VERSION "HNNBNNNYNNNNNNNNNNNNNNNNNNNNNNNNNNNNNNNNNN/4/%%%/4/'%**4NNN///"

NS_ :

BS_:

BU_: BAP_Tester Gateway_Max Getriebe_DQ Motor_konv Parksperre Schaltbetaetigung

BO_ 1171 MFG_01: 8 Gateway_Max
 SG_ MFG_01_CRC : 0|8@1+ (1,0) [0|255] ""  Motor_konv
 SG_ MFG_01_BZ : 8|4@1+ (1,0) [0|15] ""  Motor_konv
 SG_ MF_ZV_Lock : 12|1@1+ (1.0,0.0) [0.0|1] ""  Vector__XXX
 SG_ MF_Motorweiterlauf : 13|1@1+ (1.0,0.0) [0.0|1] ""  Vector__XXX
 SG_ MF_Abzugssperre : 14|1@1+ (1.0,0.0) [0.0|1] ""  Vector__XXX
 SG_ MF_Anlassersperre : 15|1@1+ (1.0,0.0) [0.0|1] ""  Motor_konv
 SG_ MF_Variante : 16|3@1+ (1.0,0.0) [0.0|7] ""  Vector__XXX
 SG_ MF_Schluessel_scan : 19|1@1+ (1.0,0.0) [0.0|1] ""  Vector__XXX
 SG_ MF_Laderelais : 20|1@1+ (1.0,0.0) [0.0|1] ""  Vector__XXX
 SG_ MF_StartStopp_Info : 21|2@1+ (1.0,0.0) [0.0|3] ""  Motor_konv
 SG_ MF_Fernbed_ein : 23|1@1+ (1.0,0.0) [0.0|1] ""  Vector__XXX
 SG_ MF_Standlicht : 24|1@1+ (1.0,0.0) [0.0|1] ""  Vector__XXX
 SG_ MF_Fahrlicht : 25|1@1+ (1.0,0.0) [0.0|1] ""  Vector__XXX
 SG_ MF_interm_Fernlicht : 26|1@1+ (1.0,0.0) [0.0|1] ""  Vector__XXX
 SG_ MF_Warnblinker : 27|1@1+ (1.0,0.0) [0.0|1] ""  Vector__XXX
 SG_ MF_Fussraumbel : 28|1@1+ (1.0,0.0) [0.0|1] ""  Vector__XXX
 SG_ MF_Innenraumbel : 29|1@1+ (1.0,0.0) [0.0|1] ""  Vector__XXX
 SG_ MF_Innenraumbel_Unterdrueck : 30|1@1+ (1.0,0.0) [0.0|1] ""  Vector__XXX
 SG_ MF_Notstart : 31|1@1+ (1.0,0.0) [0.0|1] ""  Vector__XXX
 SG_ MF_Blk_li : 32|1@1+ (1.0,0.0) [0.0|1] ""  Vector__XXX
 SG_ MF_Blk_re : 33|1@1+ (1.0,0.0) [0.0|1] ""  Vector__XXX
 SG_ MF_Lichthupe : 34|1@1+ (1.0,0.0) [0.0|1] ""  Vector__XXX
 SG_ MF_Fernlicht : 35|1@1+ (1.0,0.0) [0.0|1] ""  Vector__XXX
 SG_ MF_HFS_verriegeln : 36|1@1+ (1.0,0.0) [0.0|1] ""  Vector__XXX
 SG_ MF_HFS_entriegeln : 37|1@1+ (1.0,0.0) [0.0|1] ""  Vector__XXX
 SG_ MF_HBFS_verriegeln : 38|1@1+ (1.0,0.0) [0.0|1] ""  Vector__XXX
 SG_ MF_HBFS_entriegeln : 39|1@1+ (1.0,0.0) [0.0|1] ""  Vector__XXX
 SG_ MF_Tippwischen : 40|1@1+ (1.0,0.0) [0.0|1] ""  Vector__XXX
 SG_ MF_Frontintervall : 41|1@1+ (1.0,0.0) [0.0|1] ""  Vector__XXX
 SG_ MF_Wischerstufe_1 : 42|1@1+ (1.0,0.0) [0.0|1] ""  Vector__XXX
 SG_ MF_Wischerstufe_2 : 43|1@1+ (1.0,0.0) [0.0|1] ""  Vector__XXX
 SG_ MF_Frontwaschen : 44|1@1+ (1.0,0.0) [0.0|1] ""  Vector__XXX
 SG_ MF_nachtr_Stopp_Anf : 45|1@1+ (1.0,0.0) [0.0|1] ""  Motor_konv
 SG_ MF_Heckintervall : 46|1@1+ (1.0,0.0) [0.0|1] ""  Vector__XXX
 SG_ MF_Heckwaschen : 47|1@1+ (1.0,0.0) [0.0|1] ""  Vector__XXX
 SG_ MF_Summer : 48|1@1+ (1.0,0.0) [0.0|1] ""  Vector__XXX
 SG_ MF_Alarm_Blinkertakt : 49|1@1+ (1.0,0.0) [0.0|1] ""  Vector__XXX
 SG_ MF_Alarm_Blinker : 50|1@1+ (1.0,0.0) [0.0|1] ""  Vector__XXX
 SG_ MF_TFL_Abschaltung : 51|1@1+ (1.0,0.0) [0.0|1] ""  Vector__XXX
 SG_ MF_interm_Takt : 52|1@1+ (1.0,0.0) [0.0|1] ""  Vector__XXX
 SG_ MF_Tuerentriegelung_hinten : 53|1@1+ (1.0,0.0) [0.0|1] ""  Vector__XXX
 SG_ MF_interm_Fahrlicht : 54|1@1+ (1.0,0.0) [0.0|1] ""  Vector__XXX
 SG_ MF_Signalhorn : 55|1@1+ (1.0,0.0) [0.0|1] ""  Vector__XXX
 SG_ MF_FH_FT_hoch : 56|1@1+ (1.0,0.0) [0.0|1] ""  Vector__XXX
 SG_ MF_FH_FT_tief : 57|1@1+ (1.0,0.0) [0.0|1] ""  Vector__XXX
 SG_ MF_FH_BT_hoch : 58|1@1+ (1.0,0.0) [0.0|1] ""  Vector__XXX
 SG_ MF_FH_BT_tief : 59|1@1+ (1.0,0.0) [0.0|1] ""  Vector__XXX
 SG_ MF_FT_verriegeln : 60|1@1+ (1.0,0.0) [0.0|1] ""  Vector__XXX
 SG_ MF_FT_entriegeln : 61|1@1+ (1.0,0.0) [0.0|1] ""  Vector__XXX
 SG_ MF_BT_verriegeln : 62|1@1+ (1.0,0.0) [0.0|1] ""  Vector__XXX
 SG_ MF_BT_entriegeln : 63|1@1+ (1.0,0.0) [0.0|1] ""  Vector__XXX

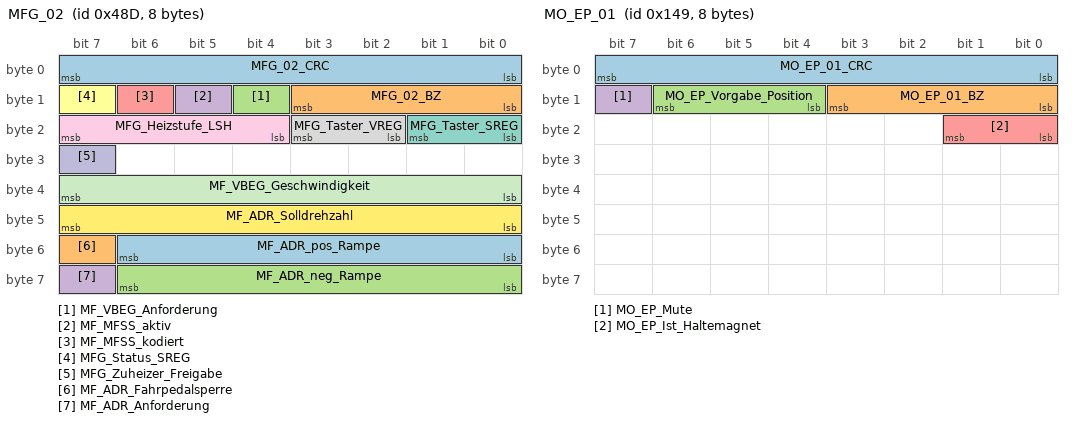
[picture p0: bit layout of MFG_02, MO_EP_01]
BO_ 1165 MFG_02: 8 Gateway_Max
 SG_ MFG_02_CRC : 0|8@1+ (1,0) [0|255] ""  Motor_konv
 SG_ MFG_02_BZ : 8|4@1+ (1,0) [0|15] ""  Motor_konv
 SG_ MF_VBEG_Anforderung : 12|1@1+ (1.0,0.0) [0.0|1] ""  Motor_konv
 SG_ MF_MFSS_aktiv : 13|1@1+ (1.0,0.0) [0.0|1] ""  Motor_konv
 SG_ MF_MFSS_kodiert : 14|1@1+ (1.0,0.0) [0.0|1] ""  Motor_konv
 SG_ MFG_Status_SREG : 15|1@1+ (1.0,0.0) [0.0|1] ""  Motor_konv
 SG_ MFG_Taster_SREG : 16|2@1+ (1.0,0.0) [0.0|3] ""  Motor_konv
 SG_ MFG_Taster_VREG : 18|2@1+ (1.0,0.0) [0.0|3] ""  Motor_konv
 SG_ MFG_Heizstufe_LSH : 20|4@1+ (1.0,0.0) [0.0|15] ""  Vector__XXX
 SG_ MFG_Zuheizer_Freigabe : 31|1@1+ (1.0,0.0) [0.0|1] ""  Vector__XXX
 SG_ MF_VBEG_Geschwindigkeit : 32|8@1+ (1,0) [0|254] "Unit_KiloMeterPerHour"  Motor_konv
 SG_ MF_ADR_Solldrehzahl : 40|8@1+ (20,0) [0|5100] "Unit_MinutInver"  Motor_konv
 SG_ MF_ADR_pos_Rampe : 48|7@1+ (10,0) [0|1000] ""  Motor_konv
 SG_ MF_ADR_Fahrpedalsperre : 55|1@1+ (1.0,0.0) [0.0|1] ""  Motor_konv
 SG_ MF_ADR_neg_Rampe : 56|7@1+ (10,0) [0|1000] ""  Motor_konv
 SG_ MF_ADR_Anforderung : 63|1@1+ (1.0,0.0) [0.0|1] ""  Motor_konv

BO_ 817 MFL_01: 8 Gateway_Max
 SG_ MFL_Zaehler : 0|4@1+ (1,0) [0|15] ""  Vector__XXX
 SG_ MFL_Toggle : 4|1@1+ (1,0) [0|1] ""  Vector__XXX
 SG_ MFL_Lokalaktiv : 5|1@1+ (1.0,0.0) [0.0|1] ""  Vector__XXX
 SG_ MFL_M_Taste : 6|1@1+ (1.0,0.0) [0.0|1] ""  Vector__XXX
 SG_ MFL_Paddle_Verbau : 7|1@1+ (1.0,0.0) [0.0|1] ""  Vector__XXX
 SG_ MFL_Tastencode_1 : 8|8@1+ (1.0,0.0) [0.0|255] ""  Vector__XXX
 SG_ MFL_Tastencode_2 : 16|8@1+ (1.0,0.0) [0.0|255] ""  Vector__XXX
 SG_ MFL_Eventcode_1 : 24|4@1+ (1.0,0.0) [0.0|15] ""  Vector__XXX
 SG_ MFL_Eventcode_2 : 28|4@1+ (1.0,0.0) [0.0|15] ""  Vector__XXX
 SG_ MFL_Marke : 32|4@1+ (1.0,0.0) [0.0|15] ""  Vector__XXX
 SG_ MFL_Variante : 36|4@1+ (1,0) [0|15] ""  Vector__XXX
 SG_ MFL_Touch_Event : 40|4@1+ (1.0,0.0) [0.0|15] ""  Vector__XXX
 SG_ MFL_Dummy_0_Signal_4 : 44|4@1+ (1.0,0.0) [0.0|15] ""  Vector__XXX
 SG_ MFL_Tip_Down : 48|1@1+ (1.0,0.0) [0.0|1] ""  Getriebe_DQ,Motor_konv
 SG_ MFL_Tip_Up : 49|1@1+ (1.0,0.0) [0.0|1] ""  Getriebe_DQ,Motor_konv
 SG_ MFL_SatModul_links_Err : 50|1@1+ (1.0,0.0) [0.0|1] ""  Vector__XXX
 SG_ MFL_SatModul_rechts_Err : 51|1@1+ (1.0,0.0) [0.0|1] ""  Vector__XXX
 SG_ MFL_Dummy_0_Signal_2 : 52|1@1+ (1.0,0.0) [0.0|1] ""  Vector__XXX
 SG_ MFL_Dummy_0_Signal_3 : 53|1@1+ (1.0,0.0) [0.0|1] ""  Vector__XXX
 SG_ MFL_LR_HZG_Status : 54|1@1+ (1.0,0.0) [0.0|1] ""  Vector__XXX
 SG_ MFL_LR_HZG_Err : 55|1@1+ (1.0,0.0) [0.0|1] ""  Vector__XXX
 SG_ MFL_Signalhorn : 56|1@1+ (1.0,0.0) [0.0|1] ""  Vector__XXX
 SG_ MFL_Signalhorn_Err : 57|1@1+ (1.0,0.0) [0.0|1] ""  Vector__XXX
 SG_ MFL_Tip_links_Err : 58|1@1+ (1.0,0.0) [0.0|1] ""  Getriebe_DQ
 SG_ MFL_Tip_rechts_Err : 59|1@1+ (1.0,0.0) [0.0|1] ""  Getriebe_DQ
 SG_ MFL_Taste_links_Err : 60|1@1+ (1.0,0.0) [0.0|1] ""  Vector__XXX
 SG_ MFL_Taste_rechts_Err : 61|1@1+ (1.0,0.0) [0.0|1] ""  Vector__XXX
 SG_ MFL_ECU_Err : 62|1@1+ (1.0,0.0) [0.0|1] ""  Vector__XXX
 SG_ MFL_Response_Err : 63|1@1+ (1.0,0.0) [0.0|1] ""  Vector__XXX

BO_ 329 MO_EP_01: 8 Getriebe_DQ
 SG_ MO_EP_01_CRC : 0|8@1+ (1,0) [0|255] ""  Parksperre
 SG_ MO_EP_01_BZ : 8|4@1+ (1,0) [0|15] ""  Parksperre
 SG_ MO_EP_Vorgabe_Position : 12|3@1+ (1.0,0.0) [0.0|7] ""  Parksperre
 SG_ MO_EP_Mute : 15|1@1+ (1.0,0.0) [0.0|1] ""  Parksperre
 SG_ MO_EP_Ist_Haltemagnet : 16|2@1+ (1.0,0.0) [0.0|3] ""  Vector__XXX

BO_ 15 MO_SOPC: 1 Motor_konv
 SG_ MO_SOPC : 0|1@1+ (1.0,0.0) [0.0|1] ""  Vector__XXX

BO_ 1600 Motor_07: 8 Motor_konv
 SG_ MO_QBit_Ansaugluft_Temp : 0|1@1+ (1.0,0.0) [0.0|1] ""  Gateway_Max,Getriebe_DQ
 SG_ MO_QBit_Oel_Temp : 1|1@1+ (1.0,0.0) [0.0|1] ""  Gateway_Max,Getriebe_DQ
 SG_ MO_QBit_Kuehlmittel_Temp : 2|1@1+ (1.0,0.0) [0.0|1] ""  Gateway_Max,Getriebe_DQ
 SG_ MO_KL15_Abschaltempfehlung : 3|1@1+ (1.0,0.0) [0.0|1] ""  Gateway_Max
 SG_ MO_HYB_Fehler_HV_Netz : 4|1@1+ (1.0,0.0) [0.0|1] ""  Gateway_Max
 SG_ MO_aktives_Getriebeheizen : 5|1@1+ (1.0,0.0) [0.0|1] ""  Gateway_Max
 SG_ MO_Absperrventil_oeffnen : 6|2@1+ (1.0,0.0) [0.0|3] ""  Gateway_Max,Getriebe_DQ
 SG_ MO_Ansaugluft_Temp : 8|8@1+ (0.75,-48) [-48.00|141.75] "Unit_DegreCelsi"  Gateway_Max,Getriebe_DQ
 SG_ MO_Oel_Temp : 16|8@1+ (1,-60) [-60|192] "Unit_DegreCelsi"  Gateway_Max,Getriebe_DQ
 SG_ MO_Kuehlmittel_Temp : 24|8@1+ (0.75,-48) [-48.00|141.75] "Unit_DegreCelsi"  Gateway_Max,Getriebe_DQ
 SG_ MO_Hoeheninfo : 32|8@1+ (0.00781,0) [0.00000|1.98374] ""  Gateway_Max,Getriebe_DQ
 SG_ MO_Kennfeldk : 40|1@1+ (1.0,0.0) [0.0|1] ""  Gateway_Max
 SG_ MO_Versionsinfo_02 : 41|5@1+ (1.0,0.0) [0.0|31] ""  Gateway_Max
 SG_ MO_QBit_Hoeheninfo : 46|1@1+ (1.0,0.0) [0.0|1] ""  Gateway_Max
 SG_ MO_Getriebe_kuehlen : 47|1@1+ (1.0,0.0) [0.0|1] ""  Gateway_Max,Getriebe_DQ
 SG_ MO_Mom_Traegheit_02 : 48|5@1+ (0.01,0) [0.00|0.31] "Unit_KiloGramMeterSquar"  Gateway_Max
 SG_ MO_Heizungspumpenansteuerung : 53|4@1+ (10,0) [0|100] "Unit_PerCent"  Gateway_Max
 SG_ MO_SpannungsAnf : 57|1@1+ (1.0,0.0) [0.0|1] ""  Gateway_Max
 SG_ MO_Nachlaufzeit_Heizungspumpe : 58|6@1+ (15,0) [0|945] "Unit_Secon"  Gateway_Max

BO_ 1607 Motor_09: 8 Motor_konv
 SG_ MO_ITM_Kuehlmittel_Temp : 0|8@1+ (0.75,-48) [-45.75|143.25] "Unit_DegreCelsi"  Gateway_Max
 SG_ MO_E85_Sensor : 8|4@1+ (10,0) [0|100] "Unit_PerCent"  Gateway_Max
 SG_ SCR_Anz_Motorstarts : 12|4@1+ (1.0,0.0) [0.0|15] ""  Gateway_Max
 SG_ SCR_Reichweite : 16|15@1+ (1,0) [0|32766] "Unit_KiloMeter"  Gateway_Max
 SG_ MO_Ethanol_Spuelhinweis : 31|1@1+ (1.0,0.0) [0.0|1] ""  Gateway_Max
 SG_ SCR_Warnstufe_1 : 32|1@1+ (1.0,0.0) [0.0|1] ""  Gateway_Max
 SG_ SCR_Warnstufe_2 : 33|1@1+ (1.0,0.0) [0.0|1] ""  Gateway_Max
 SG_ SCR_Text : 34|3@1+ (1.0,0.0) [0.0|7] ""  Gateway_Max
 SG_ SCR_Akustik : 37|2@1+ (1.0,0.0) [0.0|3] ""  Gateway_Max
 SG_ SCR_verbaut : 39|1@1+ (1.0,0.0) [0.0|1] ""  Gateway_Max
 SG_ MO_Kraftstofffilter_Wasser : 40|1@1+ (1.0,0.0) [0.0|1] ""  Gateway_Max
 SG_ SCR_Systemfehler : 41|1@1+ (1.0,0.0) [0.0|1] ""  Gateway_Max
 SG_ SCR_Inducement_Strategie : 42|2@1+ (1.0,0.0) [0.0|3] ""  Gateway_Max
 SG_ MO_CO2_Faktor : 44|12@1+ (1,0) [1|4094] "Unit_GramPerLiter"  Gateway_Max
 SG_ MO_MKB_MUX M  : 56|2@1+ (1.0,0.0) [0.0|3] ""  Gateway_Max
 SG_ MO_MKB_01 m0  : 59|5@1+ (1.0,0.0) [0.0|31] ""  Gateway_Max
 SG_ MO_MKB_02 m1  : 59|5@1+ (1.0,0.0) [0.0|31] ""  Gateway_Max
 SG_ MO_MKB_03 m2  : 59|5@1+ (1.0,0.0) [0.0|31] ""  Gateway_Max
 SG_ MO_MKB_04 m3  : 59|5@1+ (1.0,0.0) [0.0|31] ""  Gateway_Max

BO_ 958 Motor_14: 8 Motor_konv
 SG_ Motor_14_CRC : 0|8@1+ (1,0) [0|255] ""  Gateway_Max
 SG_ Motor_14_BZ : 8|4@1+ (1,0) [0|15] ""  Gateway_Max
 SG_ MO_StartStopp_Status : 12|2@1+ (1.0,0.0) [0.0|3] ""  Gateway_Max,Getriebe_DQ
 SG_ MO_StartStopp_Wiederstart : 14|1@1+ (1.0,0.0) [0.0|1] ""  Gateway_Max,Getriebe_DQ
 SG_ MO_StartStopp_Motorstopp : 15|1@1+ (1.0,0.0) [0.0|1] ""  Gateway_Max,Getriebe_DQ
 SG_ MO_Freig_Reku : 16|2@1+ (1.0,0.0) [0.0|3] ""  Gateway_Max
 SG_ MO_Kl_75 : 18|1@1+ (1.0,0.0) [0.0|1] ""  Gateway_Max
 SG_ MO_Kl_50 : 19|1@1+ (1.0,0.0) [0.0|1] ""  Gateway_Max,Getriebe_DQ
 SG_ MO_Gangposition : 20|4@1+ (1.0,0.0) [0.0|15] ""  Gateway_Max
 SG_ MO_StartStopp_Fahrerwunsch : 24|2@1+ (1.0,0.0) [0.0|3] ""  Gateway_Max,Getriebe_DQ
 SG_ MO_HYB_Fahrbereitschaft : 26|1@1+ (1.0,0.0) [0.0|1] ""  Gateway_Max
 SG_ MO_Ext_E_Fahrt_aktiv : 27|1@1+ (1.0,0.0) [0.0|1] ""  Gateway_Max
 SG_ MO_Fahrer_bremst : 28|1@1+ (1.0,0.0) [0.0|1] ""  Gateway_Max,Getriebe_DQ
 SG_ MO_QBit_Fahrer_bremst : 29|1@1+ (1.0,0.0) [0.0|1] ""  Gateway_Max,Getriebe_DQ
 SG_ MO_BLS : 30|1@1+ (1.0,0.0) [0.0|1] ""  Gateway_Max,Getriebe_DQ
 SG_ MO_Konsistenz_Bremsped : 31|1@1+ (1.0,0.0) [0.0|1] ""  Gateway_Max
 SG_ MO_Timeout_ESP : 32|1@1+ (1.0,0.0) [0.0|1] ""  Gateway_Max
 SG_ MO_Klima_Eingr : 33|2@1+ (1.0,0.0) [0.0|3] ""  Gateway_Max
 SG_ MO_Aussp_Anlass : 35|1@1+ (1.0,0.0) [0.0|1] ""  Gateway_Max
 SG_ MO_Freig_Anlass : 36|1@1+ (1.0,0.0) [0.0|1] ""  Gateway_Max
 SG_ MO_Kuppl_schalter : 37|1@1+ (1.0,0.0) [0.0|1] ""  Gateway_Max
 SG_ MO_Interlock : 38|1@1+ (1.0,0.0) [0.0|1] ""  Gateway_Max
 SG_ MO_Motor_laeuft : 39|1@1+ (1.0,0.0) [0.0|1] ""  Gateway_Max
 SG_ MO_Kickdown : 40|1@1+ (1.0,0.0) [0.0|1] ""  Gateway_Max,Getriebe_DQ
 SG_ MO_QBit_KL_75 : 41|1@1+ (1.0,0.0) [0.0|1] ""  Gateway_Max
 SG_ MO_EKlKomLeiRed : 42|2@1+ (1.0,0.0) [0.0|3] ""  Gateway_Max
 SG_ MO_Handshake_STH : 44|1@1+ (1.0,0.0) [0.0|1] ""  Gateway_Max
 SG_ MO_BKV_Unterdruckwarnung : 45|1@1+ (1.0,0.0) [0.0|1] ""  Gateway_Max
 SG_ MO_Freigabe_Segeln : 46|1@1+ (1.0,0.0) [0.0|1] ""  Gateway_Max,Getriebe_DQ
 SG_ MO_PTC_Status : 47|3@1+ (1.0,0.0) [0.0|7] ""  Gateway_Max
 SG_ MO_QBit_Gangposition : 50|1@1+ (1.0,0.0) [0.0|1] ""  Gateway_Max
 SG_ MO_Signalquelle_Gangposition : 51|1@1+ (1.0,0.0) [0.0|1] ""  Gateway_Max
 SG_ MO_Remotestart_Betrieb : 52|1@1+ (1.0,0.0) [0.0|1] ""  Gateway_Max
 SG_ MO_Remotestart_moeglich : 53|1@1+ (1.0,0.0) [0.0|1] ""  Gateway_Max
 SG_ MO_FMAus_aktiv : 55|1@1+ (1.0,0.0) [0.0|1] ""  Gateway_Max,Getriebe_DQ
 SG_ MO_FMAus_Startvariante : 56|2@1+ (1.0,0.0) [0.0|3] ""  Gateway_Max,Getriebe_DQ
 SG_ MO_BMS_NV_Anf_stuetzen : 58|1@1+ (1.0,0.0) [0.0|1] ""  Gateway_Max
 SG_ MO_Zylinderabschaltung : 59|2@1+ (1.0,0.0) [0.0|3] ""  Gateway_Max,Getriebe_DQ
 SG_ MO_HYB_VM_aktiv : 61|1@1+ (1.0,0.0) [0.0|1] ""  Gateway_Max
 SG_ MO_StartVorauss_erfuellt : 62|2@1+ (1.0,0.0) [0.0|3] ""  Gateway_Max

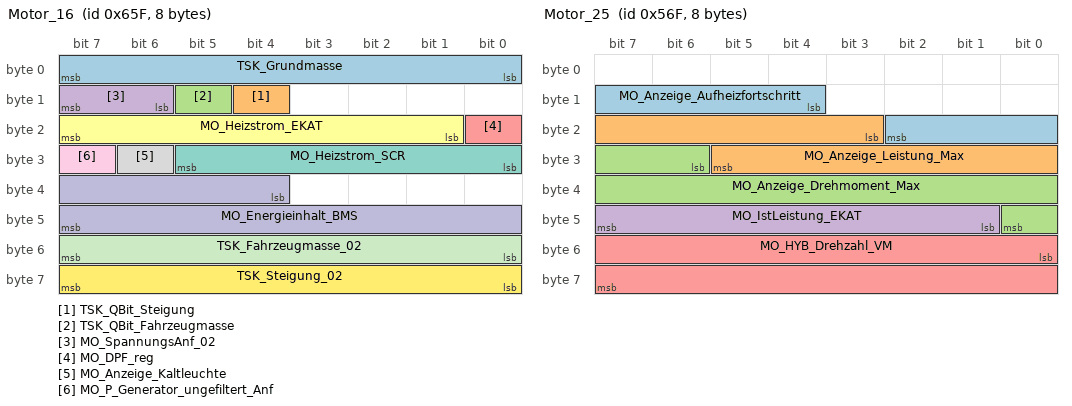
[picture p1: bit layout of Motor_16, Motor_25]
BO_ 1631 Motor_16: 8 Motor_konv
 SG_ TSK_Grundmasse : 0|8@1+ (32,0) [0|8128] "Unit_KiloGram"  Gateway_Max
 SG_ TSK_QBit_Steigung : 12|1@1+ (1.0,0.0) [0.0|1] ""  Gateway_Max
 SG_ TSK_QBit_Fahrzeugmasse : 13|1@1+ (1.0,0.0) [0.0|1] ""  Gateway_Max
 SG_ MO_SpannungsAnf_02 : 14|2@1+ (1.0,0.0) [0.0|3] ""  Gateway_Max
 SG_ MO_DPF_reg : 16|1@1+ (1.0,0.0) [0.0|1] ""  Gateway_Max
 SG_ MO_Heizstrom_EKAT : 17|7@1+ (1,0) [0|126] "Unit_Amper"  Gateway_Max
 SG_ MO_Heizstrom_SCR : 24|6@1+ (1,0) [0|62] "Unit_Amper"  Gateway_Max
 SG_ MO_Anzeige_Kaltleuchte : 30|1@1+ (1.0,0.0) [0.0|1] ""  Gateway_Max
 SG_ MO_P_Generator_ungefiltert_Anf : 31|1@1+ (1.0,0.0) [0.0|1] ""  Gateway_Max
 SG_ MO_Energieinhalt_BMS : 36|12@1+ (25,0) [0|102325] "Unit_WattHour"  Gateway_Max
 SG_ TSK_Fahrzeugmasse_02 : 48|8@1+ (32,0) [0|8128] "Unit_KiloGram"  Gateway_Max
 SG_ TSK_Steigung_02 : 56|8@1+ (0.8,-101.6) [-100.8|101.6] "Unit_PerCent"  Gateway_Max

BO_ 1648 Motor_18: 8 Motor_konv
 SG_ MO_max_Ladedruck : 0|6@1+ (0.1,0) [0.0|6.3] "Unit_Bar"  Gateway_Max
 SG_ MO_ANC_Kennfeld_Anf : 6|2@1+ (1.0,0.0) [0.0|3] ""  Gateway_Max
 SG_ MO_Bremslicht_Reku : 8|1@1+ (1.0,0.0) [0.0|1] ""  Gateway_Max
 SG_ MO_StartStopp_PopUp : 9|2@1+ (1.0,0.0) [0.0|3] ""  Gateway_Max
 SG_ MO1_Sperr_Info_WFS : 11|1@1+ (1.0,0.0) [0.0|1] ""  Gateway_Max
 SG_ MO1_Freigabe_Info_WFS : 12|1@1+ (1.0,0.0) [0.0|1] ""  Gateway_Max
 SG_ MO_EPCL : 13|3@1+ (1.0,0.0) [0.0|7] ""  Gateway_Max
 SG_ MO_Zylabsch_Texte_02 : 16|4@1+ (1.0,0.0) [0.0|15] ""  Gateway_Max
 SG_ MO_Fahrzeugtyp : 20|3@1+ (1.0,0.0) [0.0|7] ""  Gateway_Max
 SG_ MO_NMAX_Schaltanzeige : 23|9@1+ (25,0) [0|12775] "Unit_MinutInver"  Gateway_Max
 SG_ MO_Abstellzeit : 32|8@1+ (8,0) [0|2024] "Unit_Minut"  Gateway_Max
 SG_ MO_Abstellzeit_Status : 40|2@1+ (1.0,0.0) [0.0|3] ""  Gateway_Max
 SG_ MO1_Freigabe_Verfallsinfo_WFS : 42|1@1+ (1.0,0.0) [0.0|1] ""  Gateway_Max
 SG_ MO_Hybrid_StartStopp_LED : 43|2@1+ (1.0,0.0) [0.0|3] ""  Gateway_Max
 SG_ MO_Fehler_Zylabsch : 45|2@1+ (1.0,0.0) [0.0|3] ""  Gateway_Max
 SG_ MO_Anzahl_Abgesch_Zyl : 47|3@1+ (1.0,0.0) [0.0|7] ""  Gateway_Max
 SG_ MO_Zylabsch_Texte : 50|2@1+ (1.0,0.0) [0.0|3] ""  Gateway_Max
 SG_ MO_Ethanol_BS_Texte : 52|3@1+ (1.0,0.0) [0.0|7] ""  Gateway_Max
 SG_ MO_Drehzahl_Warnung : 55|1@1+ (1.0,0.0) [0.0|1] ""  Gateway_Max
 SG_ MO_obere_Drehzahlgrenze : 56|8@1+ (50,0) [50|12750] "Unit_MinutInver"  Gateway_Max

BO_ 1654 Motor_21: 8 Motor_konv
 SG_ StSt_Koord_Wiederstart_Anz_09 : 0|1@1+ (1.0,0.0) [0.0|1] ""  Gateway_Max
 SG_ StSt_Koord_Wiederstart_Anz_10 : 1|1@1+ (1.0,0.0) [0.0|1] ""  Gateway_Max
 SG_ StSt_Koord_Wiederstart_Anz_11 : 2|1@1+ (1.0,0.0) [0.0|1] ""  Gateway_Max
 SG_ MO_Wiederstart_Anz_01 : 12|1@1+ (1.0,0.0) [0.0|1] ""  Gateway_Max
 SG_ MO_Wiederstart_Anz_02 : 13|1@1+ (1.0,0.0) [0.0|1] ""  Gateway_Max
 SG_ MO_Wiederstart_Anz_03 : 14|1@1+ (1.0,0.0) [0.0|1] ""  Gateway_Max
 SG_ MO_Wiederstart_Anz_Std : 15|1@1+ (1.0,0.0) [0.0|1] ""  Gateway_Max
 SG_ MO_Stoppverbot_Anz_01 : 16|1@1+ (1.0,0.0) [0.0|1] ""  Gateway_Max
 SG_ MO_Stoppverbot_Anz_02 : 17|1@1+ (1.0,0.0) [0.0|1] ""  Gateway_Max
 SG_ MO_Stoppverbot_Anz_03 : 18|1@1+ (1.0,0.0) [0.0|1] ""  Gateway_Max
 SG_ MO_Stoppverbot_Anz_04 : 19|1@1+ (1.0,0.0) [0.0|1] ""  Gateway_Max
 SG_ MO_Stoppverbot_Anz_05 : 20|1@1+ (1.0,0.0) [0.0|1] ""  Gateway_Max
 SG_ MO_Stoppverbot_Anz_06 : 21|1@1+ (1.0,0.0) [0.0|1] ""  Gateway_Max
 SG_ MO_Stoppverbot_Anz_07 : 22|1@1+ (1.0,0.0) [0.0|1] ""  Gateway_Max
 SG_ MO_Stoppverbot_Anz_08 : 23|1@1+ (1.0,0.0) [0.0|1] ""  Gateway_Max
 SG_ MO_Stoppverbot_Anz_09 : 24|1@1+ (1.0,0.0) [0.0|1] ""  Gateway_Max
 SG_ MO_Stoppverbot_Anz_10 : 25|1@1+ (1.0,0.0) [0.0|1] ""  Gateway_Max
 SG_ MO_Stoppverbot_Anz_11 : 26|1@1+ (1.0,0.0) [0.0|1] ""  Gateway_Max
 SG_ MO_Stoppverbot_Anz_Std : 27|1@1+ (1.0,0.0) [0.0|1] ""  Gateway_Max
 SG_ StSt_Koord_Stoppverbot_Anz_20 : 28|1@1+ (1.0,0.0) [0.0|1] ""  Gateway_Max
 SG_ StSt_Koord_Stoppverbot_Anz_21 : 29|1@1+ (1.0,0.0) [0.0|1] ""  Gateway_Max
 SG_ StSt_Koord_Wiederstart_Anz_Std : 30|1@1+ (1.0,0.0) [0.0|1] ""  Gateway_Max
 SG_ StSt_Koord_Status_Bremspedalkzpt : 31|1@1+ (1.0,0.0) [0.0|1] ""  Gateway_Max
 SG_ StSt_Koord_Wiederstart_Anz_01 : 32|1@1+ (1.0,0.0) [0.0|1] ""  Gateway_Max
 SG_ StSt_Koord_Wiederstart_Anz_02 : 33|1@1+ (1.0,0.0) [0.0|1] ""  Gateway_Max
 SG_ StSt_Koord_Wiederstart_Anz_03 : 34|1@1+ (1.0,0.0) [0.0|1] ""  Gateway_Max
 SG_ StSt_Koord_Wiederstart_Anz_04 : 35|1@1+ (1.0,0.0) [0.0|1] ""  Gateway_Max
 SG_ StSt_Koord_Wiederstart_Anz_05 : 36|1@1+ (1.0,0.0) [0.0|1] ""  Gateway_Max
 SG_ StSt_Koord_Wiederstart_Anz_06 : 37|1@1+ (1.0,0.0) [0.0|1] ""  Gateway_Max
 SG_ StSt_Koord_Wiederstart_Anz_07 : 38|1@1+ (1.0,0.0) [0.0|1] ""  Gateway_Max
 SG_ StSt_Koord_Wiederstart_Anz_08 : 39|1@1+ (1.0,0.0) [0.0|1] ""  Gateway_Max
 SG_ StSt_Koord_Stoppverbot_Anz_01 : 40|1@1+ (1.0,0.0) [0.0|1] ""  Gateway_Max
 SG_ StSt_Koord_Stoppverbot_Anz_02 : 41|1@1+ (1.0,0.0) [0.0|1] ""  Gateway_Max
 SG_ StSt_Koord_Stoppverbot_Anz_03 : 42|1@1+ (1.0,0.0) [0.0|1] ""  Gateway_Max
 SG_ StSt_Koord_Stoppverbot_Anz_04 : 43|1@1+ (1.0,0.0) [0.0|1] ""  Gateway_Max
 SG_ StSt_Koord_Stoppverbot_Anz_05 : 44|1@1+ (1.0,0.0) [0.0|1] ""  Gateway_Max
 SG_ StSt_Koord_Stoppverbot_Anz_06 : 45|1@1+ (1.0,0.0) [0.0|1] ""  Gateway_Max
 SG_ StSt_Koord_Stoppverbot_Anz_07 : 46|1@1+ (1.0,0.0) [0.0|1] ""  Gateway_Max
 SG_ StSt_Koord_Stoppverbot_Anz_08 : 47|1@1+ (1.0,0.0) [0.0|1] ""  Gateway_Max
 SG_ StSt_Koord_Stoppverbot_Anz_09 : 48|1@1+ (1.0,0.0) [0.0|1] ""  Gateway_Max
 SG_ StSt_Koord_Stoppverbot_Anz_10 : 49|1@1+ (1.0,0.0) [0.0|1] ""  Gateway_Max
 SG_ StSt_Koord_Stoppverbot_Anz_11 : 50|1@1+ (1.0,0.0) [0.0|1] ""  Gateway_Max
 SG_ StSt_Koord_Stoppverbot_Anz_12 : 51|1@1+ (1.0,0.0) [0.0|1] ""  Gateway_Max
 SG_ StSt_Koord_Stoppverbot_Anz_13 : 52|1@1+ (1.0,0.0) [0.0|1] ""  Gateway_Max
 SG_ StSt_Koord_Stoppverbot_Anz_14 : 53|1@1+ (1.0,0.0) [0.0|1] ""  Gateway_Max
 SG_ StSt_Koord_Stoppverbot_Anz_15 : 54|1@1+ (1.0,0.0) [0.0|1] ""  Gateway_Max
 SG_ StSt_Koord_Stoppverbot_Anz_16 : 55|1@1+ (1.0,0.0) [0.0|1] ""  Gateway_Max
 SG_ StSt_Koord_Stoppverbot_Anz_17 : 56|1@1+ (1.0,0.0) [0.0|1] ""  Gateway_Max
 SG_ StSt_Koord_Stoppverbot_Anz_Std : 57|1@1+ (1.0,0.0) [0.0|1] ""  Gateway_Max
 SG_ StSt_Koord_Stoppverbot_Anz_18 : 58|1@1+ (1.0,0.0) [0.0|1] ""  Gateway_Max
 SG_ StSt_Koord_Stoppverbot_Anz_19 : 59|1@1+ (1.0,0.0) [0.0|1] ""  Gateway_Max
 SG_ MO_StaGluehk : 60|4@1+ (8,0) [0|112] "Unit_PerCent"  Vector__XXX

BO_ 1391 Motor_25: 8 Motor_konv
 SG_ MO_Anzeige_Aufheizfortschritt : 12|7@1+ (1,0) [0|100] "Unit_PerCent"  Gateway_Max
 SG_ MO_Anzeige_Leistung_Max : 19|11@1+ (0.6,0) [0.0|1227.0] "Unit_KiloWatt"  Gateway_Max
 SG_ MO_Anzeige_Drehmoment_Max : 30|11@1+ (1,0) [0|2045] "Unit_NewtoMeter"  Gateway_Max
 SG_ MO_IstLeistung_EKAT : 41|7@1+ (20,0) [0|2500] "Unit_Watt"  Gateway_Max
 SG_ MO_HYB_Drehzahl_VM : 48|16@1+ (0.25,0) [0.00|16256.00] "Unit_MinutInver"  Gateway_Max

BO_ 967 Motor_26: 8 Motor_konv
 SG_ MO_Kuehlerluefter_MUX M  : 0|1@1+ (1.0,0.0) [0.0|1] ""  Gateway_Max,Getriebe_DQ
 SG_ MO_Kuehlerluefter_1 m0  : 1|7@1+ (1,0) [0|100] "Unit_PerCent"  Gateway_Max,Getriebe_DQ
 SG_ MO_Kuehlerluefter_2 m1  : 1|7@1+ (1,0) [0|100] "Unit_PerCent"  Gateway_Max,Getriebe_DQ
 SG_ MO_EFLEX_Lampe : 8|2@1+ (1.0,0.0) [0.0|3] ""  Gateway_Max
 SG_ MO_KJS_nicht_bereit : 10|1@1+ (1.0,0.0) [0.0|1] ""  Gateway_Max
 SG_ MO_ITM_Warnung_Pumpe : 11|1@1+ (1.0,0.0) [0.0|1] ""  Gateway_Max
 SG_ WIV_Anzeige_aktiv : 12|1@1+ (1.0,0.0) [0.0|1] ""  Gateway_Max
 SG_ WIV_Oelmin_Warn : 13|1@1+ (1.0,0.0) [0.0|1] ""  Gateway_Max
 SG_ WIV_Sensorfehler : 14|1@1+ (1.0,0.0) [0.0|1] ""  Gateway_Max
 SG_ WIV_Schieflage : 15|1@1+ (1.0,0.0) [0.0|1] ""  Gateway_Max
 SG_ WIV_Oelstand : 16|4@1+ (12.5,0) [0.0|100.0] "Unit_PerCent"  Gateway_Max
 SG_ MO_Zustand_HWP : 20|2@1+ (1.0,0.0) [0.0|3] ""  Gateway_Max
 SG_ OLEV_Systemstoerung : 22|1@1+ (1.0,0.0) [0.0|1] ""  Gateway_Max
 SG_ MO_Oelwarnung_max : 23|1@1+ (1.0,0.0) [0.0|1] ""  Gateway_Max
 SG_ WIV_Oelsystem_aktiv : 24|1@1+ (1.0,0.0) [0.0|1] ""  Gateway_Max
 SG_ WIV_nicht_betriebswarm : 25|1@1+ (1.0,0.0) [0.0|1] ""  Gateway_Max
 SG_ WIV_Ueberfuell_Warn : 26|1@1+ (1.0,0.0) [0.0|1] ""  Gateway_Max
 SG_ WIV_laufender_Motor : 27|1@1+ (1.0,0.0) [0.0|1] ""  Gateway_Max
 SG_ MO_E_Warnungen : 28|4@1+ (1.0,0.0) [0.0|15] ""  Gateway_Max
 SG_ MO_Text_Motorstart : 32|4@1+ (1.0,0.0) [0.0|15] ""  Gateway_Max
 SG_ MO_E_Texte : 36|4@1+ (1.0,0.0) [0.0|15] ""  Gateway_Max
 SG_ WIV_Oeldyn_avl : 40|1@1+ (1.0,0.0) [0.0|1] ""  Gateway_Max
 SG_ MO_Text_Partikelfil_Reg : 41|1@1+ (1,0) [0|1] ""  Gateway_Max
 SG_ OLEV_Oelstand_nicht_vorhanden : 42|1@1+ (1.0,0.0) [0.0|1] ""  Gateway_Max
 SG_ WIV_Oelmenge : 43|5@1+ (125,0) [0|3875] "Unit_MilliLiter"  Gateway_Max
 SG_ MO_Systemlampe : 48|1@1+ (1.0,0.0) [0.0|1] ""  Gateway_Max
 SG_ MO_OBD2_Lampe : 49|1@1+ (1.0,0.0) [0.0|1] ""  Gateway_Max
 SG_ MO_Heissleuchte : 50|1@1+ (1.0,0.0) [0.0|1] ""  Gateway_Max
 SG_ MO_Partikel_Lampe : 51|1@1+ (1.0,0.0) [0.0|1] ""  Gateway_Max
 SG_ MO_RedFahrleistung_Lampe : 52|1@1+ (1.0,0.0) [0.0|1] ""  Gateway_Max
 SG_ WIV_Oelstand_nicht_vorhanden : 53|1@1+ (1.0,0.0) [0.0|1] ""  Gateway_Max
 SG_ WIV_nachfuellanzeige_ein : 54|1@1+ (1.0,0.0) [0.0|1] ""  Gateway_Max
 SG_ WIV_Ueberfuell_deaktiv : 55|1@1+ (1.0,0.0) [0.0|1] ""  Gateway_Max
 SG_ WIV_Unterfuell_Warn : 56|1@1+ (1.0,0.0) [0.0|1] ""  Gateway_Max
 SG_ MO_Tankdeckel_Lampe : 57|1@1+ (1.0,0.0) [0.0|1] ""  Gateway_Max
 SG_ MO_Text_Tankdeckelwarn : 58|1@1+ (1.0,0.0) [0.0|1] ""  Gateway_Max
 SG_ MO_Vorglueh_Lampe : 59|1@1+ (1.0,0.0) [0.0|1] ""  Gateway_Max
 SG_ WIV_Oeldr_Warn_Motor : 60|1@1+ (1.0,0.0) [0.0|1] ""  Gateway_Max
 SG_ MO_E_Mode : 61|3@1+ (1.0,0.0) [0.0|7] ""  Gateway_Max

BO_ 966 Motor_26_SOK_Signatur: 8 Motor_konv
 SG_ SOK_Motor_26_Signatur : 0|64@1+ (1,0) [0|18446744073709551615] ""  Gateway_Max

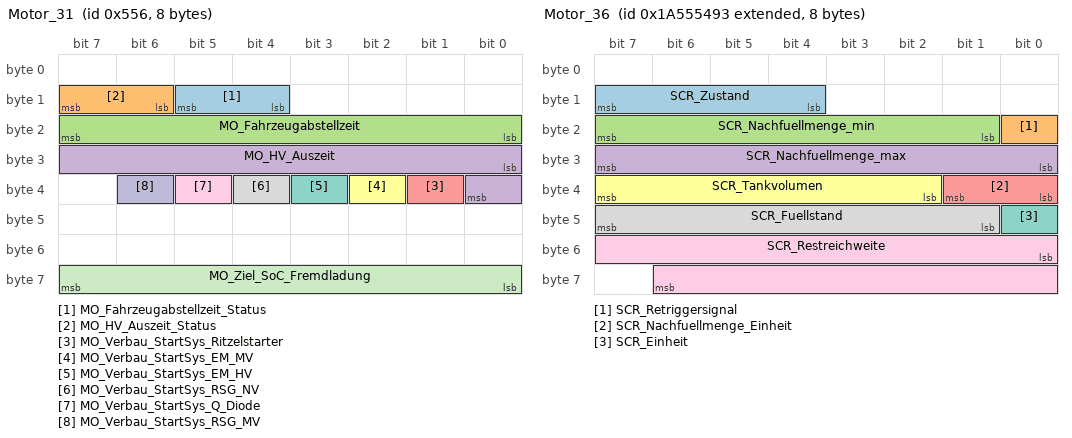
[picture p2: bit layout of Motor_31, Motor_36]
BO_ 1366 Motor_31: 8 Motor_konv
 SG_ MO_Fahrzeugabstellzeit_Status : 12|2@1+ (1.0,0.0) [0.0|3] ""  Gateway_Max
 SG_ MO_HV_Auszeit_Status : 14|2@1+ (1.0,0.0) [0.0|3] ""  Gateway_Max
 SG_ MO_Fahrzeugabstellzeit : 16|8@1+ (8,0) [0|2024] "Unit_Minut"  Gateway_Max
 SG_ MO_HV_Auszeit : 24|9@1+ (4,0) [0|2036] "Unit_Minut"  Gateway_Max
 SG_ MO_Verbau_StartSys_Ritzelstarter : 33|1@1+ (1.0,0.0) [0.0|1] ""  Gateway_Max
 SG_ MO_Verbau_StartSys_EM_MV : 34|1@1+ (1.0,0.0) [0.0|1] ""  Gateway_Max
 SG_ MO_Verbau_StartSys_EM_HV : 35|1@1+ (1.0,0.0) [0.0|1] ""  Gateway_Max
 SG_ MO_Verbau_StartSys_RSG_NV : 36|1@1+ (1.0,0.0) [0.0|1] ""  Gateway_Max
 SG_ MO_Verbau_StartSys_Q_Diode : 37|1@1+ (1.0,0.0) [0.0|1] ""  Gateway_Max
 SG_ MO_Verbau_StartSys_RSG_MV : 38|1@1+ (1.0,0.0) [0.0|1] ""  Gateway_Max
 SG_ MO_Ziel_SoC_Fremdladung : 56|8@1+ (0.4,0) [0.0|100.0] "Unit_PerCent"  Gateway_Max

BO_ 2589283475 Motor_36: 8 Motor_konv
 SG_ SCR_Zustand : 12|4@1+ (1.0,0.0) [0.0|15] ""  Gateway_Max
 SG_ SCR_Retriggersignal : 16|1@1+ (1.0,0.0) [0.0|1] ""  Gateway_Max
 SG_ SCR_Nachfuellmenge_min : 17|7@1+ (0.25,0) [0.00|31.50] ""  Gateway_Max
 SG_ SCR_Nachfuellmenge_max : 24|8@1+ (0.25,0) [0.00|63.50] ""  Gateway_Max
 SG_ SCR_Nachfuellmenge_Einheit : 32|2@1+ (1.0,0.0) [0.0|3] ""  Gateway_Max
 SG_ SCR_Tankvolumen : 34|6@1+ (1,0) [0|63] ""  Gateway_Max
 SG_ SCR_Einheit : 40|1@1+ (1.0,0.0) [0.0|1] ""  Gateway_Max
 SG_ SCR_Fuellstand : 41|7@1+ (1,0) [0|100] "Unit_PerCent"  Gateway_Max
 SG_ SCR_Restreichweite : 48|15@1+ (1,0) [0|32767] ""  Gateway_Max

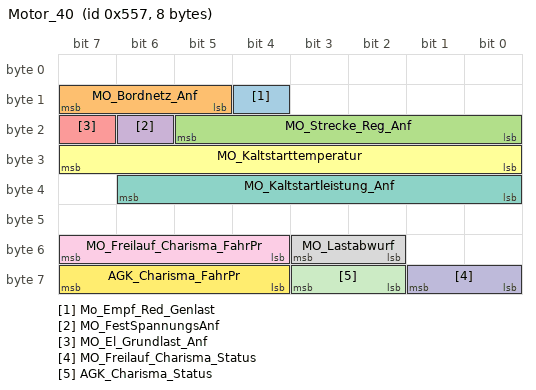
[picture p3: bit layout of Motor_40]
BO_ 1367 Motor_40: 8 Motor_konv
 SG_ Mo_Empf_Red_Genlast : 12|1@1+ (1.0,0.0) [0.0|1] ""  Gateway_Max
 SG_ MO_Bordnetz_Anf : 13|3@1+ (1.0,0.0) [0.0|7] ""  Gateway_Max
 SG_ MO_Strecke_Reg_Anf : 16|6@1+ (1,0) [0|62] "Unit_KiloMeter"  Gateway_Max
 SG_ MO_FestSpannungsAnf : 22|1@1+ (1.0,0.0) [0.0|1] ""  Gateway_Max
 SG_ MO_El_Grundlast_Anf : 23|1@1+ (1.0,0.0) [0.0|1] ""  Gateway_Max
 SG_ MO_Kaltstarttemperatur : 24|8@1+ (0.5,-40) [-40.0|86.5] "Unit_DegreCelsi"  Gateway_Max
 SG_ MO_Kaltstartleistung_Anf : 32|7@1+ (100,0) [0|12500] "Unit_Watt"  Gateway_Max
 SG_ MO_Lastabwurf : 50|2@1+ (1.0,0.0) [0.0|3] ""  Gateway_Max
 SG_ MO_Freilauf_Charisma_FahrPr : 52|4@1+ (1.0,0.0) [0.0|15] ""  Gateway_Max
 SG_ MO_Freilauf_Charisma_Status : 56|2@1+ (1.0,0.0) [0.0|3] ""  Gateway_Max
 SG_ AGK_Charisma_Status : 58|2@1+ (1.0,0.0) [0.0|3] ""  Gateway_Max
 SG_ AGK_Charisma_FahrPr : 60|4@1+ (1.0,0.0) [0.0|15] ""  Gateway_Max

BO_ 706 Motor_41: 8 Motor_konv
 SG_ MO_Anzeige_StSt_Text : 12|4@1+ (1.0,0.0) [0.0|15] ""  Gateway_Max
 SG_ MO_Anzeige_StSt_Symbol : 16|3@1+ (1.0,0.0) [0.0|7] ""  Gateway_Max
 SG_ MO_ADR_Status : 19|2@1+ (1.0,0.0) [0.0|3] ""  Gateway_Max
 SG_ MO_AGA_Sound_Texte : 21|2@1+ (1.0,0.0) [0.0|3] ""  Gateway_Max
 SG_ MO_Anzeige_FMAus_Text : 23|1@1+ (1.0,0.0) [0.0|1] ""  Gateway_Max
 SG_ MO_KEF_Status : 24|1@1+ (1.0,0.0) [0.0|1] ""  Gateway_Max
 SG_ PEA_Texte : 25|3@1+ (1.0,0.0) [0.0|7] ""  Gateway_Max
 SG_ TSK_Ueberstimmt_vMax_FahrerInfo : 28|2@1+ (1.0,0.0) [0.0|3] ""  Gateway_Max
 SG_ MO_VREG_Status : 30|2@1+ (1.0,0.0) [0.0|3] ""  Gateway_Max
 SG_ MO_Rekuperationsstufe : 32|3@1+ (1.0,0.0) [0.0|7] ""  Gateway_Max
 SG_ TSK_Einheit_vMax_FahrerInfo : 35|1@1+ (1.0,0.0) [0.0|1] ""  Gateway_Max
 SG_ TSK_Status_vMax_FahrerInfo : 36|2@1+ (1.0,0.0) [0.0|3] ""  Gateway_Max
 SG_ MO_SREG_Status : 38|3@1+ (1.0,0.0) [0.0|7] ""  Gateway_Max
 SG_ MO_SREG_Beladung : 41|6@1+ (2,0) [0|122] "Unit_PerCent"  Gateway_Max
 SG_ MO_Anz_Kuehlerluefter : 47|3@1+ (1.0,0.0) [0.0|7] ""  Gateway_Max
 SG_ MO_EM_Ueberhitzungswarnung : 52|2@1+ (1.0,0.0) [0.0|3] ""  Gateway_Max
 SG_ MO_ElAntrieb_Abschleppwarnung : 54|2@1+ (1.0,0.0) [0.0|3] ""  Gateway_Max
 SG_ TSK_vMax_FahrerInfo : 56|8@1+ (1,15) [16|270] ""  Gateway_Max

BO_ 269 Motor_50: 48 Motor_konv
 SG_ Motor_50_CRC : 0|8@1+ (1,0) [0|255] ""  Gateway_Max,Getriebe_DQ
 SG_ Motor_50_BZ : 8|4@1+ (1,0) [0|15] ""  Gateway_Max,Getriebe_DQ
 SG_ MO_Mom_Soll_Roh : 12|10@1+ (1,-509) [-509|509] ""  Gateway_Max,Getriebe_DQ
 SG_ MO_Mom_Ist_Summe : 22|10@1+ (1,-509) [-509|509] ""  Gateway_Max,Getriebe_DQ
 SG_ MO_Mom_Traegheit_Summe : 32|10@1+ (1,-509) [-509|509] ""  Gateway_Max
 SG_ MO_Mom_Soll_gefiltert : 42|10@1+ (1,-509) [-509|509] ""  Gateway_Max,Getriebe_DQ
 SG_ MO_Mom_Schub : 52|9@1+ (1,-509) [-509|0] ""  Gateway_Max,Getriebe_DQ
 SG_ MO_Status_Normalbetrieb_01 : 61|1@1+ (1.0,0.0) [0.0|1] ""  Gateway_Max,Getriebe_DQ
 SG_ MO_erste_Ungenauschwelle : 62|1@1+ (1.0,0.0) [0.0|1] ""  Gateway_Max
 SG_ MO_QBit_Motormomente : 63|1@1+ (1.0,0.0) [0.0|1] ""  Gateway_Max,Getriebe_DQ
 SG_ MO_Mom_neg_verfuegbar : 76|9@1+ (1,-509) [-509|0] ""  Gateway_Max,Getriebe_DQ
 SG_ MO_Mom_Begr_Fahr : 85|9@1+ (1,0) [0|509] ""  Gateway_Max,Getriebe_DQ
 SG_ MO_Mom_Begr_Schalt : 94|10@1+ (1,-509) [-509|509] ""  Gateway_Max,Getriebe_DQ
 SG_ MO_Momentenintegral_02 : 104|7@1+ (1,0) [0|100] "Unit_PerCent"  Gateway_Max,Getriebe_DQ
 SG_ MO_QBit_Drehzahl_01 : 111|1@1+ (1.0,0.0) [0.0|1] ""  Gateway_Max,Getriebe_DQ
 SG_ MO_Drehzahl_01 : 112|16@1+ (0.25,0) [0.00|16383.00] "Unit_MinutInver"  Gateway_Max,Getriebe_DQ
 SG_ MO_HYB_EMode_Info : 142|2@1+ (1.0,0.0) [0.0|3] ""  Gateway_Max
 SG_ MO_HYB_max_ind_VM_Mom_02 : 144|8@1+ (1.186,0) [0.000|300.058] "Unit_NewtoMeter"  Gateway_Max
 SG_ MO_HYB_Zielzustand : 152|3@1+ (1.0,0.0) [0.0|7] ""  Gateway_Max
 SG_ MO_HYB_Modus_Ankopplung_VM : 155|1@1+ (1.0,0.0) [0.0|1] ""  Gateway_Max
 SG_ MO_HYB_Freigabe_VM_Eingr : 156|2@1+ (1.0,0.0) [0.0|3] ""  Gateway_Max
 SG_ MO_HYB_Sollstatus_K0 : 158|1@1+ (1.0,0.0) [0.0|1] ""  Gateway_Max
 SG_ MO_HYB_Komfortstufe : 159|1@1+ (1.0,0.0) [0.0|1] ""  Gateway_Max
 SG_ MO_HYB_VM_bereit : 160|1@1+ (1.0,0.0) [0.0|1] ""  Gateway_Max
 SG_ MO_HYB_Stoppmodus : 161|1@1+ (1.0,0.0) [0.0|1] ""  Gateway_Max
 SG_ MO_HYB_LowSpeedModus : 162|1@1+ (1.0,0.0) [0.0|1] ""  Gateway_Max
 SG_ MO_HYB_Schaltverhinderung : 163|1@1+ (1.0,0.0) [0.0|1] ""  Gateway_Max
 SG_ MO_HYB_E_Faktor : 164|4@1+ (1.0,0.0) [0.0|15] ""  Gateway_Max
 SG_ MO_HYB_VM_Mom_oE_02 : 168|8@1+ (1.186,-50) [-50.000|250.058] "Unit_NewtoMeter"  Gateway_Max
 SG_ MO_Drehzahl_VM : 176|16@1+ (0.25,0) [0.00|16383.00] "Unit_MinutInver"  Gateway_Max
 SG_ MO_EM1_SollDrehzahl : 192|15@1+ (1,-10000) [-10000|22766] "Unit_MinutInver"  Gateway_Max
 SG_ MO_Luftpfad_Verzugszeit_praed : 207|5@1+ (10,0) [10|310] "Unit_MilliSecon"  Gateway_Max,Getriebe_DQ
 SG_ MO_EM2_SollDrehzahl : 212|15@1+ (1,-10000) [-10000|22766] "Unit_MinutInver"  Gateway_Max
 SG_ MO_TNW_Min_Strom_Lim : 227|13@1+ (0.5,-2047) [-2047.0|2047.5] "Unit_Amper"  Gateway_Max
 SG_ MO_TNW_Max_Strom_Lim : 240|13@1+ (0.5,-2047) [-2047.0|2047.5] "Unit_Amper"  Gateway_Max

CM_ BO_ 1171 "ab MQB 7.2 gültig";
CM_ BO_ 1600 "ab MQB mit QBit Höheneinfo und MO_Versionsinfo_02";
CM_ BO_ 1648 "Kombischnittstelle";
CM_ BO_ 967 "MQB - vorher Motor_06 / Umbenennung wg. ID-Wechsel";

CM_ SG_ 1171 MF_Abzugssperre "Schlüsselabzugssperre";
CM_ SG_ 1171 MF_Alarm_Blinker "Taxialarmblinken, wie DWA ohne Fanfare";
CM_ SG_ 1171 MF_Alarm_Blinkertakt "Ansteuerung Blinker bei Alarm. Signal wird getaktet.
0 = Blinker für Alarm aus
1 = Blinker für Alarm ein";
CM_ SG_ 1171 MF_Anlassersperre "Notarzt 230V-Steckdose";
CM_ SG_ 1171 MF_Blk_li "Versehrte oder Fahrschule; Prio über Fernbedienung ein";
CM_ SG_ 1171 MF_Blk_re "Versehrte oder Fahrschule; Prio über Fernbedienung ein";
CM_ SG_ 1171 MF_BT_entriegeln "Beifahrertür entriegeln";
CM_ SG_ 1171 MF_BT_verriegeln "Beifahrertür verriegeln";
CM_ SG_ 1171 MF_Fahrlicht "statisch oder auch mit Blink_modi für interm.  Fahrlicht";
CM_ SG_ 1171 MF_Fernbed_ein "Fernbedienung für Petri+Lehr; Versehrte und Fahrschule";
CM_ SG_ 1171 MF_Fernlicht "Versehrte oder Fahrschule; Oder-Verknüpfung";
CM_ SG_ 1171 MF_FH_BT_hoch "Versehrte";
CM_ SG_ 1171 MF_FH_BT_tief "Versehrte";
CM_ SG_ 1171 MF_FH_FT_hoch "Versehrte";
CM_ SG_ 1171 MF_FH_FT_tief "Versehrte";
CM_ SG_ 1171 MF_Frontintervall "Versehrte oder Fahrschule; Oder-Verknüpfung";
CM_ SG_ 1171 MF_Frontwaschen "Versehrte oder Fahrschule; Oder-Verknüpfung";
CM_ SG_ 1171 MF_FT_entriegeln "Fahrertür entriegeln";
CM_ SG_ 1171 MF_FT_verriegeln "Fahrertür verriegeln";
CM_ SG_ 1171 MF_Fussraumbel "Fussraumbeleuchtung, Fahrschule";
CM_ SG_ 1171 MF_HBFS_entriegeln "Hinten Beifahrertür entriegeln";
CM_ SG_ 1171 MF_HBFS_verriegeln "Hinten Beifahrertür verriegeln";
CM_ SG_ 1171 MF_Heckintervall "Versehrte oder Fahrschule; Oder-Verknüpfung";
CM_ SG_ 1171 MF_Heckwaschen "Versehrte oder Fahrschule; Oder-Verknüpfung";
CM_ SG_ 1171 MF_HFS_entriegeln "Hinten Fahrertür entriegeln";
CM_ SG_ 1171 MF_HFS_verriegeln "Hinten Fahrertür verriegeln";
CM_ SG_ 1171 MF_Innenraumbel "sämtliche Beleuchtungen akitivieren (Fussraum, Tür u.a.)";
CM_ SG_ 1171 MF_Innenraumbel_Unterdrueck "Unterdrückung des Innenlichts/Fussraumbeleuchtung, sowie Schließblinken";
CM_ SG_ 1171 MF_interm_Fahrlicht "Ansteuerung intermittierendes Abblendlicht";
CM_ SG_ 1171 MF_interm_Fernlicht "mit Blink_modi für SoSi oder Taxialarm";
CM_ SG_ 1171 MF_interm_Takt "Taktung von intermittierenden Fernlicht/Fahrlicht bei einer Einsatzfahrt
0 = Licht aus
1 = Licht ein";
CM_ SG_ 1171 MF_Laderelais "Signal für die Auswertung zur Anzeige der Batterie-Schwach-Anzeige im Kombi";
CM_ SG_ 1171 MF_Lichthupe "Versehrte oder Fahrschule; Oder-Verknuepfung
";
CM_ SG_ 1171 MF_Motorweiterlauf "Motorstop Behoerdenfahrzeug";
CM_ SG_ 1171 MF_nachtr_Stopp_Anf "Dieses Signal dient dem Motor als Trigger, dass ein nachträglicher Motorstopp eingeleitet werden kann, wenn es die Bedingungen des StSt Koordinators dies zulassen.";
CM_ SG_ 1171 MF_Notstart "Signal zeigt an, dass ein Notstart über DBMC erfolgte.

Verwendung in Verbindung mit Signal MF_Variante = DBMC.";
CM_ SG_ 1171 MF_Schluessel_scan "Anforderung eines Innenraumscans - Schlüsselsuche";
CM_ SG_ 1171 MF_Signalhorn "Versehrte, Fahrschule oder Taxi (bei Alarm)";
CM_ SG_ 1171 MF_Standlicht "statisch oder auch mit Blink_modi für Taxialarm";
CM_ SG_ 1171 MF_StartStopp_Info "Stopp-Freigabe und Start-Anforderung an den Start-Stopp-Koordinator";
CM_ SG_ 1171 MF_Summer "Warnsummer für Funkhauptschalter und Fahrschulpedal";
CM_ SG_ 1171 MF_TFL_Abschaltung "Abschaltung des Tagfahrlicht
0 = keine Auswirkung
1 = Tagfahrlicht deaktiviert";
CM_ SG_ 1171 MF_Tippwischen "Versehrte oder Fahrschule; Oder-Verknüpfung";
CM_ SG_ 1171 MF_Tuerentriegelung_hinten "Bei von innen verriegelten Fahrzeug Türen hinten entriegeln
0 = keine Auswirkung
1 = Türen hinten entriegeln
";
CM_ SG_ 1171 MF_Variante "Sonderfahrzeugvariante
0 = keine Sonderfunktion 
1 = Sondersignalfahrzeug
2 = Taxi 
3 = Fahrhilfe 
4 = Fahrschule+Extra 
5 = SSF
6 =  DBMC
7 = Arbeitsmaschine";
CM_ SG_ 1171 MF_Warnblinker "Versehrte";
CM_ SG_ 1171 MF_Wischerstufe_1 "Versehrte oder Fahrschule; Oder-Verknüpfung";
CM_ SG_ 1171 MF_Wischerstufe_2 "Versehrte oder Fahrschule; Oder-Verknüpfung";
CM_ SG_ 1171 MF_ZV_Lock "Verriegelungsanforderung durch MFG analog Meldung einer Locktasterbetätigung durch TSG.";
CM_ SG_ 1171 MFG_01_BZ "4bit Botschaftszähler, wird in jeder Sendebotschaft inkrementiert
";
CM_ SG_ 1171 MFG_01_CRC "Für MLB:
'Berechnung siehe Lastenheft 'Kommunikationsabsicherung für FlexRay und CAN''

Ab MQB und MLBevo:
'Berechnung siehe Lastenheft 'End-to-End Kommunikationsabsicherung''

Endwerte siehe Begleitdokument 'S-PDU Kennungsfolgen'";

CM_ SG_ 1165 MF_ADR_Anforderung "Anforderung der Arbeitsdrehzahlanhebung";
CM_ SG_ 1165 MF_ADR_Fahrpedalsperre "Aktivierung der Fahrpedalsperre";
CM_ SG_ 1165 MF_ADR_neg_Rampe "Gradient Abschaltung ADR";
CM_ SG_ 1165 MF_ADR_pos_Rampe "Gradient Drehzahl Einschaltung ADR";
CM_ SG_ 1165 MF_ADR_Solldrehzahl "Solldrehzahl der Arbeitsdrehzahlregelung";
CM_ SG_ 1165 MF_MFSS_aktiv "Status der Funktion Motor-Fern-Start-Stopp";
CM_ SG_ 1165 MF_MFSS_kodiert "MFG/ KFG zeigt Kodierstatus auf MFSS";
CM_ SG_ 1165 MF_VBEG_Anforderung "Anforderung Geschwindigkeitsbegrenzung";
CM_ SG_ 1165 MF_VBEG_Geschwindigkeit "Geschwindigkeitsbegrenzung KFG";
CM_ SG_ 1165 MFG_02_BZ "Botschaftszähler";
CM_ SG_ 1165 MFG_02_CRC "Für MLB:
'Berechnung siehe Lastenheft 'Kommunikationsabsicherung für FlexRay und CAN''

Ab MQB und MLBevo:
'Berechnung siehe Lastenheft 'End-to-End Kommunikationsabsicherung''

Endwerte siehe Begleitdokument 'S-PDU Kennungsfolgen'

Kennungsfolge:";
CM_ SG_ 1165 MFG_Heizstufe_LSH "Vom Klimabedienteil gesendete Heizstufe der Luftstandheizung";
CM_ SG_ 1165 MFG_Status_SREG "Über das Signal wird dem Motorsteuergerät der Freischaltstatus der Funktion Stand Regeneration (SREG) übermittelt.";
CM_ SG_ 1165 MFG_Taster_SREG "Über den Taster SREG wird die Funktion im MSG aktiviert. Ein fehlerhafter Schaltzustand wird berücksichtigt";
CM_ SG_ 1165 MFG_Taster_VREG "Über den Taster VREG wird die Funktion im MSG aktiviert. Ein fehlerhafter Schaltzustand wird berücksichtigt";
CM_ SG_ 1165 MFG_Zuheizer_Freigabe "Freigabe Zuheizer";

CM_ SG_ 817 MFL_ECU_Err "MFL-µC Fehler";
CM_ SG_ 817 MFL_Eventcode_1 "Siehe Q-LAH MFL-Protokoll";
CM_ SG_ 817 MFL_Eventcode_2 "Siehe Q-LAH MFL-Protokoll";
CM_ SG_ 817 MFL_Lokalaktiv "Zeigt an ob das SG nach Klemme15 AUS und nach entsprechender MAX Aktivzeit noch aktiv war";
CM_ SG_ 817 MFL_LR_HZG_Err "Lenkradheizung Fehler";
CM_ SG_ 817 MFL_LR_HZG_Status "Status Lenkradheizung";
CM_ SG_ 817 MFL_M_Taste "Taster für Umschaltung Automatik/manuelles Schalten (Tiptronic)";
CM_ SG_ 817 MFL_Marke "Marke für markenspezifische Variantennummer des MFL";
CM_ SG_ 817 MFL_Paddle_Verbau "Signalisiert den Zustand des Tipp-Paddle-Verbaus";
CM_ SG_ 817 MFL_Response_Err "siehe LIN2.0-Specification
(Darf nicht über ein Fehlergueltigkeitsbit abgesichtert werden!)";
CM_ SG_ 817 MFL_SatModul_links_Err "Schalter Tastermodul links Fehler";
CM_ SG_ 817 MFL_SatModul_rechts_Err "Schalter Tastermodul rechts Fehler";
CM_ SG_ 817 MFL_Signalhorn "Signalhorn nicht betaetigt/betaetigt";
CM_ SG_ 817 MFL_Signalhorn_Err "Signalhorn Fehler";
CM_ SG_ 817 MFL_Taste_links_Err "MFL_Tastenblock links Fehler";
CM_ SG_ 817 MFL_Taste_rechts_Err "MFL_Tastenblock rechts Fehler";
CM_ SG_ 817 MFL_Tastencode_1 "Beschreibt die Funktion einer fest zugeordneten Taste/Walze auf dem MFL. Bei Betätigung ändert sich der Wert von 0x0 auf den jeweiligen Tastencode.";
CM_ SG_ 817 MFL_Tastencode_2 "Beschreibt die Funktion einer fest zugeordneten Taste/Walze auf dem MFL. Ist MFL_Tastencode_1 wegen Betätigung einer Taste/Walze bereits mit einem Wert ungleich 0x0 belegt, so ändert sich bei Betätigung einer weiteren Taste/Walze der Wert dieses Signals v";
CM_ SG_ 817 MFL_Tip_Down "MFL-Tiptronic Tasten vom MFL für Getriebe
    0x0 = kein Tip_Down
    0x1 = Tip_Down";
CM_ SG_ 817 MFL_Tip_links_Err "Tiptronic links Fehler";
CM_ SG_ 817 MFL_Tip_rechts_Err "Tiptronic rechts Fehler";
CM_ SG_ 817 MFL_Tip_Up "MFL-Tiptronic Tasten vom MFL für Getriebe
    0x0 = kein Tip_Up
    0x1 = Tip_Up";
CM_ SG_ 817 MFL_Toggle "Watchdog Toggle-Bit";
CM_ SG_ 817 MFL_Touch_Event "Touch_Events für Informationen einer Funktionsauslösung auf dem MFL, welches dann für bspw. ein akustisches Signal zentral umgesetzt werden können.";
CM_ SG_ 817 MFL_Variante "Markenspezifische Variantennummer des MFL";

CM_ SG_ 329 MO_EP_01_BZ "4bit Botschaftszähler, wird mit jeder Sendebotschaft inkrementiert";
CM_ SG_ 329 MO_EP_01_CRC "Für MLB:
'Berechnung siehe Lastenheft 'Kommunikationsabsicherung für FlexRay und CAN''

Ab MQB und MLBevo:
'Berechnung siehe Lastenheft 'End-to-End Kommunikationsabsicherung''

Endwerte siehe Begleitdokument 'S-PDU Kennungsfolgen'";
CM_ SG_ 329 MO_EP_Ist_Haltemagnet "Status der Ansteuerung des Parksperren-Haltemagneten im Waehlhebel";
CM_ SG_ 329 MO_EP_Mute "Anforderung an den Parksperrenaktor, den Sendebetrieb einzustellen. Dieses Signal wird nur im MQB genutzt, weil der verwendete Parksperrenaktor kein UDS unterstützt.";
CM_ SG_ 329 MO_EP_Vorgabe_Position "Vorgabe der Position der Parksperre";

CM_ SG_ 15 MO_SOPC "Switch of Path Check der Motorsteuerung

Achtung, reines CAN-Signal!";

CM_ SG_ 1600 MO_Absperrventil_oeffnen "Signal an Klima-SG das Absperrrventil anzusteuern. Ab D4 auch 0x3 Ventil_schließen.

Im MQB wird hier der Soll-Status des Absperrventils ausgegeben.
Achtung: bei z. B. klemmendem Ventil entspricht das Signal nicht dem tatsächlichen Status!";
CM_ SG_ 1600 MO_aktives_Getriebeheizen "Information für Getriebe, ob ein Ventil für Getriebheizen angesteuert werden muss";
CM_ SG_ 1600 MO_Ansaugluft_Temp "In Fahrzeugen ohne Außentemperatur vom Kombi kann aus der Ansauglufttemperatur auf die Außentemperatur geschlossen werden. Beim SDI ist das mit einer gewissen Genauigkeit gegeben. Genutzt wird es vom ASG.";
CM_ SG_ 1600 MO_Getriebe_kuehlen "Anforderung Getriebekühlventilansteuerung";
CM_ SG_ 1600 MO_Heizungspumpenansteuerung "Anforderung Heizungspumpenansteuerung
MQB und Hybrid: Status der Heizungsunterstützungspumpe am MSG
";
CM_ SG_ 1600 MO_Hoeheninfo "Korrekturfaktor Höhe (1 entspricht 1013 mbar)";
CM_ SG_ 1600 MO_HYB_Fehler_HV_Netz "Im HV-Bordnetz ist fehlerbedingt kein generatorischer Betrieb möglich. Das 12V-Bordnetz wird über den DC/DC-Wandler allein aus der Traktionsbatterie gespeist. Um diesen Zustand möglichst lange aufrechterhalten zu können, sollten Komfort-Verbraucher abgesc";
CM_ SG_ 1600 MO_Kennfeldk "Die Kennfeldkühlung ist in diesem Fahrzeug verbaut und hat keinen Systemfehler";
CM_ SG_ 1600 MO_KL15_Abschaltempfehlung "Kessy Abschaltempfehlung nach Verlassen des Fahrzeugs";
CM_ SG_ 1600 MO_Kuehlmittel_Temp "Kuehlmitteltemperatur";
CM_ SG_ 1600 MO_Mom_Traegheit_02 "Massenträgheit (J) der Motors bzw. der Antriebsmaschinen in kgm².

Zur Berücksichtigung des E-Motor in Hybrid-Projekten:
in MLB-Projekten wird nur der J-Wert des Verbrennungsmotors und nicht der J-Wert des E-Motors berücksichtigt.
In MQB/MLBevo-Projek";
CM_ SG_ 1600 MO_Nachlaufzeit_Heizungspumpe "Nachlaufzeit für Heizungspumpe für Turboladerschutz";
CM_ SG_ 1600 MO_Oel_Temp "Realer Meßbereich ca. -40..150 Grad";
CM_ SG_ 1600 MO_QBit_Ansaugluft_Temp "
";
CM_ SG_ 1600 MO_QBit_Hoeheninfo "Qualifizierungsbit der Höheninfo. Gesetzt bei Ersatzwert, Init oder Fehler.";
CM_ SG_ 1600 MO_QBit_Kuehlmittel_Temp "
";
CM_ SG_ 1600 MO_SpannungsAnf "Forderung des Motor-SGs zur Spannungsanhebung";
CM_ SG_ 1600 MO_Versionsinfo_02 "Versioninformation vom Motor zur Steuerung bei inkompatiblen KMatrix-Änderung bzw. Einführung von neuen Funktionen, die in den Empfängern verriegelt werden müssen. Zu jedem Ereignis wird ein fixer Zählerstand zugeordnet, um dem Empfänger die funktionale Ä";

CM_ SG_ 1607 MO_CO2_Faktor "dynamischer Umrechnungsfaktor von l in CO2";
CM_ SG_ 1607 MO_E85_Sensor "Information über den E85 Gehalt (%-mass.) im Ottokraftstoff";
CM_ SG_ 1607 MO_Ethanol_Spuelhinweis "Hinweis das der Fahrer beim nächsten Tanken Ethanol armen Sprit tanken soll.";
CM_ SG_ 1607 MO_ITM_Kuehlmittel_Temp "Kuehlmitteltemperatur: Ersatzkühlmitteltemperatur für Motoren mit ITM (Thermomanagement)

ACHTUNG: Ab MQB wird in diesem Signal das Anzeigeplateau durch das MSG dargestellt!";
CM_ SG_ 1607 MO_Kraftstofffilter_Wasser "Für Schlechtkraftstoffländer wird das Wasserabscheidevolumen im Dieselkraftstofffilter mit einem  Wassersensor überwacht. Ist das Volumen erschöpft, erfolgt im Kombi eine entsprechende Anzeige.";
CM_ SG_ 1607 MO_MKB_01 "Motorkennbuchstabe 1";
CM_ SG_ 1607 MO_MKB_02 "Motorkennbuchstabe 2";
CM_ SG_ 1607 MO_MKB_03 "Motorkennbuchstabe 3";
CM_ SG_ 1607 MO_MKB_04 "Motorkennbuchstabe 4";
CM_ SG_ 1607 MO_MKB_MUX "Die vier Motorkennbuchstaben werden gemultiplext in MO_MKB übertragen. Das Signal MO_MKB_MUX stellt das Steuersignal für diesen Multiplexer dar.";
CM_ SG_ 1607 SCR_Akustik "Ansteuerung von Summer/Gong bei Aktivieren der SCR-Warnungen.
Bedienung des Signals nur bei Dieseln mit SCR-System. Andere senden Initwert.";
CM_ SG_ 1607 SCR_Anz_Motorstarts "Anzahl noch möglicher Motorstarts, wenn Reichweite = 0 ist
0..13 = Anzeige 'x mögliche Restarts'
14 = Eingeschränkte Fahrfunktion (z. Zt. Audi)
15 = keine Einschränkung (Anzeige Reichweite)
Bedienung des Signals nur bei Dieseln mit SCR-System.";
CM_ SG_ 1607 SCR_Inducement_Strategie "Art des Motor-Inducement-Konzepts. Abhängig von diesem Signal sind die Warntexte zwischen 'Kein Motorstart (in...km)' und 'eingeschränkte Fahrbarkeit (in ...km)' auszuwählen.";
CM_ SG_ 1607 SCR_Reichweite "Gesamtreichweite in km der aktuellen SCR-Tankfüllung, sofern die Reichweite kleiner 2400 km ist. Bei einer Reichweite größer 2400 km wird grundsätzlich der Initwert (32767) übertragen. Bedienung des Signals nur bei Dieseln mit SCR-System.";
CM_ SG_ 1607 SCR_Systemfehler "Ansteuerung Anzeige für SCR-Systemfehler";
CM_ SG_ 1607 SCR_Text "Warntext (z. B. in Kombination mit SCR Warnstufe und SCR-Systemfehler).
Bedienung des Signals nur bei Dieseln mit SCR-System. Andere senden Initwert.";
CM_ SG_ 1607 SCR_verbaut "Die SCR-Signale deren Initwert ungleich 0 sind, werden nur dann ausgewertet, wenn SCR_verbaut == 1 den Verbau des SCR Systems zeigt.";
CM_ SG_ 1607 SCR_Warnstufe_1 "Ansteuerung der SCR Füllstandswarnlampe (Stufe 1) (gelbe Lampe) SCR_Warnstufe_1 (Prio 2).
Bedienung des Signals nur bei Dieseln mit SCR-System. Andere senden Initwert.";
CM_ SG_ 1607 SCR_Warnstufe_2 "Ansteuerung der SCR Füllstandswarnlampe (Stufe 2) (Blinkbit für gelbe Lampe oder rote Lampe) SCR_Warnstufe_2 (Prio 1).
Bedienung des Signals nur bei Dieseln mit SCR-System. Andere senden Initwert.";

CM_ SG_ 958 MO_Aussp_Anlass "Das Signal zeigt an, ob die Wiederholstartsperre aktiv ist. D. h. eine Ansteuerung des Anlassers wird auch bei erfüllten Startvoraussetzungen (HS: Interlock betätigt bzw. AT: P/N eingelegt und Bremse betätigt) nicht erfolgen.";
CM_ SG_ 958 MO_BKV_Unterdruckwarnung "Über die Unterdruckwarnung signalisiert das MSG dem ESP, dass kein ausreichender Unterdruck für den BKV zur Verfügung gestellt werden kann.";
CM_ SG_ 958 MO_BLS "Ungefiltertes Rohsignal des Bremslichtschalters, nur wenn HW-Eingang bestückt und ausgewertet wird. Bei Motoren ohne genutzten HW-Eingang wird kein Ersatzwert (bspw. SW-Signal über CAN) ausgegeben!
Bei AUDI muss das Signal wg. Bremslichtfunktion immer be";
CM_ SG_ 958 MO_BMS_NV_Anf_stuetzen "Garantierte Unterstützung des Zusatzspeichers ist erforderlich. Zusatzspeicher muss an das Versorgungsnezt angebunden werden. ";
CM_ SG_ 958 MO_EKlKomLeiRed "Anforderung an die Klimasteuerung, die Leistungsaufnahme des E-Kompressors bei schlechtem SOC und in bestimmten Fahrsituationen zu begrenzen. (Das bereits bestehende Signal 'Klimakompressor aus' als stets umzusetzende Anforderung bleibt unverändert besteh";
CM_ SG_ 958 MO_Ext_E_Fahrt_aktiv "Funktionsrückmeldung zum erw. E-Fahr-Betrieb über Lampe/LED im E-Mode-Taster";
CM_ SG_ 958 MO_Fahrer_bremst "Redundante Bremsinformation vom Motor.

MLB:
AUDI D4: Zykluszeit: 10ms (siehe Zykluszeit schnell/Cycletime Fast)
Im AUDI B8 wird in diesem Bit der Wert der ESP-CAN-Information 'ESP_Fahrer_bremst' ausgegeben.

Achtung:
Reduktion der Zykluszeit Motor";
CM_ SG_ 958 MO_FMAus_aktiv "Das Signal gibt Rückmeldung ob Freilauf Motor aus aktiv ist. Beleibt auch 0km/h (unterhalb der StartStopp Schwelle) weiterhin aktiv.";
CM_ SG_ 958 MO_FMAus_Startvariante "Startvariante beim Motorstart aus der Freilauf-Motor-AUS Phase";
CM_ SG_ 958 MO_Freig_Anlass "Bit wird gesetzt, wenn der Motor beim Automatikstart gestartet werden darf (Motorstillstand, Emissionsmaßnahmen sind erfüllt).";
CM_ SG_ 958 MO_Freig_Reku "Empfehlung des Motor-SG's zur Spannungsabsenkung/-anhebung für den Rekuperationsbetrieb";
CM_ SG_ 958 MO_Freigabe_Segeln "Freigabebit des Segelbetriebs im Getriebe. Bedingt durch bestimmte Diagnosen und Adaptionen des MSGs, die nur im Schub möglich sind, darf nicht jede Schubphase für einen Segelbetrieb genutzt werden. Eine Freigabe bleibt auch außerhalb einer Schubphase bes";
CM_ SG_ 958 MO_Gangposition "MLB:
Stellung des Wählhebels in der Schaltgasse des Handschaltgetriebes.
MLBevo: 
Ausweitung der Bedienung auch auf Automatikgetriebe;
Routing des Signals GE_Fahrstufe: 
1. Position_R (dez. 6) auf MO_Gangposition: Gang_R (dez. 13) wegen Entfall Signa";
CM_ SG_ 958 MO_Handshake_STH "Es gilt: Signalspec MO_Handshake v1.0

Handshake zwischen MSG und STH. Wenn das MSG die EKP aufgrund einer STH-Anforderung ansteuert und kein Fehlereintrag bzgl. EKP/KPE/NDR vorliegt, wird das Bit gesetzt.";
CM_ SG_ 958 MO_HYB_Fahrbereitschaft "Signal steuert u.a. in der Lenkhilfe zusammen mit weiteren Informationen den Modewechsel in den 'Drivemode'
Grüne Anzeige im Kombiinstrument zur Signalisierung der Bereitschaft des Hybridsystems.";
CM_ SG_ 958 MO_HYB_VM_aktiv "0 = VMotor wird nicht aktiv gehalten (nVM < n_min und keine LL-Regelung aktiv)
1 = VMotor aktiv (ab der ersten Einspritzung; gilt auch für Schubbetrieb, wenn VMotor spätestens durch LLRegelung befeuert würde)
Verwendet zur Bestimmung des Ist-Zustandes";
CM_ SG_ 958 MO_Interlock "Das Motorsteuergerät gibt die Information aus, ab wann der Kupplungsschalter durch das Motorsteuergerät als getreten gesehen wird.
Bei Systemen für Start Stopp muss das Interlocksignal für einen Start durch das MSG generiert werden, sobald der Schalthebe";
CM_ SG_ 958 MO_Kickdown "Es gilt: Signalspec MO_Kickdown v1.0";
CM_ SG_ 958 MO_Kl_50 "Klemme 50: Startausführung durch Ritzelstarter

MLB: nicht von allen Motoren gesendet
MQB/MLBevo: gesendet von allen Motoren";
CM_ SG_ 958 MO_Kl_75 "Klemme X
";
CM_ SG_ 958 MO_Klima_Eingr "Eingriffe des Motor bei der Klima";
CM_ SG_ 958 MO_Konsistenz_Bremsped "MLB:

AUDI D4: Zykluszeit: 10ms (siehe Zykluszeit schnell/Cycletime Fast)
Siehe 'Funktionsspezifikation Bremslichtinfo B8'

Achtung:
Reduktion der Zykluszeit Motor_03 auf 10ms geplant.
Projektabhängig soll künftig mit 10ms gesendet werden.
Empfäng";
CM_ SG_ 958 MO_Kuppl_schalter "MLB:
Das Motorsteuergerät gibt die Information aus, ab wann der Kupplungsschalter durch das Motorsteuergerät als getreten gesehen wird
0x0: Schalter sagt betätigt (Ausgekuppelt)
0x1: Schalter sagt nicht betätigt (Eingekuppelt)

MQB:
Nur Handschalter";
CM_ SG_ 958 MO_Motor_laeuft "Das Motorsteuergerät gibt die Information aus, ab wann der Motor verbrennungsbedingt autark läuft und durch zuschaltbare Nebenaggregate mechanisch belastbar ist (z.B. durch Generator, Klimakompressor, etc.).

Die 'Motor läuft' Information wird ausgegebe";
CM_ SG_ 958 MO_PTC_Status "Status-Rückmeldung vom MSG zum aktuellen PTC-Status (stufiges PTC, Relais am MSG). Bei Ansteuerung eines stufigen PTC durch ein anderes SG beschreibt das Signal die vom MSG freigegebene PTC-Stufe.";
CM_ SG_ 958 MO_QBit_Fahrer_bremst "MLB:
AUDI D4: Zykluszeit: 10ms (siehe Zykluszeit schnell/Cycletime Fast)

Achtung:
Reduktion der Zykluszeit Motor_03 auf 10ms geplant.
Projektabhängig soll künftig mit 10ms gesendet werden.
Empfänger die in weiteren Konzern-Projekten eingesetzt werd";
CM_ SG_ 958 MO_QBit_Gangposition "Qualitätsbit zum Signal MO_Gangposition";
CM_ SG_ 958 MO_QBit_KL_75 "Q - Bit für das KL 75 Signal zur Vermeidung der fehlerhaften Erkennung von Motorstarts. 
Wird auf 1 gesetzt, solange das Motorsteuergerät KL15 = AUS erkannt hat.";
CM_ SG_ 958 MO_Remotestart_Betrieb "Das MSG ist für den Remotestart-Betrieb bereit. Nach Empfang der Motorstartanforderung für RSt-Betrieb durch BCM wird der Fahrzeugmotor gestartet und solange der Motor läuft, bleibt dieses Bit aktiv. Dieses Signal ist nur zur Verwendung durch das BCM zur ";
CM_ SG_ 958 MO_Remotestart_moeglich "Wenn Bit gesetzt, würde das MSG bei entsprechender Anforderung durch das BCM den Remotestartbetrieb einleiten, d.h. das MSG ist remotestartfähig und es liegen aktuell keine relevanten Fehler oder andere Abbruchgründe vor.";
CM_ SG_ 958 MO_Signalquelle_Gangposition "Signalquelle des Signals MO_Gangposition
0: Signalquelle Gangpositionssensor
1: Signalquelle Modellwert (v/n)";
CM_ SG_ 958 MO_StartStopp_Fahrerwunsch "Fahreraktivität Start/Stop";
CM_ SG_ 958 MO_StartStopp_Motorstopp "Motor-Stopp durch Start/Stopp-Koordinator
HYBRID:
Wenn MO_Hybridfahrzeug = 1 gilt:
Verbrennungsmotor durch Hybrid-Koordinator im MSG ausgeschaltet. 
Die definierten Start/Stopp-Signale beziehen sich nur auf den Verbrennungsmotor!";
CM_ SG_ 958 MO_StartStopp_Status "Aktivitätsstatus Start/Stopp-Koordinator
HYBRID:
Wenn MO_Hybridfahrzeug = 1 gilt:
Signal bezieht sich nur auf den Verbrennungsmotor, nicht auf den Hybridantrieb
";
CM_ SG_ 958 MO_StartStopp_Wiederstart "Motorwiederstart durch Start/Stopp-Koordinator
HYBRID:
Wenn MO_Hybridfahrzeug =1 gilt:
Warnung vor Spannungseinbruch beim Zustart des Verbrennungsmotors. 
-nicht relevant, da derzeit kein Start über 12V-Starter geplant-
Dieses Signal wird nur vom Hyb";
CM_ SG_ 958 MO_StartVorauss_erfuellt "Dient der Fallunterscheidung bei ZAT-Betätigung im Zustand 'KL15 ein' (bei nicht gesetztem Signal folgt KL15 aus, bei gesetztem Signal folgt setzen KL50-Anf.)

0: Signal nicht bedient 
1: Voraussetzungen zur Antriebsstrangaktivierung / Startvoraussetzu";
CM_ SG_ 958 MO_Timeout_ESP "500 ms Timeout auf Bremsen-Botschaft ist >= 1 mal aufgelaufen, Löschen des Bits nach Neustart (KL15).

MLB:
AUDI D4: Zykluszeit: 10ms (siehe Zykluszeit schnell/Cycletime Fast)

Achtung:
Reduktion der Zykluszeit Motor_03 auf 10ms geplant.
Projektabh";
CM_ SG_ 958 MO_Zylinderabschaltung "Status Zylinderabschaltung Motor";
CM_ SG_ 958 Motor_14_CRC "Ab MQB und MLBevo:
'Berechnung siehe Lastenheft 'End-to-End Kommunikationsabsicherung'

Endwerte siehe Begleitdokument 'S-PDU Kennungsfolgen'";

CM_ SG_ 1631 MO_Anzeige_Kaltleuchte "Fahrleistungseinschänkungen aus dem Motor-Abgasmanagement zur Anzeige als Lampe ohne Hinweistext im Kombiinstrument";
CM_ SG_ 1631 MO_DPF_reg "Regeneration Diesel-Partikel-Filter";
CM_ SG_ 1631 MO_Energieinhalt_BMS "Restenergieinhalt der Traktionsbatterie, beeinflusst durch Fahrstrategie und weiteren Faktoren der Antriebssteuerung.";
CM_ SG_ 1631 MO_Heizstrom_EKAT "Aktuelle Gesamtstromaufnahme des E-Katalysators";
CM_ SG_ 1631 MO_Heizstrom_SCR "Aktuelle Gesamtstromaufnahme der Tank-, Fördermodul- und Leitungsheizung des SCR-Systems";
CM_ SG_ 1631 MO_P_Generator_ungefiltert_Anf "Bei Empfang der Anforderung soll der Sender BEM_P_Generator ungefiltert befüllen.";
CM_ SG_ 1631 MO_SpannungsAnf_02 "Forderung des Motor-SG's zur Spannungsanhebung";
CM_ SG_ 1631 TSK_Fahrzeugmasse_02 "Neue Definition ab D4
Fahrzeugmasse in kg. Das Signal dient der Anpassung der Sollbeschleunigung vom ACC


";
CM_ SG_ 1631 TSK_Grundmasse "Fahrzeuggrundmasse in kg. Das Signal dient der Anpassung der Sollbeschleunigung vom ACC

Hinweis: Ehemaliger Fehlerwert 0x7F wird senderseitig nicht unterstützt. Diesen Wert aus Kompatibilitätsgründen nicht neu belegen!";
CM_ SG_ 1631 TSK_Steigung_02 "Steigung in % Berg. Das Signal dient der Anpassung der Sollbeschleunigung vom ACC

Positive Werte > bergauf; 
Negative Werte < bergab

Fehler: Die Steigung aufgrund eines Fehlers (mit KD-Fehlereintrag) nicht mehr berechnet werden";

CM_ SG_ 1648 MO1_Freigabe_Info_WFS "WFS-Freigabeinformation";
CM_ SG_ 1648 MO1_Freigabe_Verfallsinfo_WFS "WFS-Freigabeverfallsinformation";
CM_ SG_ 1648 MO1_Sperr_Info_WFS "WFS-Sperrinformation";
CM_ SG_ 1648 MO_Abstellzeit "Abstelldauer nach letztem KL15 aus

Hinweis: 
Ehemaliger Fehlerwert 0xFF wird senderseitig nicht unterstützt. 
Diesen Wert aus Kompatibilitätsgründen nicht neu belegen!";
CM_ SG_ 1648 MO_Abstellzeit_Status "Statusinformation zur Abstellzeit
0: Die dem Status zugeordnete Variable konnte noch nicht berechnet werden. 
1: Die dem Status zugehörige Variable wurde korrekt berechnet. 
2: Der Wert der zugehörigen Variablen ist nur ein Minimalwert. 
3: Der Wert d";
CM_ SG_ 1648 MO_ANC_Kennfeld_Anf "Anforderung ANC Kennfeldumschaltung";
CM_ SG_ 1648 MO_Anzahl_Abgesch_Zyl "Gibt die Anzahl der abgeschalteten Zylinder an. In Übergangszuständen wird der Zielbetriebszustand angezeigt.";
CM_ SG_ 1648 MO_Bremslicht_Reku "Bremslicht (ggf. bei Rekuperation durch E-Motor) wird angesteuert";
CM_ SG_ 1648 MO_Drehzahl_Warnung "Warnhinweis zum Kombi im Fall einer fehlerbehafteten Drehzahlbegrenzung";
CM_ SG_ 1648 MO_EPCL "Die Anforderung der EPC-Lampe vom MSG ans Kombi soll durch das Bus-Signal MO_EPCL gemäß folgender Logik erfolgen:
MO_EPCL = 0 dez -> EPC Lampe aus, kein Text
MO_EPCL = 1 dez -> gelbe EPC-Symbolik, Text „Antrieb: Störung! Bitte Service aufsuchen“
MO_EPC";
CM_ SG_ 1648 MO_Ethanol_BS_Texte "Ethanol Brennstoff-Texte im Kombi

0 = kein Text
1 = E85 Warm_Up
2 = FlexFuel Warnung 3.Stufe (Too cold for ethanol)
3 = Warmfahrempfehlung MQB / FlexFuel Warnung 1.Stufe (Refuel with gasoline)
4 = FlexFuel Warnung 2. Stufe (Refuel with gasoline)
5";
CM_ SG_ 1648 MO_Fahrzeugtyp "Unterscheidet die Fahrzeugtypen bzgl. der Antriebsart";
CM_ SG_ 1648 MO_Fehler_Zylabsch "Fehlerstatus der Funktion Zylinderabschaltung ";
CM_ SG_ 1648 MO_Hybrid_StartStopp_LED "Ansteuerung der Funktions-LED der Hybrid Taste bzw. Start/Stop Deaktivierungstaste.
Der Start/Stopp-Master (derzeit im MSG) (oder ein künftiger Hybrid-Master) soll die Ansteuerung senden.";
CM_ SG_ 1648 MO_max_Ladedruck "maximal möglicher Ladedruck (zur Anpassung des Anzeigebereichs bei absoluter Ladedruckanzeige)";
CM_ SG_ 1648 MO_NMAX_Schaltanzeige "Maximaldrehzahl für Schaltanzeige";
CM_ SG_ 1648 MO_obere_Drehzahlgrenze "obere Drehzahlgrenze des Motors";
CM_ SG_ 1648 MO_StartStopp_PopUp "Das Signal zeigt an, ob der StSt-Status mittels Deaktivierungstaster geändert wurde. Ein Wechsel auf die Werte 01 oder 10 löst im Kombi ein entsprechendes PopUp aus. Bei einem Statuswechsel durch andere Signalquellen (z.B. Charisma, fehlerbedingte Abschal";
CM_ SG_ 1648 MO_Zylabsch_Texte "Zylinderabschaltung mode in Kombi, fuer Zylinderabschaltung";
CM_ SG_ 1648 MO_Zylabsch_Texte_02 "ZAS-Anzeige für den Fahrer im Kombi
0: kein ZAS (generell keinerlei ZAS-Anzeigen)  (Init für nicht ZAS-Motor)
1: ZAS im Vollmotorbetrieb  (Init für ZAS-Motor)
2: ZAS im Abschaltbetrieb: 1 Zyl aktiv
3: ZAS im Abschaltbetrieb: 2 Zyl aktiv
4: ZAS im Abs";

CM_ SG_ 1654 MO_StaGluehk "Einschaltzustand der Gluehkerzenheizung in Prozent";
CM_ SG_ 1654 MO_Stoppverbot_Anz_01 "Dieses Signal gibt die detaillierte Begründung für ein Stoppverbot vom Motor an.";
CM_ SG_ 1654 MO_Stoppverbot_Anz_02 "Dieses Signal gibt die detaillierte Begründung für ein Stoppverbot vom Motor an.";
CM_ SG_ 1654 MO_Stoppverbot_Anz_03 "Dieses Signal gibt die detaillierte Begründung für ein Stoppverbot vom Motor an.";
CM_ SG_ 1654 MO_Stoppverbot_Anz_04 "Dieses Signal gibt die detaillierte Begründung für ein Stoppverbot vom Motor an.";
CM_ SG_ 1654 MO_Stoppverbot_Anz_05 "Dieses Signal gibt die detaillierte Begründung für ein Stoppverbot vom Motor an.";
CM_ SG_ 1654 MO_Stoppverbot_Anz_06 "Dieses Signal gibt die detaillierte Begründung für ein Stoppverbot vom Motor an.";
CM_ SG_ 1654 MO_Stoppverbot_Anz_07 "Dieses Signal gibt die detaillierte Begründung für ein Stoppverbot vom Motor an.";
CM_ SG_ 1654 MO_Stoppverbot_Anz_08 "Dieses Signal gibt die detaillierte Begründung für ein Stoppverbot vom Motor an.";
CM_ SG_ 1654 MO_Stoppverbot_Anz_09 "Dieses Signal gibt die detaillierte Begründung für ein Stoppverbot vom Motor an.";
CM_ SG_ 1654 MO_Stoppverbot_Anz_10 "Dieses Signal gibt die detaillierte Begründung für ein Stoppverbot vom Motor an.";
CM_ SG_ 1654 MO_Stoppverbot_Anz_11 "Dieses Signal gibt die detaillierte Begründung für ein Stoppverbot vom Motor an.";
CM_ SG_ 1654 MO_Stoppverbot_Anz_Std "Dieses Signal gibt die detaillierte Begründung für ein Stoppverbot vom Motor an.";
CM_ SG_ 1654 MO_Wiederstart_Anz_01 "Dieses Signal gibt die detaillierte Begründung für eine Wiederstartanforderung vom Motor an.";
CM_ SG_ 1654 MO_Wiederstart_Anz_02 "Dieses Signal gibt die detaillierte Begründung für eine Wiederstartanforderung vom Motor an.";
CM_ SG_ 1654 MO_Wiederstart_Anz_03 "Dieses Signal gibt die detaillierte Begründung für eine Wiederstartanforderung vom Motor an.";
CM_ SG_ 1654 MO_Wiederstart_Anz_Std "Dieses Signal gibt die detaillierte Begründung für eine Wiederstartanforderung vom Motor an.";
CM_ SG_ 1654 StSt_Koord_Status_Bremspedalkzpt "Dieses Signal gibt die Information, ob das Bremspedalkonzept (Startanforderung Automat) aktiv ist oder nicht.";
CM_ SG_ 1654 StSt_Koord_Stoppverbot_Anz_01 "Dieses Signal gibt die detaillierte Begründung für ein Stoppverbot vom StartStop Koordinator an.";
CM_ SG_ 1654 StSt_Koord_Stoppverbot_Anz_02 "Dieses Signal gibt die detaillierte Begründung für ein Stoppverbot vom StartStop Koordinator an.";
CM_ SG_ 1654 StSt_Koord_Stoppverbot_Anz_03 "Dieses Signal gibt die detaillierte Begründung für ein Stoppverbot vom StartStop Koordinator an.";
CM_ SG_ 1654 StSt_Koord_Stoppverbot_Anz_04 "Dieses Signal gibt die detaillierte Begründung für ein Stoppverbot vom StartStop Koordinator an.";
CM_ SG_ 1654 StSt_Koord_Stoppverbot_Anz_05 "Dieses Signal gibt die detaillierte Begründung für ein Stoppverbot vom StartStop Koordinator an.";
CM_ SG_ 1654 StSt_Koord_Stoppverbot_Anz_06 "Dieses Signal gibt die detaillierte Begründung für ein Stoppverbot vom StartStop Koordinator an.";
CM_ SG_ 1654 StSt_Koord_Stoppverbot_Anz_07 "Dieses Signal gibt die detaillierte Begründung für ein Stoppverbot vom StartStop Koordinator an.";
CM_ SG_ 1654 StSt_Koord_Stoppverbot_Anz_08 "Dieses Signal gibt die detaillierte Begründung für ein Stoppverbot vom StartStop Koordinator an.";
CM_ SG_ 1654 StSt_Koord_Stoppverbot_Anz_09 "Dieses Signal gibt die detaillierte Begründung für ein Stoppverbot vom StartStop Koordinator an.";
CM_ SG_ 1654 StSt_Koord_Stoppverbot_Anz_10 "Dieses Signal gibt die detaillierte Begründung für ein Stoppverbot vom StartStop Koordinator an.";
CM_ SG_ 1654 StSt_Koord_Stoppverbot_Anz_11 "Dieses Signal gibt die detaillierte Begründung für ein Stoppverbot vom StartStop Koordinator an.";
CM_ SG_ 1654 StSt_Koord_Stoppverbot_Anz_12 "Dieses Signal gibt die detaillierte Begründung für ein Stoppverbot vom StartStop Koordinator an.";
CM_ SG_ 1654 StSt_Koord_Stoppverbot_Anz_13 "Dieses Signal gibt die detaillierte Begründung für ein Stoppverbot vom StartStop Koordinator an.";
CM_ SG_ 1654 StSt_Koord_Stoppverbot_Anz_14 "Dieses Signal gibt die detaillierte Begründung für ein Stoppverbot vom StartStop Koordinator an.";
CM_ SG_ 1654 StSt_Koord_Stoppverbot_Anz_15 "Dieses Signal gibt die detaillierte Begründung für ein Stoppverbot vom StartStop Koordinator an.";
CM_ SG_ 1654 StSt_Koord_Stoppverbot_Anz_16 "Dieses Signal gibt die detaillierte Begründung für ein Stoppverbot vom StartStop Koordinator an.";
CM_ SG_ 1654 StSt_Koord_Stoppverbot_Anz_17 "Dieses Signal beinhaltet die Information, ob für einen Motorstopp eine weitere Fahrerbedienhandlung (z. B. Kupplung lösen) nötig ist.

0 = Motorstopp nicht durch Fahrerhandlung verhindert
1 = fehlende Fahrerhandlung verhindert Motorstopp";
CM_ SG_ 1654 StSt_Koord_Stoppverbot_Anz_18 "Dieses Signal beinhaltet die Information, dass ein Motorlauf wg. PSD notwendig ist.

0 = Motorstopp nicht durch PSD verhindert
1 = PSD verhindert Motorstopp";
CM_ SG_ 1654 StSt_Koord_Stoppverbot_Anz_19 "Dieses Signal beinhaltet die Information, dass ein Motorlauf wg. Kurzstopperkennung notwendig ist.

0 = Motorstopp nicht durch Kurzstopperkennung verhindert
1 = Kurzstopperkennung verhindert Motorstopp";
CM_ SG_ 1654 StSt_Koord_Stoppverbot_Anz_20 "Dieses Signal beinhaltet die Information, dass ein Motorlauf wg. Ampelinfo-Online notwendig ist.

0 = Motorstopp nicht durch Ampelinfo-Online verhindert
1 = Ampelinfo-Online verhindert Motorstopp";
CM_ SG_ 1654 StSt_Koord_Stoppverbot_Anz_21 "Dieses Signal beinhaltet die Information, dass ein Motorlauf wg. RaceMode, S oder Tipp notwendig ist

0 = Motorstopp nicht durch RaceMode, S oder Tipp verhindert
1 = RaceMode, S oder Tipp verhindert Motorstopp";
CM_ SG_ 1654 StSt_Koord_Stoppverbot_Anz_Std "Dieses Signal gibt die detaillierte Begründung für ein Stoppverbot vom StartStop Koordinator an.";
CM_ SG_ 1654 StSt_Koord_Wiederstart_Anz_01 "Dieses Signal gibt die detaillierte Begründung für eine Wiederstartanforderung vom StartStop Koordinator an.";
CM_ SG_ 1654 StSt_Koord_Wiederstart_Anz_02 "Dieses Signal gibt die detaillierte Begründung für eine Wiederstartanforderung vom StartStop Koordinator an.";
CM_ SG_ 1654 StSt_Koord_Wiederstart_Anz_03 "Dieses Signal gibt die detaillierte Begründung für eine Wiederstartanforderung vom StartStop Koordinator an.";
CM_ SG_ 1654 StSt_Koord_Wiederstart_Anz_04 "Dieses Signal gibt die detaillierte Begründung für eine Wiederstartanforderung vom StartStop Koordinator an.";
CM_ SG_ 1654 StSt_Koord_Wiederstart_Anz_05 "Dieses Signal gibt die detaillierte Begründung für eine Wiederstartanforderung vom StartStop Koordinator an.";
CM_ SG_ 1654 StSt_Koord_Wiederstart_Anz_06 "Dieses Signal gibt die detaillierte Begründung für eine Wiederstartanforderung vom StartStop Koordinator an.";
CM_ SG_ 1654 StSt_Koord_Wiederstart_Anz_07 "Dieses Signal gibt die detaillierte Begründung für eine Wiederstartanforderung vom StartStop Koordinator an.";
CM_ SG_ 1654 StSt_Koord_Wiederstart_Anz_08 "Dieses Signal gibt die detaillierte Begründung für eine Wiederstartanforderung vom StartStop Koordinator an.";
CM_ SG_ 1654 StSt_Koord_Wiederstart_Anz_09 "Dieses Signal gibt die detaillierte Begründung für eine Wiederstartanforderung vom StartStop Koordinator an.";
CM_ SG_ 1654 StSt_Koord_Wiederstart_Anz_10 "Dieses Signal gibt die detaillierte Begründung für eine Wiederstartanforderung vom StartStop Koordinator an.";
CM_ SG_ 1654 StSt_Koord_Wiederstart_Anz_11 "Dieses Signal gibt die detaillierte Begründung für eine Wiederstartanforderung vom StartStop Koordinator an.";
CM_ SG_ 1654 StSt_Koord_Wiederstart_Anz_Std "Dieses Signal gibt die detaillierte Begründung für eine Wiederstartanforderung vom StartStop Koordinator an.";

CM_ SG_ 1391 MO_Anzeige_Aufheizfortschritt "Anzeigesignal des Aufheizfortschritts des Abgastrakts im Rahmen der Kaltabfahrbegrenzung";
CM_ SG_ 1391 MO_Anzeige_Drehmoment_Max "Signal gibt das max. verfügbare Drehmoment wieder. Bedient die Drehmomentanzeige im Kombiinstrument. ";
CM_ SG_ 1391 MO_Anzeige_Leistung_Max "Signal gibt die max. verfügbare Motorleistung wieder. Bedient die Leistungsanzeige im Kombiinstrument. ";
CM_ SG_ 1391 MO_HYB_Drehzahl_VM "für OBD freeze frame";
CM_ SG_ 1391 MO_IstLeistung_EKAT "Gesamt IST-Leistung der elektrischen Heizscheibe(n)";

CM_ SG_ 967 MO_E_Mode "Anforderung der E-Mode Statusanzeige";
CM_ SG_ 967 MO_E_Texte "Anforderung von Hinweistexten des E-Systems separat für HEV/BEV bzw. erweiterbar für PHEV";
CM_ SG_ 967 MO_E_Warnungen "Anforderung von Warnanzeigen des E-Systems separat für HEV/BEV bzw. erweiterbar für PHEV";
CM_ SG_ 967 MO_EFLEX_Lampe "Um ein Starten mit E100 zu ermöglichen, wird Kraftstoff ggf. vorgeheizt. Das Signal dient der Anzeige des Heizungsstatus.

Heizung aus -> Lampe aus
Heizung ein -> Lampe ein
Heizung ein und Startversuch -> Lampe blinkend
Heizung nicht möglich -> Lampe";
CM_ SG_ 967 MO_Heissleuchte "Ansteuerung der Kühlwassertemperatur-Heißleuchte (Sensor nur noch am Motorsteuergerät): Temperaturschaltschwellen mit Hysterese (bei VW D1/Colorado Kombi derzeit noch nicht genutzt).";
CM_ SG_ 967 MO_ITM_Warnung_Pumpe "Textanzeige: 'Motor sofort abstellen, geschaltete Wasserpumpe defekt / klemmt'";
CM_ SG_ 967 MO_KJS_nicht_bereit "Dieses Signal zeigen einen Fehler der Kühlerjalousie mit unbekannter Stellung der Lamellen. ";
CM_ SG_ 967 MO_Kuehlerluefter_1 "Ansteuertastverhaeltnis (PWM) der Kuehlerluefterendstufe 1";
CM_ SG_ 967 MO_Kuehlerluefter_2 "Ansteuertastverhaeltnis (PWM) der Kuehlerluefterendstufe 2";
CM_ SG_ 967 MO_Kuehlerluefter_MUX "Multiplexer für das Signal 'MO_Kuehlerlüfter'";
CM_ SG_ 967 MO_OBD2_Lampe "OBD bzw. MIL-Lampe wird vom Motorsteuergerät angesteuert, die Information im Signal GE_OBD_Status wird vom Motorsteuergerät an das Kombi weitergereicht";
CM_ SG_ 967 MO_Oelwarnung_max "Ölstandswarnung mit der Aufforderung zum Ölwechsel.
Hintergrund: Bei Kraftstoffeintrag (B20) ins Öl verbleibt der RME-Anteil irreversibel im Öl.";
CM_ SG_ 967 MO_Partikel_Lampe "Partikelfilter-Lampe wird eingeschaltet";
CM_ SG_ 967 MO_RedFahrleistung_Lampe "Ansteuerung der Turtle-Mode Lampe für E-Traktion Fahrzeuge";
CM_ SG_ 967 MO_Systemlampe "EGas Systemlampe (EPC) oder Vorglühlampe im Kombi, Kombi steuert immer gleiche
LED an, nur über Ziffernblatt wird die EPC von der Vorglühlampe differenziert";
CM_ SG_ 967 MO_Tankdeckel_Lampe "Ansteuerung Tankdeckel-Warnlampe Kombiinstrument (nur Ottomotoren) z.Zt. Vorhalt VW";
CM_ SG_ 967 MO_Text_Motorstart "Anzeigetexte für Start/Stopp und Motor-Start
0xB Fehler_Kupplungsschalter nur für PAG-MLB";
CM_ SG_ 967 MO_Text_Partikelfil_Reg "Über dieses Bit im Kombi wird ein Klartextanzeige erzeugt werden: 'Partikelfilter benötigt Regeneration'.
";
CM_ SG_ 967 MO_Text_Tankdeckelwarn "Textbit der Tankdeckelwarnung, z.Zt. Vorhalt VW";
CM_ SG_ 967 MO_Vorglueh_Lampe "Vorglühlampe im Kombi, Kombi steuert immer gleiche LED an. 
Mit Einführung des Einheits-Kombis sind getrennte Signalwege für Vorglühlampe und EPCL notwendig.";
CM_ SG_ 967 MO_Zustand_HWP "Rückmeldung des  Ansteuerzustand der Hauptwasserpumpe an das Klima-SG .
Der Zustand 'HWP fördert' wird übermittelt, wenn die Schaufeln der Hauptwasserpumpe frei drehen können und die Motordrehzahl und damit die Wasserpumpendrehzahl größer als Null ist. B";
CM_ SG_ 967 OLEV_Oelstand_nicht_vorhanden "Kein aktueller Ölstand vorhanden";
CM_ SG_ 967 OLEV_Systemstoerung "Systemstörung im Ölsystem";
CM_ SG_ 967 WIV_Anzeige_aktiv "Peilstabsanzeigefunktion aktiv";
CM_ SG_ 967 WIV_laufender_Motor "Messung bei laufendem Motor nicht möglich";
CM_ SG_ 967 WIV_nachfuellanzeige_ein "Steuert das Aufblenden der Nachfüllanzeige im Kombi, nach Klemme 15 ein und geöffneter Motorhaube";
CM_ SG_ 967 WIV_nicht_betriebswarm "Motor nicht betriebswarm, Messung ungenau";
CM_ SG_ 967 WIV_Oeldr_Warn_Motor "Löst im Kombiinstrument die rote Prio1-Öldruckwarnung (inkl. 3xBeep) aus.
nur MLB: die Warnauslösung erfolgt nur bei gleichzeitig gesetztem 'WIV_Enable_Oeldr_Motor'";
CM_ SG_ 967 WIV_Oeldyn_avl "Ölstand aus dynamischer Messung vorhanden";
CM_ SG_ 967 WIV_Oelmenge "Ölmenge zwischen Min und Max";
CM_ SG_ 967 WIV_Oelmin_Warn "Signal gibt an wenn der Ölstand die Min-Schwelle unterschritten hat";
CM_ SG_ 967 WIV_Oelstand "8 Segmente zur Balkenanzeige des Ölstands";
CM_ SG_ 967 WIV_Oelstand_nicht_vorhanden "Kein aktueller Ölstand vorhanden";
CM_ SG_ 967 WIV_Oelsystem_aktiv "Gesamtölsystem aktiv (entspricht Ölsensor verbaut) und das Ölstand-Untermenu im MMI aktiv";
CM_ SG_ 967 WIV_Schieflage "Fahrzeug steht nicht waagerecht, Messung ungenau";
CM_ SG_ 967 WIV_Sensorfehler "Ölstand/Öltemperatursensor (TOG) defekt";
CM_ SG_ 967 WIV_Ueberfuell_deaktiv "Unterdrückung der Warnung im Kombi die durch Signal WIV_Ueberfuel_Warn ausgelöst wird";
CM_ SG_ 967 WIV_Ueberfuell_Warn "Ölstand hat die Überfüllschwelle überschritten";
CM_ SG_ 967 WIV_Unterfuell_Warn "Ölstand hat die Unterfüllschwelle unterschritten";

CM_ SG_ 966 SOK_Motor_26_Signatur "Signatur im Rahmen der durch SOK geschützten Broadcast-Kommunikation

Geschützte Funktion: ORU
Geschützte Botschaft: Motor_26";

CM_ SG_ 1366 MO_Fahrzeugabstellzeit "Zeit seit letzter Fahrbereitschaft.";
CM_ SG_ 1366 MO_Fahrzeugabstellzeit_Status "Status Fahrzeugabstellzeit";
CM_ SG_ 1366 MO_HV_Auszeit "Zeit seit letzter Hochvoltaktivität.";
CM_ SG_ 1366 MO_HV_Auszeit_Status "Status HV-Auszeit.";
CM_ SG_ 1366 MO_Verbau_StartSys_EM_HV "Signal zeigt an, welche Komponenten des Startsystemes verbaut sind.
Verbau E-Maschine HV";
CM_ SG_ 1366 MO_Verbau_StartSys_EM_MV "Signal zeigt an, welche Komponenten des Startsystemes verbaut sind.
Verbau E-Maschine MV z.B. 48V";
CM_ SG_ 1366 MO_Verbau_StartSys_Q_Diode "Signal zeigt an, welche Komponenten des Startsystemes verbaut sind.
Verbau Q_Diode";
CM_ SG_ 1366 MO_Verbau_StartSys_Ritzelstarter "Signal zeigt an, welche Komponenten des Startsystemes verbaut sind.
Verbau Ritzel Starter";
CM_ SG_ 1366 MO_Verbau_StartSys_RSG_MV "Signal zeigt an, welche Komponenten des Startsystemes verbaut sind.
Verbau Riemen Starter Generator MV z.B. 48V";
CM_ SG_ 1366 MO_Verbau_StartSys_RSG_NV "Signal zeigt an, welche Komponenten des Startsystemes verbaut sind.
Verbau Riemen Starter Generator NV z.B. 12V";
CM_ SG_ 1366 MO_Ziel_SoC_Fremdladung "Auf diesen SoC soll MHEV-Speicher geladen werden, wenn ein Ladegerät erkannt ist.";

CM_ SG_ 2589283475 SCR_Einheit "Länderspezifische Einheit der Restreichweite (km oder mi)";
CM_ SG_ 2589283475 SCR_Fuellstand "Füllstand des SCR-Tanks in % bezogen auf das tatsächliche Tankvolumen";
CM_ SG_ 2589283475 SCR_Nachfuellmenge_Einheit "Länderspezifische Einheit der min/max Nachfüllmenge (Liter/Gallone US/Gallone UK)";
CM_ SG_ 2589283475 SCR_Nachfuellmenge_max "Maximales Volumen, mit dem der SCR Tank nachbefüllt werden kann.";
CM_ SG_ 2589283475 SCR_Nachfuellmenge_min "Minimal erforderliche Nachfüllmenge, damit eine Betankung erkannt wird";
CM_ SG_ 2589283475 SCR_Restreichweite "Verbleibende Restreichweite mit aktuellem SCR-Tankinhalt (ohne Dimension)";
CM_ SG_ 2589283475 SCR_Retriggersignal "Trigger zur Erneuerung der SCR Kombibotschaft";
CM_ SG_ 2589283475 SCR_Tankvolumen "Volumen des verbauten SCR Tanks. Dimension abhängig von Signal SCR_Nachfüllmenge_Einheit.";
CM_ SG_ 2589283475 SCR_Zustand "Zustand des SCR Systems, der an das Kombi/MMI übermittelt wird";

CM_ SG_ 1367 AGK_Charisma_FahrPr "Aktuelles Fahrprogramm des Charisma-Teilnehmers Abgasklappen

AGK_Charisma_FahrPr =
0x01 comfort
0x02 auto
0x03 dynamic (Ist-Eigenschaft)";
CM_ SG_ 1367 AGK_Charisma_Status "AGK_Charisma_Status =
0x00 Init
0x01 verfügbar
0x02 nicht verfügbar
0x03 asynchron durch Fahrerwunsch (Teilnehmer-Zustände)
";
CM_ SG_ 1367 MO_Bordnetz_Anf "Das Signal stellt Anforderungen an das Bordnetz:
Initial wird es für die Regeneration in der Abgasnachbehandlung verwendet.";
CM_ SG_ 1367 MO_El_Grundlast_Anf "Anforderung Erzeugung einer elektrischen Grundlast";
CM_ SG_ 1367 Mo_Empf_Red_Genlast "Zur Verbesserung der Motorperformance spricht das Motorsteuergerät eine Empfehlung zur Reduzierung der Generatorlast aus.
Unter Berücksichtigung der Bordnetzstabilität kann das Bordnetzmanagement dieser Empfehlung Folge leisten und auf eine minimal mögli";
CM_ SG_ 1367 MO_FestSpannungsAnf "Anforderung einer ungeregelten Sollspannung vom NVEM";
CM_ SG_ 1367 MO_Freilauf_Charisma_FahrPr "MLBevo: Aktuelles Fahrprogramm des Charisma-Teilnehmers (siehe Systemlastenheft Drive Select)";
CM_ SG_ 1367 MO_Freilauf_Charisma_Status "Charisma Systemstatus des Charisma-Teilnehmers";
CM_ SG_ 1367 MO_Kaltstartleistung_Anf "Motorstartleistungsanforderung basierend auf der gesendeten Kaltstarttemperatur";
CM_ SG_ 1367 MO_Kaltstarttemperatur "Temperatur bei dem Kaltstart erfolgen soll";
CM_ SG_ 1367 MO_Lastabwurf "Übernahme des Signals 'MO7_Lastabwurf' aus PQ-Datenfestlegung";
CM_ SG_ 1367 MO_Strecke_Reg_Anf "Zur Verbesserung des Kat/DPF Heizens und Regenerieren prognostiziert das Motorsteuergerät eine Voraussage in welchen Streckenhorizont eine mögliche Regeneration ansteht.";

CM_ SG_ 706 MO_ADR_Status "Status der Arbeitsdrehzahlregelung";
CM_ SG_ 706 MO_AGA_Sound_Texte "Textausgabe des aktuellen Sound-Zustandes der Abgasklappensteuerung";
CM_ SG_ 706 MO_Anz_Kuehlerluefter "Signal bei aktivem Kühlerlüfternachlauf (Motor aus) im Allgemeinen für die Anzeige im Kombi-Instument zur Information des Kunden über diesen Lüfterlauf";
CM_ SG_ 706 MO_Anzeige_FMAus_Text "Fehlerstatus des FMAus-Systems (z.B. Fehler im Zusatzspeicher)";
CM_ SG_ 706 MO_Anzeige_StSt_Symbol "Steuert die Anzeige der StSt-Symbolik im Kombi";
CM_ SG_ 706 MO_Anzeige_StSt_Text "Steuert die Anzeige der StSt-Texte im Kombi";
CM_ SG_ 706 MO_ElAntrieb_Abschleppwarnung "Warnung, wenn ein Mitschleppen der jeweils bezeichneten Achse zu einer Beschädigung des elektrischen Antriebs führen kann.";
CM_ SG_ 706 MO_EM_Ueberhitzungswarnung "Der elektrische Antrieb ist aufgrund eines Fehlers oder dauerhaft sehr hoher Drehzahl überhitzt.";
CM_ SG_ 706 MO_KEF_Status "Status der Kühlmittelentlüftungsfunktion (KEF) zur niederprioren Anzeige im Kombi.(Daueranzeige solange die Funktion aktiv ist.)";
CM_ SG_ 706 MO_Rekuperationsstufe "In Projekten mit variablen oder anwählbaren Rekuperationsstufen soll dem Fahrer die aktuell ausgewählte Stufe über ein Icon in den Anzeigeinstrumenten visualisiert werden können. Dies dient der Nachvollziehbarkeit für den Kunden in Bezug auf eine zukünfti";
CM_ SG_ 706 MO_SREG_Beladung "Der prozentuale Beladungsgrad des Dieselpartikelfilters wird mit diesem Signal dem KFG bereitgestellt. Somit können weitere Teilfunktion im KFG diesen Wert nutzen.";
CM_ SG_ 706 MO_SREG_Status "Stati zur Standregeneration und Regenerationsverzögerung";
CM_ SG_ 706 MO_VREG_Status "Status der Regenerationsverzögerung";
CM_ SG_ 706 PEA_Texte "Status der Funktion PEA";
CM_ SG_ 706 TSK_Einheit_vMax_FahrerInfo "Einheit zu TSK_vMax_FahrerInfo. Das MSG spiegelt hier KBI_MFA_v_Einheit und stellt den Anzeigewert in dieser Einheit zur Verfügung (kein zyklisches Mux)";
CM_ SG_ 706 TSK_Status_vMax_FahrerInfo "Status der TSK_vMax_FahrerInfo zur Steuerung von PopUps, Fahrzeugstatus und ggf. einer LED. Bei Wert 0 in TSK_vMax_Fahrerinfo soll auf eine unspezifische Begrenzung hingewiesen werden (z.B. wegen Momentenbegrenzung), bei allen anderen Werten soll dieser a";
CM_ SG_ 706 TSK_Ueberstimmt_vMax_FahrerInfo "Information ueber den Zustand wann die vMax-Limitierung vom Fahrer ueberstimmt wird.";
CM_ SG_ 706 TSK_vMax_FahrerInfo "anzuzeigende Begrenzungsgeschwindigkeit bei aktiver HGB";

CM_ SG_ 269 MO_Drehzahl_01 "Im Fehlerfall wird die Motordrehzahl über die Nockenwellendrehzahl als Ersatzgrösse ausgegeben

Bei Parallelhybrid: Getriebeeingangsdrehzahl (=E-Maschinen Drehzahl)

Hinweis: 
Ehemaliger Fehlerwert 0xFFFF wird senderseitig nicht unterstützt. 
Diesen";
CM_ SG_ 269 MO_Drehzahl_VM "Motordrehzahl des Verbrennungsmotors

für OBD freeze frame

Hinweis: 
Ehemaliger Fehlerwert 0xFFFF wird senderseitig nicht unterstützt. 
Diesen Wert aus Kompatibilitätsgründen nicht neu belegen!";
CM_ SG_ 269 MO_EM1_SollDrehzahl "E-Maschinen Soll-Drehzahl";
CM_ SG_ 269 MO_EM2_SollDrehzahl "E-Maschinen Soll-Drehzahl";
CM_ SG_ 269 MO_erste_Ungenauschwelle "Zusätzliche Ungenauigkeit (zur Grundungenauigkeit). Motormomente ungenau >8% (kleinste Ungenauschwelle)
";
CM_ SG_ 269 MO_HYB_E_Faktor "Signed Nibble, verwendet vom GSG zur Interpolation zwischen VMKennfeld und dem Rekuperations-Grenzkennfeld (negative Werte des E-Faktors) bzw. dem Boost-Grenzkennfeld (positive Werte des E-Faktors).
0000 = VM-Kennfeld (keine Interpolation)
0001..0111 = ";
CM_ SG_ 269 MO_HYB_EMode_Info "Hybrid-Mode der Motorsteuerung zur Beeinflussung der Schaltkennfelder im Getriebe. Nicht-Hybridfahrzeuge senden den Initwert.";
CM_ SG_ 269 MO_HYB_Freigabe_VM_Eingr "Hybridsteuerung zeigt an, ob der VM beim Ankoppeln nicht anbrennen darf bzw. anbrennen soll.
";
CM_ SG_ 269 MO_HYB_Komfortstufe "Hybridsteuerung zeigt Startkomfort(-wunsch) an";
CM_ SG_ 269 MO_HYB_LowSpeedModus "MSG legt fest:
0 = klassisches Ausrollen/Anfahren mit N_mot >= N_Leerlauf_VM
1 = elektr. Ausrollen/Anfahren mit geschl. Triebstrang mit N_mot < N_Leerlauf_VM";
CM_ SG_ 269 MO_HYB_max_ind_VM_Mom_02 "inneres maximal mögliches VM-Moment bei einer Drehzahl (z.B. Rauchbegrenzung oder Fehlerfall).";
CM_ SG_ 269 MO_HYB_Modus_Ankopplung_VM "Hybridsteuerung zeigt an, auf welche Weise  der VM angekoppelt werden soll.";
CM_ SG_ 269 MO_HYB_Schaltverhinderung "Schaltungen werden an den DZ-Grenzen (Nullgas-Schaltdrehzahl und Kickdown-Schaltdrehzahl) ausgeführt.";
CM_ SG_ 269 MO_HYB_Sollstatus_K0 "Zusatzinformation zu MO_HYB_Zielzustand, die den  Zielzustand  mit geschlossener bzw. nicht offener K0  weiter differenziert in  die Unterstatus  'schlupfend 'und 'geschlossen'. Zur  Darstellung von asynchronen Ankopplungsvorgängen wie asynchronem Schmier";
CM_ SG_ 269 MO_HYB_Stoppmodus "Hybridsteuerung zeigt an, auf welche Weise gestoppt werden soll.";
CM_ SG_ 269 MO_HYB_VM_bereit "Hybridspezifisches Signal zum VKM-Status beim Ankoppeln,
VKM ist brennbereit";
CM_ SG_ 269 MO_HYB_VM_Mom_oE_02 "Verbrenner-Fahrmoment abzüglich Verbrenner-Verlustmoment. Vorzeichenbehaftet. Für Benutzung in Getriebe-Schaltstrategie";
CM_ SG_ 269 MO_HYB_Zielzustand "Ziel-Betriebszustand des Hybriden, definiert die gewünschten Status der K0 und der Getriebekupplungen.
Der Zielzustand  gibt dabei u.a. an, ob der VM angekoppelt ist oder nicht. Er beinhaltet nicht die Information, ob der VM tatsächlich einspritzt und an";
CM_ SG_ 269 MO_Luftpfad_Verzugszeit_praed "Aktuelle Verzugszeit des luftführenden Systems im Motor, welche dem Getriebe bereitgestellt wird, um reduzierende Momenteneingriffe einer Hochschaltung entsprechend dieser Zeit zu prädizieren.";
CM_ SG_ 269 MO_Mom_Begr_Fahr "Einheitenloser Wert! Faktor in MO_Faktor_Momente (CAN V6.x) bzw. MO_Faktor_Momente_02 (CAN V7.x und höher) in Motor_Code_01 beachten!

Bei aktueller Drehzahl quasistationär (nach ca. 3…5 s) max. mögliches Getriebeeingangsmoment (Summe aus Verbrennungsmo";
CM_ SG_ 269 MO_Mom_Begr_Schalt "Einheitenloser Wert! Faktor in MO_Faktor_Momente (CAN V6.x) bzw. MO_Faktor_Momente_02 (CAN V7.x/8.x) in Motor_Code_01 beachten!

Bei aktueller Drehzahl kurzfristig (ca. 100..200 ms) für momentenerhöhende Getriebeeingriffe max. zur Verfügung stehendes Ge";
CM_ SG_ 269 MO_Mom_Ist_Summe "Einheitenloser Wert! Faktor in MO_Faktor_Momente_02 in Motor_Code_01 beachten!

Ist-Moment als Summe aus Verbrennungsmotor und E-Motor (bei Hybrid-Konzepten) incl. allen Eingriffen und Korrekturen

In Fahrzeugen mit einer Antriebsachse bzw. mit mechan";
CM_ SG_ 269 MO_Mom_neg_verfuegbar "Einheitenloser Wert! Faktor in MO_Faktor_Momente (CAN V6.x) bzw. MO_Faktor_Momente_02 (CAN V7.x) in Motor_Code_01 beachten!

Bei aktueller Drehzahl im nächsten Task (bei CAN-Übertragung z.B. 10ms) tatsächlich verfügbares negatives Moment (Summe aus Verl";
CM_ SG_ 269 MO_Mom_Schub "Einheitenloser Wert! Faktor in MO_Faktor_Momente_02 in Motor_Code_01 beachten!

Moment das sich einstellt, wenn der Fahrer 0% Fahrpedal gibt; bei konventionellen Projekten = alle Verluste (mechanische Reibung und sonstige Verluste) des Verbrennungsmotor";
CM_ SG_ 269 MO_Mom_Soll_gefiltert "Einheitenloser Wert! Faktor in MO_Faktor_Momente_02 in Motor_Code_01 beachten!

MO_Mom_Soll_Roh nach Fahrverhaltensfilter, begrenzt nach oben mit MO_Mom_Begr_dyn, Einrechnung der plausibilisierten Bremsen-Eingriffe; ohne Getriebe-Schalt-Eingriffe, ohne ";
CM_ SG_ 269 MO_Mom_Soll_Roh "Einheitenloser Wert! Faktor in MO_Faktor_Momente_02 in Motor_Code_01 beachten!

Momentenanforderung aus Fahrpedal bzw. von ACC/GRA bzw. aus dem Leerlaufregler (quasistatischer Anteil) bzw. aus Rekuperationsanforderung; keine Begrenzungen, keine Filterun";
CM_ SG_ 269 MO_Mom_Traegheit_Summe "Einheitenloser Wert! Faktor in MO_Faktor_Momente (CAN V6.x) bzw. MO_Faktor_Momente_02 (CAN V7.x) in Motor_Code_01 beachten!

Moment, das zur Beschleunigung der trägen Massen aufgewendet wird bzw. frei wird; Summen aus Anteilen für Verbrennungsmotor und ";
CM_ SG_ 269 MO_Momentenintegral_02 "100  %  entspricht volle Verfügbarkeit aktuell vorhanden. 0 % entspricht Integral bis Limit gefüllt, erhöhender Eingriff kann aktuell nicht berücksichtigt werden oder aufgrund eines Fehlers nicht verfügbar
";
CM_ SG_ 269 MO_QBit_Drehzahl_01 "AUDI D4: Zykluszeit: 10ms (siehe Zykluszeit schnell/Cycletime Fast)

Achtung:
Reduktion der Zykluszeit Motor_03 auf 10ms geplant.
Projektabhängig soll künftig mit 10ms gesendet werden.
Empfänger die in weiteren Konzern-Projekten eingesetzt werden müs";
CM_ SG_ 269 MO_QBit_Motormomente "AUDI D4: Zykluszeit: 10ms (siehe Zykluszeit schnell/Cycletime Fast)

Ungenaue Momentenangaben, weil die Momente aus Ersatzwerten berechnet wurden (z.B. HFM ausgefallen). Qualifizierungsbit für die Motormomente.

Achtung:
Reduktion der Zykluszeit Moto";
CM_ SG_ 269 MO_Status_Normalbetrieb_01 "Das Motorsteuergerät sendet das Informationsbit, wenn die Initialisierungsphase des Steuergerätes abgeschlossen ist. Zusätzlich muss die Klemme 15 eingeschalten sein und eine applizierbare Mindestdrehzahlschwelle (Kennlinie in Abh. von der Kühlwassertempe";
CM_ SG_ 269 MO_TNW_Max_Strom_Lim "maximal zulässiger HV-Strom, der von dem TNW (Traktionsnetzwandler) im motorischen Betrieb aufgenommen werden darf; Abregelstrom zum Einhalten der HV-Systemgrenzen (Bauteilschutz)";
CM_ SG_ 269 MO_TNW_Min_Strom_Lim "minimal zulässiger HV-Strom, der von dem TNW (Traktionsnetzwandler) im generatorischen Betrieb abgegeben werden darf (betragsmäßig maximal aber i.d.R. negativ, daher ‚Min‘); Abregelstrom zum Einhalten der HV-Systemgrenzen (Bauteilschutz)";
CM_ SG_ 269 Motor_50_BZ "4bit Botschaftszähler, wird mit jeder Sendebotschaft inkrementiert";
CM_ SG_ 269 Motor_50_CRC "Für MLB:
Berechnung siehe Lastenheft 'Kommunikationsabsicherung für FlexRay und CAN'
Ab MQB und MLBevo:
Berechnung siehe Lastenheft 'End-to-End Kommunikationsabsicherung'

Endwerte siehe Begleitdokument 'S-PDU Kennungsfolgen'";
BA_DEF_REL_ BU_SG_REL_  "GenSigTimeoutTime" INT 0 65535;
BA_DEF_ BO_  "DiagRequest" ENUM "No", "Yes";
BA_DEF_ BO_  "DiagResponse" ENUM "No", "Yes";
BA_DEF_ BO_  "DiagState" ENUM "No", "Yes";
BA_DEF_ BO_  "GenMsgChkConstant" HEX 0 4095;
BA_DEF_ BO_  "GenMsgCycleTime" INT 0 65535;
BA_DEF_ BO_  "GenMsgCycleTimeFast" INT 0 65535;
BA_DEF_ BO_  "GenMsgDelayTime" INT 0 100000;
BA_DEF_ BO_  "GenMsgILSupport" ENUM "No", "Yes";
BA_DEF_ BO_  "GenMsgNrOfRepetition" INT 0 100;
BA_DEF_ BO_  "GenMsgPDUConstants" STRING;
BA_DEF_ BO_  "GenMsgSendType" ENUM "Cyclic", "not_used", "not_used", "not_used", "not_used", "not_used", "not_used", "IfActive", "NoMsgSendType";
BA_DEF_ BO_  "GenMsgStartDelayTime" INT 0 100000;
BA_DEF_ BO_  "NmMessage" ENUM "No", "Yes";
BA_DEF_ BO_  "NmhMessage" ENUM "No", "Yes";
BA_DEF_ BO_  "MsgType" ENUM "Application", "NM ", "NMH", "TP2.0", "ISO-TP ", "BAP", "EID", "KS", "XCP_PRE_CONFIGURED", "XCP_RUNTIME_CONFIGURED";
BA_DEF_ BO_  "VAGTP20_API" HEX 0 255;
BA_DEF_ BO_  "VAGTP20_DynConnection" ENUM "No", "Yes";
BA_DEF_ BO_  "VAGTP20_DynSetup" ENUM "No", "Yes";
BA_DEF_ BO_  "VAGTP20_StatConnection" ENUM "No", "Yes";
BA_DEF_ BO_  "CANFD_BRS" ENUM "0", "1";
BA_DEF_ BO_  "VFrameFormat" ENUM "StandardCAN", "ExtendedCAN", "reserved", "reserved", "reserved", "reserved", "reserved", "reserved", "reserved", "reserved", "reserved", "reserved", "reserved", "reserved", "StandardCAN_FD", "ExtendedCAN_FD";
BA_DEF_ SG_  "GenSigActiveRepetitions" INT -2147483648 2147483647;
BA_DEF_ SG_  "GenSigInactiveValue" INT -2147483648 2147483647;
BA_DEF_ SG_  "GenSigSendType" ENUM "Cyclic", "OnWrite", "OnWriteWithRepetition", "OnChange", "OnChangeWithRepetition", "IfActive", "IfActiveWithRepetition", "NoSigSendType", "OnChangeAndIfActive", "OnChangeAndIfActiveWithRepetition";
BA_DEF_ SG_  "GenSigStartValue" INT -2147483648 2147483647;
BA_DEF_ SG_  "NWM-WakeupAllowed" ENUM "No", "Yes";
BA_DEF_ SG_  "GenSigFuncType" ENUM "NoFunction", "MsgCounter", "CRC-8", "XOR", "XOR-2", "DatedBit", "SW-Kl15", "CHK", "Constant", "Protocol", "CRC-8-SAE_J1850", "CRC-32", "DataLength", "DataID", "MsgCounter16", "SOK-Signatur", "Cluster";
BA_DEF_ SG_  "GenSigSwitchedByIgnition" ENUM "No", "Yes";
BA_DEF_ SG_  "Fehlerwert" HEX 0 2147483647;
BA_DEF_ SG_  "GenSigMissingSourceValue" HEX 0 2147483647;
BA_DEF_DEF_REL_  "GenSigTimeoutTime" 0;
BA_DEF_DEF_  "DiagRequest" "No";
BA_DEF_DEF_  "DiagResponse" "No";
BA_DEF_DEF_  "DiagState" "No";
BA_DEF_DEF_  "GenMsgChkConstant" 0;
BA_DEF_DEF_  "GenMsgCycleTime" 0;
BA_DEF_DEF_  "GenMsgCycleTimeFast" 0;
BA_DEF_DEF_  "GenMsgDelayTime" 0;
BA_DEF_DEF_  "GenMsgILSupport" "No";
BA_DEF_DEF_  "GenMsgNrOfRepetition" 0;
BA_DEF_DEF_  "GenMsgPDUConstants" "";
BA_DEF_DEF_  "GenMsgSendType" "NoMsgSendType";
BA_DEF_DEF_  "GenMsgStartDelayTime" 0;
BA_DEF_DEF_  "NmMessage" "No";
BA_DEF_DEF_  "NmhMessage" "No";
BA_DEF_DEF_  "MsgType" "Application";
BA_DEF_DEF_  "VAGTP20_API" 0;
BA_DEF_DEF_  "VAGTP20_DynConnection" "No";
BA_DEF_DEF_  "VAGTP20_DynSetup" "No";
BA_DEF_DEF_  "VAGTP20_StatConnection" "No";
BA_DEF_DEF_  "CANFD_BRS" "1";
BA_DEF_DEF_  "VFrameFormat" "StandardCAN";
BA_DEF_DEF_  "GenSigActiveRepetitions" 0;
BA_DEF_DEF_  "GenSigInactiveValue" 0;
BA_DEF_DEF_  "GenSigSendType" "NoSigSendType";
BA_DEF_DEF_  "GenSigStartValue" 0;
BA_DEF_DEF_  "NWM-WakeupAllowed" "No";
BA_DEF_DEF_  "GenSigFuncType" "NoFunction";
BA_DEF_DEF_  "GenSigSwitchedByIgnition" "Yes";
BA_DEF_DEF_  "Fehlerwert" 0;
BA_DEF_DEF_  "GenSigMissingSourceValue" 0;
BA_ "GenMsgChkConstant" BO_ 1171 151;
BA_ "GenMsgCycleTime" BO_ 1171 200;
BA_ "GenMsgDelayTime" BO_ 1171 20;
BA_ "GenMsgILSupport" BO_ 1171 1;
BA_ "GenMsgPDUConstants" BO_ 1171 "0x97,0x97,0x97,0x97,0x97,0x97,0x97,0x97,0x97,0x97,0x97,0x97,0x97,0x97,0x97,0x97";
BA_ "GenMsgSendType" BO_ 1171 0;
BA_ "VFrameFormat" BO_ 1171 14;
BA_ "GenMsgCycleTime" BO_ 1165 200;
BA_ "GenMsgILSupport" BO_ 1165 1;
BA_ "GenMsgPDUConstants" BO_ 1165 "0x84,0xcb,0x82,0xa1,0x41,0xe2,0xfa,0x9a,0x90,0x5e,0x51,0xe3,0xe8,0xc4,0x7f,0xf1";
BA_ "GenMsgSendType" BO_ 1165 0;
BA_ "VFrameFormat" BO_ 1165 14;
BA_ "GenMsgCycleTime" BO_ 817 500;
BA_ "GenMsgCycleTimeFast" BO_ 817 30;
BA_ "GenMsgDelayTime" BO_ 817 30;
BA_ "GenMsgILSupport" BO_ 817 1;
BA_ "GenMsgSendType" BO_ 817 0;
BA_ "VFrameFormat" BO_ 817 14;
BA_ "GenMsgCycleTime" BO_ 329 100;
BA_ "GenMsgCycleTimeFast" BO_ 329 10;
BA_ "GenMsgDelayTime" BO_ 329 10;
BA_ "GenMsgILSupport" BO_ 329 1;
BA_ "GenMsgNrOfRepetition" BO_ 329 3;
BA_ "GenMsgPDUConstants" BO_ 329 "0x77,0x41,0xe8,0xa3,0x7d,0xe9,0x34,0xee,0x15,0x17,0x70,0x28,0x5b,0x24,0x08,0x80";
BA_ "GenMsgSendType" BO_ 329 0;
BA_ "VFrameFormat" BO_ 329 14;
BA_ "GenMsgCycleTimeFast" BO_ 15 10;
BA_ "GenMsgILSupport" BO_ 15 1;
BA_ "GenMsgSendType" BO_ 15 7;
BA_ "VFrameFormat" BO_ 15 14;
BA_ "GenMsgCycleTime" BO_ 1600 500;
BA_ "GenMsgILSupport" BO_ 1600 1;
BA_ "GenMsgSendType" BO_ 1600 0;
BA_ "VFrameFormat" BO_ 1600 14;
BA_ "GenMsgCycleTime" BO_ 1607 500;
BA_ "GenMsgILSupport" BO_ 1607 1;
BA_ "GenMsgSendType" BO_ 1607 0;
BA_ "VFrameFormat" BO_ 1607 14;
BA_ "GenMsgCycleTime" BO_ 958 100;
BA_ "GenMsgDelayTime" BO_ 958 10;
BA_ "GenMsgILSupport" BO_ 958 1;
BA_ "GenMsgPDUConstants" BO_ 958 "0x1f,0x28,0xc6,0x85,0xe6,0xf8,0xb0,0x19,0x5b,0x64,0x35,0x21,0xe4,0xf7,0x9c,0x24";
BA_ "GenMsgSendType" BO_ 958 0;
BA_ "VFrameFormat" BO_ 958 14;
BA_ "GenMsgCycleTime" BO_ 1631 500;
BA_ "GenMsgILSupport" BO_ 1631 1;
BA_ "GenMsgSendType" BO_ 1631 0;
BA_ "VFrameFormat" BO_ 1631 14;
BA_ "GenMsgCycleTime" BO_ 1648 500;
BA_ "GenMsgDelayTime" BO_ 1648 20;
BA_ "GenMsgILSupport" BO_ 1648 1;
BA_ "GenMsgSendType" BO_ 1648 0;
BA_ "VFrameFormat" BO_ 1648 14;
BA_ "GenMsgCycleTime" BO_ 1654 1000;
BA_ "GenMsgDelayTime" BO_ 1654 200;
BA_ "GenMsgILSupport" BO_ 1654 1;
BA_ "GenMsgSendType" BO_ 1654 0;
BA_ "VFrameFormat" BO_ 1654 14;
BA_ "GenMsgCycleTime" BO_ 1391 500;
BA_ "GenMsgILSupport" BO_ 1391 1;
BA_ "GenMsgSendType" BO_ 1391 0;
BA_ "VFrameFormat" BO_ 1391 14;
BA_ "GenMsgCycleTime" BO_ 967 100;
BA_ "GenMsgILSupport" BO_ 967 1;
BA_ "GenMsgSendType" BO_ 967 0;
BA_ "VFrameFormat" BO_ 967 14;
BA_ "GenMsgCycleTime" BO_ 966 100;
BA_ "GenMsgSendType" BO_ 966 0;
BA_ "VFrameFormat" BO_ 966 14;
BA_ "GenMsgCycleTime" BO_ 1366 1000;
BA_ "GenMsgILSupport" BO_ 1366 1;
BA_ "GenMsgSendType" BO_ 1366 0;
BA_ "VFrameFormat" BO_ 1366 14;
BA_ "GenMsgCycleTime" BO_ 2589283475 1000;
BA_ "GenMsgILSupport" BO_ 2589283475 1;
BA_ "GenMsgSendType" BO_ 2589283475 0;
BA_ "VFrameFormat" BO_ 2589283475 15;
BA_ "GenMsgCycleTime" BO_ 1367 500;
BA_ "GenMsgDelayTime" BO_ 1367 50;
BA_ "GenMsgILSupport" BO_ 1367 1;
BA_ "GenMsgSendType" BO_ 1367 0;
BA_ "VFrameFormat" BO_ 1367 14;
BA_ "GenMsgCycleTime" BO_ 706 500;
BA_ "GenMsgDelayTime" BO_ 706 100;
BA_ "GenMsgILSupport" BO_ 706 1;
BA_ "GenMsgSendType" BO_ 706 0;
BA_ "VFrameFormat" BO_ 706 14;
BA_ "GenMsgCycleTime" BO_ 269 10;
BA_ "GenMsgILSupport" BO_ 269 1;
BA_ "GenMsgPDUConstants" BO_ 269 "0x0f,0x67,0x6e,0x8a,0xa9,0xae,0x23,0x22,0x77,0x4d,0xf9,0xd0,0x81,0x51,0x9c,0x80";
BA_ "GenMsgSendType" BO_ 269 0;
BA_ "VFrameFormat" BO_ 269 14;
BA_ "GenSigSendType" SG_ 1171 MF_Abzugssperre 3;
BA_ "GenSigSwitchedByIgnition" SG_ 1171 MF_Abzugssperre 0;
BA_ "GenSigSendType" SG_ 1171 MF_Alarm_Blinker 3;
BA_ "GenSigSwitchedByIgnition" SG_ 1171 MF_Alarm_Blinker 0;
BA_ "GenSigSendType" SG_ 1171 MF_Alarm_Blinkertakt 3;
BA_ "GenSigSwitchedByIgnition" SG_ 1171 MF_Alarm_Blinkertakt 0;
BA_ "GenSigSendType" SG_ 1171 MF_Anlassersperre 3;
BA_ "GenSigSwitchedByIgnition" SG_ 1171 MF_Anlassersperre 0;
BA_ "GenSigSendType" SG_ 1171 MF_Blk_li 3;
BA_ "GenSigSwitchedByIgnition" SG_ 1171 MF_Blk_li 0;
BA_ "GenSigSendType" SG_ 1171 MF_Blk_re 3;
BA_ "GenSigSwitchedByIgnition" SG_ 1171 MF_Blk_re 0;
BA_ "GenSigSendType" SG_ 1171 MF_BT_entriegeln 3;
BA_ "GenSigSwitchedByIgnition" SG_ 1171 MF_BT_entriegeln 0;
BA_ "GenSigSendType" SG_ 1171 MF_BT_verriegeln 3;
BA_ "GenSigSwitchedByIgnition" SG_ 1171 MF_BT_verriegeln 0;
BA_ "GenSigSendType" SG_ 1171 MF_Fahrlicht 3;
BA_ "GenSigSwitchedByIgnition" SG_ 1171 MF_Fahrlicht 0;
BA_ "GenSigSendType" SG_ 1171 MF_Fernbed_ein 3;
BA_ "GenSigSwitchedByIgnition" SG_ 1171 MF_Fernbed_ein 0;
BA_ "GenSigSendType" SG_ 1171 MF_Fernlicht 3;
BA_ "GenSigSwitchedByIgnition" SG_ 1171 MF_Fernlicht 0;
BA_ "GenSigSendType" SG_ 1171 MF_FH_BT_hoch 3;
BA_ "GenSigSwitchedByIgnition" SG_ 1171 MF_FH_BT_hoch 0;
BA_ "GenSigSendType" SG_ 1171 MF_FH_BT_tief 3;
BA_ "GenSigSwitchedByIgnition" SG_ 1171 MF_FH_BT_tief 0;
BA_ "GenSigSendType" SG_ 1171 MF_FH_FT_hoch 3;
BA_ "GenSigSwitchedByIgnition" SG_ 1171 MF_FH_FT_hoch 0;
BA_ "GenSigSendType" SG_ 1171 MF_FH_FT_tief 3;
BA_ "GenSigSwitchedByIgnition" SG_ 1171 MF_FH_FT_tief 0;
BA_ "GenSigSendType" SG_ 1171 MF_Frontintervall 3;
BA_ "GenSigSwitchedByIgnition" SG_ 1171 MF_Frontintervall 0;
BA_ "GenSigSendType" SG_ 1171 MF_Frontwaschen 3;
BA_ "GenSigSwitchedByIgnition" SG_ 1171 MF_Frontwaschen 0;
BA_ "GenSigSendType" SG_ 1171 MF_FT_entriegeln 3;
BA_ "GenSigSwitchedByIgnition" SG_ 1171 MF_FT_entriegeln 0;
BA_ "GenSigSendType" SG_ 1171 MF_FT_verriegeln 3;
BA_ "GenSigSwitchedByIgnition" SG_ 1171 MF_FT_verriegeln 0;
BA_ "GenSigSendType" SG_ 1171 MF_Fussraumbel 3;
BA_ "GenSigSwitchedByIgnition" SG_ 1171 MF_Fussraumbel 0;
BA_ "GenSigSendType" SG_ 1171 MF_HBFS_entriegeln 3;
BA_ "GenSigSwitchedByIgnition" SG_ 1171 MF_HBFS_entriegeln 0;
BA_ "GenSigSendType" SG_ 1171 MF_HBFS_verriegeln 3;
BA_ "GenSigSwitchedByIgnition" SG_ 1171 MF_HBFS_verriegeln 0;
BA_ "GenSigSendType" SG_ 1171 MF_Heckintervall 3;
BA_ "GenSigSwitchedByIgnition" SG_ 1171 MF_Heckintervall 0;
BA_ "GenSigSendType" SG_ 1171 MF_Heckwaschen 3;
BA_ "GenSigSwitchedByIgnition" SG_ 1171 MF_Heckwaschen 0;
BA_ "GenSigSendType" SG_ 1171 MF_HFS_entriegeln 3;
BA_ "GenSigSwitchedByIgnition" SG_ 1171 MF_HFS_entriegeln 0;
BA_ "GenSigSendType" SG_ 1171 MF_HFS_verriegeln 3;
BA_ "GenSigSwitchedByIgnition" SG_ 1171 MF_HFS_verriegeln 0;
BA_ "GenSigSendType" SG_ 1171 MF_Innenraumbel 3;
BA_ "GenSigSwitchedByIgnition" SG_ 1171 MF_Innenraumbel 0;
BA_ "GenSigSendType" SG_ 1171 MF_Innenraumbel_Unterdrueck 3;
BA_ "GenSigSwitchedByIgnition" SG_ 1171 MF_Innenraumbel_Unterdrueck 0;
BA_ "GenSigSendType" SG_ 1171 MF_interm_Fahrlicht 3;
BA_ "GenSigSwitchedByIgnition" SG_ 1171 MF_interm_Fahrlicht 0;
BA_ "GenSigSendType" SG_ 1171 MF_interm_Fernlicht 3;
BA_ "GenSigSwitchedByIgnition" SG_ 1171 MF_interm_Fernlicht 0;
BA_ "GenSigSendType" SG_ 1171 MF_interm_Takt 3;
BA_ "GenSigSwitchedByIgnition" SG_ 1171 MF_interm_Takt 0;
BA_ "GenSigSendType" SG_ 1171 MF_Laderelais 3;
BA_ "GenSigSwitchedByIgnition" SG_ 1171 MF_Laderelais 0;
BA_ "GenSigSendType" SG_ 1171 MF_Lichthupe 3;
BA_ "GenSigSwitchedByIgnition" SG_ 1171 MF_Lichthupe 0;
BA_ "GenSigSendType" SG_ 1171 MF_Motorweiterlauf 3;
BA_ "GenSigSwitchedByIgnition" SG_ 1171 MF_Motorweiterlauf 0;
BA_ "GenSigSendType" SG_ 1171 MF_nachtr_Stopp_Anf 0;
BA_ "GenSigSwitchedByIgnition" SG_ 1171 MF_nachtr_Stopp_Anf 0;
BA_ "GenSigSendType" SG_ 1171 MF_Notstart 3;
BA_ "GenSigSwitchedByIgnition" SG_ 1171 MF_Notstart 0;
BA_ "GenSigSendType" SG_ 1171 MF_Schluessel_scan 3;
BA_ "GenSigSwitchedByIgnition" SG_ 1171 MF_Schluessel_scan 0;
BA_ "GenSigSendType" SG_ 1171 MF_Signalhorn 3;
BA_ "GenSigSwitchedByIgnition" SG_ 1171 MF_Signalhorn 0;
BA_ "GenSigSendType" SG_ 1171 MF_Standlicht 3;
BA_ "GenSigSwitchedByIgnition" SG_ 1171 MF_Standlicht 0;
BA_ "GenSigSendType" SG_ 1171 MF_StartStopp_Info 0;
BA_ "GenSigSwitchedByIgnition" SG_ 1171 MF_StartStopp_Info 0;
BA_ "GenSigSendType" SG_ 1171 MF_Summer 3;
BA_ "GenSigSwitchedByIgnition" SG_ 1171 MF_Summer 0;
BA_ "GenSigSendType" SG_ 1171 MF_TFL_Abschaltung 3;
BA_ "GenSigSwitchedByIgnition" SG_ 1171 MF_TFL_Abschaltung 0;
BA_ "GenSigSendType" SG_ 1171 MF_Tippwischen 3;
BA_ "GenSigSwitchedByIgnition" SG_ 1171 MF_Tippwischen 0;
BA_ "GenSigSendType" SG_ 1171 MF_Tuerentriegelung_hinten 3;
BA_ "GenSigSwitchedByIgnition" SG_ 1171 MF_Tuerentriegelung_hinten 0;
BA_ "GenSigSendType" SG_ 1171 MF_Variante 3;
BA_ "GenSigSwitchedByIgnition" SG_ 1171 MF_Variante 0;
BA_ "GenSigSendType" SG_ 1171 MF_Warnblinker 3;
BA_ "GenSigSwitchedByIgnition" SG_ 1171 MF_Warnblinker 0;
BA_ "GenSigSendType" SG_ 1171 MF_Wischerstufe_1 3;
BA_ "GenSigSwitchedByIgnition" SG_ 1171 MF_Wischerstufe_1 0;
BA_ "GenSigSendType" SG_ 1171 MF_Wischerstufe_2 3;
BA_ "GenSigSwitchedByIgnition" SG_ 1171 MF_Wischerstufe_2 0;
BA_ "GenSigSendType" SG_ 1171 MF_ZV_Lock 3;
BA_ "GenSigSwitchedByIgnition" SG_ 1171 MF_ZV_Lock 0;
BA_ "GenSigSendType" SG_ 1171 MFG_01_BZ 0;
BA_ "GenSigFuncType" SG_ 1171 MFG_01_BZ 1;
BA_ "GenSigSwitchedByIgnition" SG_ 1171 MFG_01_BZ 0;
BA_ "GenSigSendType" SG_ 1171 MFG_01_CRC 0;
BA_ "GenSigFuncType" SG_ 1171 MFG_01_CRC 2;
BA_ "GenSigSwitchedByIgnition" SG_ 1171 MFG_01_CRC 0;
BA_ "GenSigSendType" SG_ 1165 MF_ADR_Anforderung 0;
BA_ "GenSigSendType" SG_ 1165 MF_ADR_Fahrpedalsperre 0;
BA_ "GenSigSwitchedByIgnition" SG_ 1165 MF_ADR_Fahrpedalsperre 0;
BA_ "GenSigSendType" SG_ 1165 MF_ADR_neg_Rampe 0;
BA_ "GenSigSwitchedByIgnition" SG_ 1165 MF_ADR_neg_Rampe 0;
BA_ "GenSigSendType" SG_ 1165 MF_ADR_pos_Rampe 0;
BA_ "GenSigSendType" SG_ 1165 MF_ADR_Solldrehzahl 0;
BA_ "GenSigSendType" SG_ 1165 MF_MFSS_aktiv 0;
BA_ "GenSigSendType" SG_ 1165 MF_MFSS_kodiert 0;
BA_ "GenSigSwitchedByIgnition" SG_ 1165 MF_MFSS_kodiert 0;
BA_ "GenSigSendType" SG_ 1165 MF_VBEG_Anforderung 0;
BA_ "GenSigSendType" SG_ 1165 MF_VBEG_Geschwindigkeit 0;
BA_ "GenSigStartValue" SG_ 1165 MF_VBEG_Geschwindigkeit 255;
BA_ "GenSigSendType" SG_ 1165 MFG_02_BZ 0;
BA_ "GenSigFuncType" SG_ 1165 MFG_02_BZ 1;
BA_ "GenSigSendType" SG_ 1165 MFG_02_CRC 0;
BA_ "GenSigFuncType" SG_ 1165 MFG_02_CRC 2;
BA_ "GenSigSendType" SG_ 1165 MFG_Heizstufe_LSH 0;
BA_ "GenSigSwitchedByIgnition" SG_ 1165 MFG_Heizstufe_LSH 0;
BA_ "Fehlerwert" SG_ 1165 MFG_Heizstufe_LSH 15;
BA_ "GenSigSendType" SG_ 1165 MFG_Status_SREG 0;
BA_ "GenSigSwitchedByIgnition" SG_ 1165 MFG_Status_SREG 0;
BA_ "GenSigSendType" SG_ 1165 MFG_Taster_SREG 0;
BA_ "GenSigStartValue" SG_ 1165 MFG_Taster_SREG 2;
BA_ "GenSigSwitchedByIgnition" SG_ 1165 MFG_Taster_SREG 0;
BA_ "Fehlerwert" SG_ 1165 MFG_Taster_SREG 3;
BA_ "GenSigSendType" SG_ 1165 MFG_Taster_VREG 0;
BA_ "GenSigStartValue" SG_ 1165 MFG_Taster_VREG 2;
BA_ "GenSigSwitchedByIgnition" SG_ 1165 MFG_Taster_VREG 0;
BA_ "Fehlerwert" SG_ 1165 MFG_Taster_VREG 3;
BA_ "GenSigSendType" SG_ 1165 MFG_Zuheizer_Freigabe 0;
BA_ "GenSigSwitchedByIgnition" SG_ 1165 MFG_Zuheizer_Freigabe 0;
BA_ "GenSigSendType" SG_ 817 MFL_Dummy_0_Signal_2 0;
BA_ "GenSigSwitchedByIgnition" SG_ 817 MFL_Dummy_0_Signal_2 0;
BA_ "GenSigSendType" SG_ 817 MFL_Dummy_0_Signal_3 0;
BA_ "GenSigSwitchedByIgnition" SG_ 817 MFL_Dummy_0_Signal_3 0;
BA_ "GenSigSendType" SG_ 817 MFL_Dummy_0_Signal_4 0;
BA_ "GenSigSwitchedByIgnition" SG_ 817 MFL_Dummy_0_Signal_4 0;
BA_ "GenSigSendType" SG_ 817 MFL_ECU_Err 0;
BA_ "GenSigSwitchedByIgnition" SG_ 817 MFL_ECU_Err 0;
BA_ "Fehlerwert" SG_ 817 MFL_ECU_Err 1;
BA_ "GenSigSendType" SG_ 817 MFL_Eventcode_1 0;
BA_ "GenSigSwitchedByIgnition" SG_ 817 MFL_Eventcode_1 0;
BA_ "GenSigSendType" SG_ 817 MFL_Eventcode_2 0;
BA_ "GenSigSwitchedByIgnition" SG_ 817 MFL_Eventcode_2 0;
BA_ "GenSigSendType" SG_ 817 MFL_Lokalaktiv 0;
BA_ "GenSigSwitchedByIgnition" SG_ 817 MFL_Lokalaktiv 0;
BA_ "GenSigSendType" SG_ 817 MFL_LR_HZG_Err 0;
BA_ "GenSigSwitchedByIgnition" SG_ 817 MFL_LR_HZG_Err 0;
BA_ "Fehlerwert" SG_ 817 MFL_LR_HZG_Err 1;
BA_ "GenSigSendType" SG_ 817 MFL_LR_HZG_Status 0;
BA_ "GenSigSwitchedByIgnition" SG_ 817 MFL_LR_HZG_Status 0;
BA_ "GenSigSendType" SG_ 817 MFL_M_Taste 0;
BA_ "GenSigSendType" SG_ 817 MFL_Marke 0;
BA_ "GenSigFuncType" SG_ 817 MFL_Marke 8;
BA_ "GenSigSwitchedByIgnition" SG_ 817 MFL_Marke 0;
BA_ "GenSigSendType" SG_ 817 MFL_Paddle_Verbau 0;
BA_ "GenSigSwitchedByIgnition" SG_ 817 MFL_Paddle_Verbau 0;
BA_ "GenSigSendType" SG_ 817 MFL_Response_Err 0;
BA_ "GenSigSwitchedByIgnition" SG_ 817 MFL_Response_Err 0;
BA_ "Fehlerwert" SG_ 817 MFL_Response_Err 1;
BA_ "GenSigSendType" SG_ 817 MFL_SatModul_links_Err 0;
BA_ "GenSigFuncType" SG_ 817 MFL_SatModul_links_Err 5;
BA_ "GenSigSwitchedByIgnition" SG_ 817 MFL_SatModul_links_Err 0;
BA_ "Fehlerwert" SG_ 817 MFL_SatModul_links_Err 1;
BA_ "GenSigSendType" SG_ 817 MFL_SatModul_rechts_Err 0;
BA_ "GenSigFuncType" SG_ 817 MFL_SatModul_rechts_Err 5;
BA_ "GenSigSwitchedByIgnition" SG_ 817 MFL_SatModul_rechts_Err 0;
BA_ "Fehlerwert" SG_ 817 MFL_SatModul_rechts_Err 1;
BA_ "GenSigSendType" SG_ 817 MFL_Signalhorn 5;
BA_ "GenSigSwitchedByIgnition" SG_ 817 MFL_Signalhorn 0;
BA_ "GenSigSendType" SG_ 817 MFL_Signalhorn_Err 0;
BA_ "GenSigSwitchedByIgnition" SG_ 817 MFL_Signalhorn_Err 0;
BA_ "Fehlerwert" SG_ 817 MFL_Signalhorn_Err 1;
BA_ "GenSigSendType" SG_ 817 MFL_Taste_links_Err 0;
BA_ "GenSigSwitchedByIgnition" SG_ 817 MFL_Taste_links_Err 0;
BA_ "Fehlerwert" SG_ 817 MFL_Taste_links_Err 1;
BA_ "GenSigSendType" SG_ 817 MFL_Taste_rechts_Err 0;
BA_ "GenSigSwitchedByIgnition" SG_ 817 MFL_Taste_rechts_Err 0;
BA_ "Fehlerwert" SG_ 817 MFL_Taste_rechts_Err 1;
BA_ "GenSigSendType" SG_ 817 MFL_Tastencode_1 0;
BA_ "GenSigSwitchedByIgnition" SG_ 817 MFL_Tastencode_1 0;
BA_ "GenSigSendType" SG_ 817 MFL_Tastencode_2 0;
BA_ "GenSigSwitchedByIgnition" SG_ 817 MFL_Tastencode_2 0;
BA_ "GenSigSendType" SG_ 817 MFL_Tip_Down 5;
BA_ "GenSigSendType" SG_ 817 MFL_Tip_links_Err 0;
BA_ "GenSigSwitchedByIgnition" SG_ 817 MFL_Tip_links_Err 0;
BA_ "Fehlerwert" SG_ 817 MFL_Tip_links_Err 1;
BA_ "GenSigSendType" SG_ 817 MFL_Tip_rechts_Err 0;
BA_ "GenSigSwitchedByIgnition" SG_ 817 MFL_Tip_rechts_Err 0;
BA_ "Fehlerwert" SG_ 817 MFL_Tip_rechts_Err 1;
BA_ "GenSigSendType" SG_ 817 MFL_Tip_Up 5;
BA_ "GenSigSendType" SG_ 817 MFL_Toggle 0;
BA_ "GenSigSwitchedByIgnition" SG_ 817 MFL_Toggle 0;
BA_ "GenSigSendType" SG_ 817 MFL_Touch_Event 0;
BA_ "GenSigSwitchedByIgnition" SG_ 817 MFL_Touch_Event 0;
BA_ "Fehlerwert" SG_ 817 MFL_Touch_Event 15;
BA_ "GenSigSendType" SG_ 817 MFL_Variante 0;
BA_ "GenSigFuncType" SG_ 817 MFL_Variante 8;
BA_ "GenSigSwitchedByIgnition" SG_ 817 MFL_Variante 0;
BA_ "GenSigSendType" SG_ 817 MFL_Zaehler 0;
BA_ "GenSigSwitchedByIgnition" SG_ 817 MFL_Zaehler 0;
BA_ "GenSigSendType" SG_ 329 MO_EP_01_BZ 0;
BA_ "GenSigFuncType" SG_ 329 MO_EP_01_BZ 1;
BA_ "GenSigSwitchedByIgnition" SG_ 329 MO_EP_01_BZ 0;
BA_ "GenSigSendType" SG_ 329 MO_EP_01_CRC 0;
BA_ "GenSigFuncType" SG_ 329 MO_EP_01_CRC 2;
BA_ "GenSigSwitchedByIgnition" SG_ 329 MO_EP_01_CRC 0;
BA_ "GenSigSendType" SG_ 329 MO_EP_Ist_Haltemagnet 0;
BA_ "GenSigSwitchedByIgnition" SG_ 329 MO_EP_Ist_Haltemagnet 0;
BA_ "Fehlerwert" SG_ 329 MO_EP_Ist_Haltemagnet 3;
BA_ "GenSigSendType" SG_ 329 MO_EP_Mute 0;
BA_ "GenSigSwitchedByIgnition" SG_ 329 MO_EP_Mute 0;
BA_ "GenSigSendType" SG_ 329 MO_EP_Vorgabe_Position 4;
BA_ "GenSigSwitchedByIgnition" SG_ 329 MO_EP_Vorgabe_Position 0;
BA_ "GenSigSendType" SG_ 15 MO_SOPC 5;
BA_ "GenSigSwitchedByIgnition" SG_ 15 MO_SOPC 0;
BA_ "GenSigSendType" SG_ 1600 MO_Absperrventil_oeffnen 0;
BA_ "GenSigSwitchedByIgnition" SG_ 1600 MO_Absperrventil_oeffnen 0;
BA_ "GenSigSendType" SG_ 1600 MO_aktives_Getriebeheizen 0;
BA_ "GenSigSwitchedByIgnition" SG_ 1600 MO_aktives_Getriebeheizen 0;
BA_ "GenSigSendType" SG_ 1600 MO_Ansaugluft_Temp 0;
BA_ "GenSigStartValue" SG_ 1600 MO_Ansaugluft_Temp 254;
BA_ "GenSigSwitchedByIgnition" SG_ 1600 MO_Ansaugluft_Temp 0;
BA_ "Fehlerwert" SG_ 1600 MO_Ansaugluft_Temp 255;
BA_ "GenSigSendType" SG_ 1600 MO_Getriebe_kuehlen 0;
BA_ "GenSigSwitchedByIgnition" SG_ 1600 MO_Getriebe_kuehlen 0;
BA_ "GenSigSendType" SG_ 1600 MO_Heizungspumpenansteuerung 0;
BA_ "GenSigStartValue" SG_ 1600 MO_Heizungspumpenansteuerung 14;
BA_ "GenSigSwitchedByIgnition" SG_ 1600 MO_Heizungspumpenansteuerung 0;
BA_ "Fehlerwert" SG_ 1600 MO_Heizungspumpenansteuerung 13;
BA_ "GenSigSendType" SG_ 1600 MO_Hoeheninfo 0;
BA_ "GenSigSwitchedByIgnition" SG_ 1600 MO_Hoeheninfo 0;
BA_ "Fehlerwert" SG_ 1600 MO_Hoeheninfo 255;
BA_ "GenSigSendType" SG_ 1600 MO_HYB_Fehler_HV_Netz 0;
BA_ "GenSigSwitchedByIgnition" SG_ 1600 MO_HYB_Fehler_HV_Netz 0;
BA_ "GenSigSendType" SG_ 1600 MO_Kennfeldk 0;
BA_ "GenSigSwitchedByIgnition" SG_ 1600 MO_Kennfeldk 0;
BA_ "GenSigSendType" SG_ 1600 MO_KL15_Abschaltempfehlung 0;
BA_ "GenSigSwitchedByIgnition" SG_ 1600 MO_KL15_Abschaltempfehlung 0;
BA_ "GenSigSendType" SG_ 1600 MO_Kuehlmittel_Temp 0;
BA_ "GenSigStartValue" SG_ 1600 MO_Kuehlmittel_Temp 254;
BA_ "GenSigSwitchedByIgnition" SG_ 1600 MO_Kuehlmittel_Temp 0;
BA_ "Fehlerwert" SG_ 1600 MO_Kuehlmittel_Temp 255;
BA_ "GenSigSendType" SG_ 1600 MO_Mom_Traegheit_02 0;
BA_ "GenSigSwitchedByIgnition" SG_ 1600 MO_Mom_Traegheit_02 0;
BA_ "GenSigSendType" SG_ 1600 MO_Nachlaufzeit_Heizungspumpe 0;
BA_ "GenSigSwitchedByIgnition" SG_ 1600 MO_Nachlaufzeit_Heizungspumpe 0;
BA_ "GenSigSendType" SG_ 1600 MO_Oel_Temp 0;
BA_ "GenSigStartValue" SG_ 1600 MO_Oel_Temp 254;
BA_ "GenSigSwitchedByIgnition" SG_ 1600 MO_Oel_Temp 0;
BA_ "Fehlerwert" SG_ 1600 MO_Oel_Temp 255;
BA_ "GenSigSendType" SG_ 1600 MO_QBit_Ansaugluft_Temp 0;
BA_ "GenSigStartValue" SG_ 1600 MO_QBit_Ansaugluft_Temp 1;
BA_ "GenSigSwitchedByIgnition" SG_ 1600 MO_QBit_Ansaugluft_Temp 0;
BA_ "GenSigSendType" SG_ 1600 MO_QBit_Hoeheninfo 0;
BA_ "GenSigStartValue" SG_ 1600 MO_QBit_Hoeheninfo 1;
BA_ "GenSigSwitchedByIgnition" SG_ 1600 MO_QBit_Hoeheninfo 0;
BA_ "GenSigSendType" SG_ 1600 MO_QBit_Kuehlmittel_Temp 0;
BA_ "GenSigStartValue" SG_ 1600 MO_QBit_Kuehlmittel_Temp 1;
BA_ "GenSigSwitchedByIgnition" SG_ 1600 MO_QBit_Kuehlmittel_Temp 0;
BA_ "GenSigSendType" SG_ 1600 MO_QBit_Oel_Temp 0;
BA_ "GenSigStartValue" SG_ 1600 MO_QBit_Oel_Temp 1;
BA_ "GenSigSwitchedByIgnition" SG_ 1600 MO_QBit_Oel_Temp 0;
BA_ "GenSigSendType" SG_ 1600 MO_SpannungsAnf 0;
BA_ "GenSigSwitchedByIgnition" SG_ 1600 MO_SpannungsAnf 0;
BA_ "GenSigSendType" SG_ 1600 MO_Versionsinfo_02 0;
BA_ "GenSigSwitchedByIgnition" SG_ 1600 MO_Versionsinfo_02 0;
BA_ "GenSigSendType" SG_ 1607 MO_CO2_Faktor 0;
BA_ "GenSigSwitchedByIgnition" SG_ 1607 MO_CO2_Faktor 0;
BA_ "Fehlerwert" SG_ 1607 MO_CO2_Faktor 4095;
BA_ "GenSigSendType" SG_ 1607 MO_E85_Sensor 0;
BA_ "GenSigStartValue" SG_ 1607 MO_E85_Sensor 14;
BA_ "GenSigSwitchedByIgnition" SG_ 1607 MO_E85_Sensor 0;
BA_ "Fehlerwert" SG_ 1607 MO_E85_Sensor 15;
BA_ "GenSigSendType" SG_ 1607 MO_Ethanol_Spuelhinweis 0;
BA_ "GenSigSwitchedByIgnition" SG_ 1607 MO_Ethanol_Spuelhinweis 0;
BA_ "GenSigSendType" SG_ 1607 MO_ITM_Kuehlmittel_Temp 0;
BA_ "GenSigStartValue" SG_ 1607 MO_ITM_Kuehlmittel_Temp 1;
BA_ "GenSigSwitchedByIgnition" SG_ 1607 MO_ITM_Kuehlmittel_Temp 0;
BA_ "Fehlerwert" SG_ 1607 MO_ITM_Kuehlmittel_Temp 2;
BA_ "GenSigSendType" SG_ 1607 MO_Kraftstofffilter_Wasser 0;
BA_ "GenSigSwitchedByIgnition" SG_ 1607 MO_Kraftstofffilter_Wasser 0;
BA_ "GenSigSwitchedByIgnition" SG_ 1607 MO_MKB_01 0;
BA_ "GenSigSwitchedByIgnition" SG_ 1607 MO_MKB_02 0;
BA_ "GenSigSwitchedByIgnition" SG_ 1607 MO_MKB_03 0;
BA_ "GenSigSwitchedByIgnition" SG_ 1607 MO_MKB_04 0;
BA_ "GenSigSendType" SG_ 1607 MO_MKB_MUX 0;
BA_ "GenSigSwitchedByIgnition" SG_ 1607 MO_MKB_MUX 0;
BA_ "GenSigSendType" SG_ 1607 SCR_Akustik 0;
BA_ "GenSigSwitchedByIgnition" SG_ 1607 SCR_Akustik 0;
BA_ "GenSigSendType" SG_ 1607 SCR_Anz_Motorstarts 0;
BA_ "GenSigStartValue" SG_ 1607 SCR_Anz_Motorstarts 15;
BA_ "GenSigSwitchedByIgnition" SG_ 1607 SCR_Anz_Motorstarts 0;
BA_ "GenSigSendType" SG_ 1607 SCR_Inducement_Strategie 0;
BA_ "GenSigSwitchedByIgnition" SG_ 1607 SCR_Inducement_Strategie 0;
BA_ "GenSigSendType" SG_ 1607 SCR_Reichweite 0;
BA_ "GenSigStartValue" SG_ 1607 SCR_Reichweite 32767;
BA_ "GenSigSwitchedByIgnition" SG_ 1607 SCR_Reichweite 0;
BA_ "GenSigSendType" SG_ 1607 SCR_Systemfehler 0;
BA_ "GenSigSwitchedByIgnition" SG_ 1607 SCR_Systemfehler 0;
BA_ "GenSigSendType" SG_ 1607 SCR_Text 0;
BA_ "GenSigSwitchedByIgnition" SG_ 1607 SCR_Text 0;
BA_ "GenSigSendType" SG_ 1607 SCR_verbaut 0;
BA_ "GenSigFuncType" SG_ 1607 SCR_verbaut 8;
BA_ "GenSigSwitchedByIgnition" SG_ 1607 SCR_verbaut 0;
BA_ "GenSigSendType" SG_ 1607 SCR_Warnstufe_1 0;
BA_ "GenSigSwitchedByIgnition" SG_ 1607 SCR_Warnstufe_1 0;
BA_ "GenSigSendType" SG_ 1607 SCR_Warnstufe_2 0;
BA_ "GenSigSwitchedByIgnition" SG_ 1607 SCR_Warnstufe_2 0;
BA_ "GenSigSendType" SG_ 958 MO_Aussp_Anlass 3;
BA_ "GenSigSwitchedByIgnition" SG_ 958 MO_Aussp_Anlass 0;
BA_ "GenSigSendType" SG_ 958 MO_BKV_Unterdruckwarnung 0;
BA_ "GenSigSwitchedByIgnition" SG_ 958 MO_BKV_Unterdruckwarnung 0;
BA_ "GenSigSendType" SG_ 958 MO_BLS 3;
BA_ "GenSigSwitchedByIgnition" SG_ 958 MO_BLS 0;
BA_ "GenSigSendType" SG_ 958 MO_BMS_NV_Anf_stuetzen 3;
BA_ "GenSigSwitchedByIgnition" SG_ 958 MO_BMS_NV_Anf_stuetzen 0;
BA_ "GenSigSendType" SG_ 958 MO_EKlKomLeiRed 0;
BA_ "GenSigSwitchedByIgnition" SG_ 958 MO_EKlKomLeiRed 0;
BA_ "GenSigSendType" SG_ 958 MO_Ext_E_Fahrt_aktiv 3;
BA_ "NWM-WakeupAllowed" SG_ 958 MO_Ext_E_Fahrt_aktiv 1;
BA_ "GenSigSwitchedByIgnition" SG_ 958 MO_Ext_E_Fahrt_aktiv 0;
BA_ "GenSigSendType" SG_ 958 MO_Fahrer_bremst 3;
BA_ "GenSigSwitchedByIgnition" SG_ 958 MO_Fahrer_bremst 0;
BA_ "GenSigSendType" SG_ 958 MO_FMAus_aktiv 3;
BA_ "GenSigSwitchedByIgnition" SG_ 958 MO_FMAus_aktiv 0;
BA_ "GenSigSendType" SG_ 958 MO_FMAus_Startvariante 3;
BA_ "GenSigSwitchedByIgnition" SG_ 958 MO_FMAus_Startvariante 0;
BA_ "GenSigSendType" SG_ 958 MO_Freig_Anlass 3;
BA_ "GenSigSwitchedByIgnition" SG_ 958 MO_Freig_Anlass 0;
BA_ "GenSigSendType" SG_ 958 MO_Freig_Reku 0;
BA_ "GenSigSwitchedByIgnition" SG_ 958 MO_Freig_Reku 0;
BA_ "GenSigSendType" SG_ 958 MO_Freigabe_Segeln 0;
BA_ "GenSigSwitchedByIgnition" SG_ 958 MO_Freigabe_Segeln 0;
BA_ "GenSigSendType" SG_ 958 MO_Gangposition 3;
BA_ "GenSigStartValue" SG_ 958 MO_Gangposition 14;
BA_ "GenSigSwitchedByIgnition" SG_ 958 MO_Gangposition 0;
BA_ "Fehlerwert" SG_ 958 MO_Gangposition 15;
BA_ "GenSigSendType" SG_ 958 MO_Handshake_STH 0;
BA_ "GenSigSwitchedByIgnition" SG_ 958 MO_Handshake_STH 0;
BA_ "GenSigSendType" SG_ 958 MO_HYB_Fahrbereitschaft 0;
BA_ "GenSigSwitchedByIgnition" SG_ 958 MO_HYB_Fahrbereitschaft 0;
BA_ "GenSigSendType" SG_ 958 MO_HYB_VM_aktiv 3;
BA_ "GenSigSwitchedByIgnition" SG_ 958 MO_HYB_VM_aktiv 0;
BA_ "GenSigSendType" SG_ 958 MO_Interlock 3;
BA_ "GenSigSwitchedByIgnition" SG_ 958 MO_Interlock 0;
BA_ "GenSigSendType" SG_ 958 MO_Kickdown 3;
BA_ "GenSigSwitchedByIgnition" SG_ 958 MO_Kickdown 0;
BA_ "GenSigSendType" SG_ 958 MO_Kl_50 3;
BA_ "GenSigSwitchedByIgnition" SG_ 958 MO_Kl_50 0;
BA_ "GenSigSendType" SG_ 958 MO_Kl_75 3;
BA_ "GenSigSwitchedByIgnition" SG_ 958 MO_Kl_75 0;
BA_ "GenSigSendType" SG_ 958 MO_Klima_Eingr 3;
BA_ "GenSigSwitchedByIgnition" SG_ 958 MO_Klima_Eingr 0;
BA_ "GenSigSendType" SG_ 958 MO_Konsistenz_Bremsped 3;
BA_ "GenSigSwitchedByIgnition" SG_ 958 MO_Konsistenz_Bremsped 0;
BA_ "GenSigSendType" SG_ 958 MO_Kuppl_schalter 3;
BA_ "GenSigSwitchedByIgnition" SG_ 958 MO_Kuppl_schalter 0;
BA_ "GenSigSendType" SG_ 958 MO_Motor_laeuft 3;
BA_ "GenSigSwitchedByIgnition" SG_ 958 MO_Motor_laeuft 0;
BA_ "GenSigSendType" SG_ 958 MO_PTC_Status 0;
BA_ "GenSigSwitchedByIgnition" SG_ 958 MO_PTC_Status 0;
BA_ "GenSigSendType" SG_ 958 MO_QBit_Fahrer_bremst 3;
BA_ "GenSigStartValue" SG_ 958 MO_QBit_Fahrer_bremst 1;
BA_ "GenSigSwitchedByIgnition" SG_ 958 MO_QBit_Fahrer_bremst 0;
BA_ "GenSigSendType" SG_ 958 MO_QBit_Gangposition 3;
BA_ "GenSigStartValue" SG_ 958 MO_QBit_Gangposition 1;
BA_ "GenSigSwitchedByIgnition" SG_ 958 MO_QBit_Gangposition 0;
BA_ "GenSigSendType" SG_ 958 MO_QBit_KL_75 3;
BA_ "GenSigStartValue" SG_ 958 MO_QBit_KL_75 1;
BA_ "GenSigSwitchedByIgnition" SG_ 958 MO_QBit_KL_75 0;
BA_ "GenSigSendType" SG_ 958 MO_Remotestart_Betrieb 3;
BA_ "GenSigSwitchedByIgnition" SG_ 958 MO_Remotestart_Betrieb 0;
BA_ "GenSigSendType" SG_ 958 MO_Remotestart_moeglich 0;
BA_ "GenSigSwitchedByIgnition" SG_ 958 MO_Remotestart_moeglich 0;
BA_ "GenSigSendType" SG_ 958 MO_Signalquelle_Gangposition 0;
BA_ "GenSigSwitchedByIgnition" SG_ 958 MO_Signalquelle_Gangposition 0;
BA_ "GenSigSendType" SG_ 958 MO_StartStopp_Fahrerwunsch 0;
BA_ "GenSigSwitchedByIgnition" SG_ 958 MO_StartStopp_Fahrerwunsch 0;
BA_ "GenSigSendType" SG_ 958 MO_StartStopp_Motorstopp 3;
BA_ "GenSigSwitchedByIgnition" SG_ 958 MO_StartStopp_Motorstopp 0;
BA_ "GenSigSendType" SG_ 958 MO_StartStopp_Status 0;
BA_ "GenSigSwitchedByIgnition" SG_ 958 MO_StartStopp_Status 0;
BA_ "GenSigSendType" SG_ 958 MO_StartStopp_Wiederstart 3;
BA_ "GenSigSwitchedByIgnition" SG_ 958 MO_StartStopp_Wiederstart 0;
BA_ "GenSigSendType" SG_ 958 MO_StartVorauss_erfuellt 3;
BA_ "GenSigStartValue" SG_ 958 MO_StartVorauss_erfuellt 1;
BA_ "GenSigSwitchedByIgnition" SG_ 958 MO_StartVorauss_erfuellt 0;
BA_ "GenSigSendType" SG_ 958 MO_Timeout_ESP 3;
BA_ "GenSigSwitchedByIgnition" SG_ 958 MO_Timeout_ESP 0;
BA_ "GenSigSendType" SG_ 958 MO_Zylinderabschaltung 3;
BA_ "GenSigSwitchedByIgnition" SG_ 958 MO_Zylinderabschaltung 0;
BA_ "GenSigSendType" SG_ 958 Motor_14_BZ 0;
BA_ "GenSigFuncType" SG_ 958 Motor_14_BZ 1;
BA_ "GenSigSwitchedByIgnition" SG_ 958 Motor_14_BZ 0;
BA_ "GenSigSendType" SG_ 958 Motor_14_CRC 0;
BA_ "GenSigFuncType" SG_ 958 Motor_14_CRC 2;
BA_ "GenSigSwitchedByIgnition" SG_ 958 Motor_14_CRC 0;
BA_ "GenSigSendType" SG_ 1631 MO_Anzeige_Kaltleuchte 0;
BA_ "GenSigSwitchedByIgnition" SG_ 1631 MO_Anzeige_Kaltleuchte 0;
BA_ "GenSigSendType" SG_ 1631 MO_DPF_reg 0;
BA_ "GenSigSwitchedByIgnition" SG_ 1631 MO_DPF_reg 0;
BA_ "GenSigSendType" SG_ 1631 MO_Energieinhalt_BMS 0;
BA_ "GenSigStartValue" SG_ 1631 MO_Energieinhalt_BMS 4094;
BA_ "GenSigSwitchedByIgnition" SG_ 1631 MO_Energieinhalt_BMS 0;
BA_ "Fehlerwert" SG_ 1631 MO_Energieinhalt_BMS 4095;
BA_ "GenSigSendType" SG_ 1631 MO_Heizstrom_EKAT 0;
BA_ "GenSigSwitchedByIgnition" SG_ 1631 MO_Heizstrom_EKAT 0;
BA_ "Fehlerwert" SG_ 1631 MO_Heizstrom_EKAT 127;
BA_ "GenSigSendType" SG_ 1631 MO_Heizstrom_SCR 0;
BA_ "GenSigSwitchedByIgnition" SG_ 1631 MO_Heizstrom_SCR 0;
BA_ "Fehlerwert" SG_ 1631 MO_Heizstrom_SCR 63;
BA_ "GenSigSendType" SG_ 1631 MO_P_Generator_ungefiltert_Anf 0;
BA_ "GenSigSwitchedByIgnition" SG_ 1631 MO_P_Generator_ungefiltert_Anf 0;
BA_ "GenSigSendType" SG_ 1631 MO_SpannungsAnf_02 0;
BA_ "GenSigSwitchedByIgnition" SG_ 1631 MO_SpannungsAnf_02 0;
BA_ "GenSigSendType" SG_ 1631 TSK_Fahrzeugmasse_02 0;
BA_ "GenSigSwitchedByIgnition" SG_ 1631 TSK_Fahrzeugmasse_02 0;
BA_ "Fehlerwert" SG_ 1631 TSK_Fahrzeugmasse_02 255;
BA_ "GenSigSendType" SG_ 1631 TSK_Grundmasse 0;
BA_ "GenSigSwitchedByIgnition" SG_ 1631 TSK_Grundmasse 0;
BA_ "GenSigSendType" SG_ 1631 TSK_QBit_Fahrzeugmasse 0;
BA_ "GenSigStartValue" SG_ 1631 TSK_QBit_Fahrzeugmasse 1;
BA_ "GenSigSwitchedByIgnition" SG_ 1631 TSK_QBit_Fahrzeugmasse 0;
BA_ "GenSigSendType" SG_ 1631 TSK_QBit_Steigung 0;
BA_ "GenSigStartValue" SG_ 1631 TSK_QBit_Steigung 1;
BA_ "GenSigSwitchedByIgnition" SG_ 1631 TSK_QBit_Steigung 0;
BA_ "GenSigSendType" SG_ 1631 TSK_Steigung_02 0;
BA_ "GenSigSwitchedByIgnition" SG_ 1631 TSK_Steigung_02 0;
BA_ "Fehlerwert" SG_ 1631 TSK_Steigung_02 255;
BA_ "GenSigSendType" SG_ 1648 MO1_Freigabe_Info_WFS 3;
BA_ "GenSigSwitchedByIgnition" SG_ 1648 MO1_Freigabe_Info_WFS 0;
BA_ "GenSigSendType" SG_ 1648 MO1_Freigabe_Verfallsinfo_WFS 3;
BA_ "GenSigSwitchedByIgnition" SG_ 1648 MO1_Freigabe_Verfallsinfo_WFS 0;
BA_ "GenSigSendType" SG_ 1648 MO1_Sperr_Info_WFS 3;
BA_ "GenSigSwitchedByIgnition" SG_ 1648 MO1_Sperr_Info_WFS 0;
BA_ "GenSigSendType" SG_ 1648 MO_Abstellzeit 0;
BA_ "GenSigStartValue" SG_ 1648 MO_Abstellzeit 254;
BA_ "GenSigSwitchedByIgnition" SG_ 1648 MO_Abstellzeit 0;
BA_ "GenSigSendType" SG_ 1648 MO_Abstellzeit_Status 0;
BA_ "GenSigSwitchedByIgnition" SG_ 1648 MO_Abstellzeit_Status 0;
BA_ "GenSigSendType" SG_ 1648 MO_ANC_Kennfeld_Anf 3;
BA_ "GenSigSwitchedByIgnition" SG_ 1648 MO_ANC_Kennfeld_Anf 0;
BA_ "GenSigSendType" SG_ 1648 MO_Anzahl_Abgesch_Zyl 3;
BA_ "GenSigSwitchedByIgnition" SG_ 1648 MO_Anzahl_Abgesch_Zyl 0;
BA_ "GenSigSendType" SG_ 1648 MO_Bremslicht_Reku 3;
BA_ "GenSigSwitchedByIgnition" SG_ 1648 MO_Bremslicht_Reku 0;
BA_ "GenSigSendType" SG_ 1648 MO_Drehzahl_Warnung 0;
BA_ "GenSigSwitchedByIgnition" SG_ 1648 MO_Drehzahl_Warnung 0;
BA_ "GenSigSendType" SG_ 1648 MO_EPCL 3;
BA_ "GenSigSwitchedByIgnition" SG_ 1648 MO_EPCL 0;
BA_ "GenSigSendType" SG_ 1648 MO_Ethanol_BS_Texte 0;
BA_ "GenSigSwitchedByIgnition" SG_ 1648 MO_Ethanol_BS_Texte 0;
BA_ "GenSigSendType" SG_ 1648 MO_Fahrzeugtyp 0;
BA_ "GenSigFuncType" SG_ 1648 MO_Fahrzeugtyp 8;
BA_ "GenSigSwitchedByIgnition" SG_ 1648 MO_Fahrzeugtyp 0;
BA_ "GenSigSendType" SG_ 1648 MO_Fehler_Zylabsch 0;
BA_ "GenSigSwitchedByIgnition" SG_ 1648 MO_Fehler_Zylabsch 0;
BA_ "GenSigSendType" SG_ 1648 MO_Hybrid_StartStopp_LED 3;
BA_ "GenSigSwitchedByIgnition" SG_ 1648 MO_Hybrid_StartStopp_LED 0;
BA_ "GenSigSendType" SG_ 1648 MO_max_Ladedruck 0;
BA_ "GenSigFuncType" SG_ 1648 MO_max_Ladedruck 8;
BA_ "GenSigSwitchedByIgnition" SG_ 1648 MO_max_Ladedruck 0;
BA_ "GenSigSendType" SG_ 1648 MO_NMAX_Schaltanzeige 3;
BA_ "GenSigSwitchedByIgnition" SG_ 1648 MO_NMAX_Schaltanzeige 0;
BA_ "GenSigSendType" SG_ 1648 MO_obere_Drehzahlgrenze 0;
BA_ "GenSigSwitchedByIgnition" SG_ 1648 MO_obere_Drehzahlgrenze 0;
BA_ "GenSigSendType" SG_ 1648 MO_StartStopp_PopUp 3;
BA_ "GenSigSwitchedByIgnition" SG_ 1648 MO_StartStopp_PopUp 0;
BA_ "GenSigSendType" SG_ 1648 MO_Zylabsch_Texte 0;
BA_ "GenSigSwitchedByIgnition" SG_ 1648 MO_Zylabsch_Texte 0;
BA_ "GenSigSendType" SG_ 1648 MO_Zylabsch_Texte_02 3;
BA_ "GenSigSwitchedByIgnition" SG_ 1648 MO_Zylabsch_Texte_02 0;
BA_ "GenSigSendType" SG_ 1654 MO_StaGluehk 3;
BA_ "GenSigSwitchedByIgnition" SG_ 1654 MO_StaGluehk 0;
BA_ "Fehlerwert" SG_ 1654 MO_StaGluehk 15;
BA_ "GenSigSendType" SG_ 1654 MO_Stoppverbot_Anz_01 3;
BA_ "GenSigSwitchedByIgnition" SG_ 1654 MO_Stoppverbot_Anz_01 0;
BA_ "GenSigSendType" SG_ 1654 MO_Stoppverbot_Anz_02 3;
BA_ "GenSigSwitchedByIgnition" SG_ 1654 MO_Stoppverbot_Anz_02 0;
BA_ "GenSigSendType" SG_ 1654 MO_Stoppverbot_Anz_03 3;
BA_ "GenSigSwitchedByIgnition" SG_ 1654 MO_Stoppverbot_Anz_03 0;
BA_ "GenSigSendType" SG_ 1654 MO_Stoppverbot_Anz_04 3;
BA_ "GenSigSwitchedByIgnition" SG_ 1654 MO_Stoppverbot_Anz_04 0;
BA_ "GenSigSendType" SG_ 1654 MO_Stoppverbot_Anz_05 3;
BA_ "GenSigSwitchedByIgnition" SG_ 1654 MO_Stoppverbot_Anz_05 0;
BA_ "GenSigSendType" SG_ 1654 MO_Stoppverbot_Anz_06 3;
BA_ "GenSigSwitchedByIgnition" SG_ 1654 MO_Stoppverbot_Anz_06 0;
BA_ "GenSigSendType" SG_ 1654 MO_Stoppverbot_Anz_07 3;
BA_ "GenSigSwitchedByIgnition" SG_ 1654 MO_Stoppverbot_Anz_07 0;
BA_ "GenSigSendType" SG_ 1654 MO_Stoppverbot_Anz_08 3;
BA_ "GenSigSwitchedByIgnition" SG_ 1654 MO_Stoppverbot_Anz_08 0;
BA_ "GenSigSendType" SG_ 1654 MO_Stoppverbot_Anz_09 3;
BA_ "GenSigSwitchedByIgnition" SG_ 1654 MO_Stoppverbot_Anz_09 0;
BA_ "GenSigSendType" SG_ 1654 MO_Stoppverbot_Anz_10 3;
BA_ "GenSigSwitchedByIgnition" SG_ 1654 MO_Stoppverbot_Anz_10 0;
BA_ "GenSigSendType" SG_ 1654 MO_Stoppverbot_Anz_11 3;
BA_ "GenSigSwitchedByIgnition" SG_ 1654 MO_Stoppverbot_Anz_11 0;
BA_ "GenSigSendType" SG_ 1654 MO_Stoppverbot_Anz_Std 3;
BA_ "GenSigSwitchedByIgnition" SG_ 1654 MO_Stoppverbot_Anz_Std 0;
BA_ "GenSigSendType" SG_ 1654 MO_Wiederstart_Anz_01 3;
BA_ "GenSigSwitchedByIgnition" SG_ 1654 MO_Wiederstart_Anz_01 0;
BA_ "GenSigSendType" SG_ 1654 MO_Wiederstart_Anz_02 3;
BA_ "GenSigSwitchedByIgnition" SG_ 1654 MO_Wiederstart_Anz_02 0;
BA_ "GenSigSendType" SG_ 1654 MO_Wiederstart_Anz_03 3;
BA_ "GenSigSwitchedByIgnition" SG_ 1654 MO_Wiederstart_Anz_03 0;
BA_ "GenSigSendType" SG_ 1654 MO_Wiederstart_Anz_Std 3;
BA_ "GenSigSwitchedByIgnition" SG_ 1654 MO_Wiederstart_Anz_Std 0;
BA_ "GenSigSendType" SG_ 1654 StSt_Koord_Status_Bremspedalkzpt 3;
BA_ "GenSigSwitchedByIgnition" SG_ 1654 StSt_Koord_Status_Bremspedalkzpt 0;
BA_ "GenSigSendType" SG_ 1654 StSt_Koord_Stoppverbot_Anz_01 3;
BA_ "GenSigSwitchedByIgnition" SG_ 1654 StSt_Koord_Stoppverbot_Anz_01 0;
BA_ "GenSigSendType" SG_ 1654 StSt_Koord_Stoppverbot_Anz_02 3;
BA_ "GenSigSwitchedByIgnition" SG_ 1654 StSt_Koord_Stoppverbot_Anz_02 0;
BA_ "GenSigSendType" SG_ 1654 StSt_Koord_Stoppverbot_Anz_03 3;
BA_ "GenSigSwitchedByIgnition" SG_ 1654 StSt_Koord_Stoppverbot_Anz_03 0;
BA_ "GenSigSendType" SG_ 1654 StSt_Koord_Stoppverbot_Anz_04 3;
BA_ "GenSigSwitchedByIgnition" SG_ 1654 StSt_Koord_Stoppverbot_Anz_04 0;
BA_ "GenSigSendType" SG_ 1654 StSt_Koord_Stoppverbot_Anz_05 3;
BA_ "GenSigSwitchedByIgnition" SG_ 1654 StSt_Koord_Stoppverbot_Anz_05 0;
BA_ "GenSigSendType" SG_ 1654 StSt_Koord_Stoppverbot_Anz_06 3;
BA_ "GenSigSwitchedByIgnition" SG_ 1654 StSt_Koord_Stoppverbot_Anz_06 0;
BA_ "GenSigSendType" SG_ 1654 StSt_Koord_Stoppverbot_Anz_07 3;
BA_ "GenSigSwitchedByIgnition" SG_ 1654 StSt_Koord_Stoppverbot_Anz_07 0;
BA_ "GenSigSendType" SG_ 1654 StSt_Koord_Stoppverbot_Anz_08 3;
BA_ "GenSigSwitchedByIgnition" SG_ 1654 StSt_Koord_Stoppverbot_Anz_08 0;
BA_ "GenSigSendType" SG_ 1654 StSt_Koord_Stoppverbot_Anz_09 3;
BA_ "GenSigSwitchedByIgnition" SG_ 1654 StSt_Koord_Stoppverbot_Anz_09 0;
BA_ "GenSigSendType" SG_ 1654 StSt_Koord_Stoppverbot_Anz_10 3;
BA_ "GenSigSwitchedByIgnition" SG_ 1654 StSt_Koord_Stoppverbot_Anz_10 0;
BA_ "GenSigSendType" SG_ 1654 StSt_Koord_Stoppverbot_Anz_11 3;
BA_ "GenSigSwitchedByIgnition" SG_ 1654 StSt_Koord_Stoppverbot_Anz_11 0;
BA_ "GenSigSendType" SG_ 1654 StSt_Koord_Stoppverbot_Anz_12 3;
BA_ "GenSigSwitchedByIgnition" SG_ 1654 StSt_Koord_Stoppverbot_Anz_12 0;
BA_ "GenSigSendType" SG_ 1654 StSt_Koord_Stoppverbot_Anz_13 3;
BA_ "GenSigSwitchedByIgnition" SG_ 1654 StSt_Koord_Stoppverbot_Anz_13 0;
BA_ "GenSigSendType" SG_ 1654 StSt_Koord_Stoppverbot_Anz_14 3;
BA_ "GenSigSwitchedByIgnition" SG_ 1654 StSt_Koord_Stoppverbot_Anz_14 0;
BA_ "GenSigSendType" SG_ 1654 StSt_Koord_Stoppverbot_Anz_15 3;
BA_ "GenSigSwitchedByIgnition" SG_ 1654 StSt_Koord_Stoppverbot_Anz_15 0;
BA_ "GenSigSendType" SG_ 1654 StSt_Koord_Stoppverbot_Anz_16 3;
BA_ "GenSigSwitchedByIgnition" SG_ 1654 StSt_Koord_Stoppverbot_Anz_16 0;
BA_ "GenSigSendType" SG_ 1654 StSt_Koord_Stoppverbot_Anz_17 3;
BA_ "GenSigSwitchedByIgnition" SG_ 1654 StSt_Koord_Stoppverbot_Anz_17 0;
BA_ "GenSigSendType" SG_ 1654 StSt_Koord_Stoppverbot_Anz_18 3;
BA_ "GenSigSwitchedByIgnition" SG_ 1654 StSt_Koord_Stoppverbot_Anz_18 0;
BA_ "GenSigSendType" SG_ 1654 StSt_Koord_Stoppverbot_Anz_19 3;
BA_ "GenSigSwitchedByIgnition" SG_ 1654 StSt_Koord_Stoppverbot_Anz_19 0;
BA_ "GenSigSendType" SG_ 1654 StSt_Koord_Stoppverbot_Anz_20 3;
BA_ "GenSigSwitchedByIgnition" SG_ 1654 StSt_Koord_Stoppverbot_Anz_20 0;
BA_ "GenSigSendType" SG_ 1654 StSt_Koord_Stoppverbot_Anz_21 3;
BA_ "GenSigSwitchedByIgnition" SG_ 1654 StSt_Koord_Stoppverbot_Anz_21 0;
BA_ "GenSigSendType" SG_ 1654 StSt_Koord_Stoppverbot_Anz_Std 3;
BA_ "GenSigSwitchedByIgnition" SG_ 1654 StSt_Koord_Stoppverbot_Anz_Std 0;
BA_ "GenSigSendType" SG_ 1654 StSt_Koord_Wiederstart_Anz_01 3;
BA_ "GenSigSwitchedByIgnition" SG_ 1654 StSt_Koord_Wiederstart_Anz_01 0;
BA_ "GenSigSendType" SG_ 1654 StSt_Koord_Wiederstart_Anz_02 3;
BA_ "GenSigSwitchedByIgnition" SG_ 1654 StSt_Koord_Wiederstart_Anz_02 0;
BA_ "GenSigSendType" SG_ 1654 StSt_Koord_Wiederstart_Anz_03 3;
BA_ "GenSigSwitchedByIgnition" SG_ 1654 StSt_Koord_Wiederstart_Anz_03 0;
BA_ "GenSigSendType" SG_ 1654 StSt_Koord_Wiederstart_Anz_04 3;
BA_ "GenSigSwitchedByIgnition" SG_ 1654 StSt_Koord_Wiederstart_Anz_04 0;
BA_ "GenSigSendType" SG_ 1654 StSt_Koord_Wiederstart_Anz_05 3;
BA_ "GenSigSwitchedByIgnition" SG_ 1654 StSt_Koord_Wiederstart_Anz_05 0;
BA_ "GenSigSendType" SG_ 1654 StSt_Koord_Wiederstart_Anz_06 3;
BA_ "GenSigSwitchedByIgnition" SG_ 1654 StSt_Koord_Wiederstart_Anz_06 0;
BA_ "GenSigSendType" SG_ 1654 StSt_Koord_Wiederstart_Anz_07 3;
BA_ "GenSigSwitchedByIgnition" SG_ 1654 StSt_Koord_Wiederstart_Anz_07 0;
BA_ "GenSigSendType" SG_ 1654 StSt_Koord_Wiederstart_Anz_08 3;
BA_ "GenSigSwitchedByIgnition" SG_ 1654 StSt_Koord_Wiederstart_Anz_08 0;
BA_ "GenSigSendType" SG_ 1654 StSt_Koord_Wiederstart_Anz_09 3;
BA_ "GenSigSwitchedByIgnition" SG_ 1654 StSt_Koord_Wiederstart_Anz_09 0;
BA_ "GenSigSendType" SG_ 1654 StSt_Koord_Wiederstart_Anz_10 3;
BA_ "GenSigSwitchedByIgnition" SG_ 1654 StSt_Koord_Wiederstart_Anz_10 0;
BA_ "GenSigSendType" SG_ 1654 StSt_Koord_Wiederstart_Anz_11 3;
BA_ "GenSigSwitchedByIgnition" SG_ 1654 StSt_Koord_Wiederstart_Anz_11 0;
BA_ "GenSigSendType" SG_ 1654 StSt_Koord_Wiederstart_Anz_Std 3;
BA_ "GenSigSwitchedByIgnition" SG_ 1654 StSt_Koord_Wiederstart_Anz_Std 0;
BA_ "GenSigSendType" SG_ 1391 MO_Anzeige_Aufheizfortschritt 0;
BA_ "GenSigStartValue" SG_ 1391 MO_Anzeige_Aufheizfortschritt 126;
BA_ "GenSigSwitchedByIgnition" SG_ 1391 MO_Anzeige_Aufheizfortschritt 0;
BA_ "Fehlerwert" SG_ 1391 MO_Anzeige_Aufheizfortschritt 127;
BA_ "GenSigSendType" SG_ 1391 MO_Anzeige_Drehmoment_Max 0;
BA_ "GenSigSwitchedByIgnition" SG_ 1391 MO_Anzeige_Drehmoment_Max 0;
BA_ "GenSigSendType" SG_ 1391 MO_Anzeige_Leistung_Max 0;
BA_ "GenSigSwitchedByIgnition" SG_ 1391 MO_Anzeige_Leistung_Max 0;
BA_ "GenSigSendType" SG_ 1391 MO_HYB_Drehzahl_VM 0;
BA_ "GenSigSwitchedByIgnition" SG_ 1391 MO_HYB_Drehzahl_VM 0;
BA_ "Fehlerwert" SG_ 1391 MO_HYB_Drehzahl_VM 65280;
BA_ "GenSigSendType" SG_ 1391 MO_IstLeistung_EKAT 0;
BA_ "GenSigStartValue" SG_ 1391 MO_IstLeistung_EKAT 126;
BA_ "GenSigSwitchedByIgnition" SG_ 1391 MO_IstLeistung_EKAT 0;
BA_ "Fehlerwert" SG_ 1391 MO_IstLeistung_EKAT 127;
BA_ "GenSigSendType" SG_ 967 MO_E_Mode 0;
BA_ "GenSigSwitchedByIgnition" SG_ 967 MO_E_Mode 0;
BA_ "GenSigSendType" SG_ 967 MO_E_Texte 0;
BA_ "GenSigSwitchedByIgnition" SG_ 967 MO_E_Texte 0;
BA_ "GenSigSendType" SG_ 967 MO_E_Warnungen 0;
BA_ "GenSigSwitchedByIgnition" SG_ 967 MO_E_Warnungen 0;
BA_ "GenSigSendType" SG_ 967 MO_EFLEX_Lampe 0;
BA_ "GenSigSwitchedByIgnition" SG_ 967 MO_EFLEX_Lampe 0;
BA_ "GenSigSendType" SG_ 967 MO_Heissleuchte 0;
BA_ "GenSigSwitchedByIgnition" SG_ 967 MO_Heissleuchte 0;
BA_ "GenSigSendType" SG_ 967 MO_ITM_Warnung_Pumpe 0;
BA_ "GenSigSwitchedByIgnition" SG_ 967 MO_ITM_Warnung_Pumpe 0;
BA_ "GenSigSendType" SG_ 967 MO_KJS_nicht_bereit 0;
BA_ "GenSigSwitchedByIgnition" SG_ 967 MO_KJS_nicht_bereit 0;
BA_ "Fehlerwert" SG_ 967 MO_KJS_nicht_bereit 1;
BA_ "GenSigStartValue" SG_ 967 MO_Kuehlerluefter_1 126;
BA_ "GenSigSwitchedByIgnition" SG_ 967 MO_Kuehlerluefter_1 0;
BA_ "Fehlerwert" SG_ 967 MO_Kuehlerluefter_1 127;
BA_ "GenSigStartValue" SG_ 967 MO_Kuehlerluefter_2 126;
BA_ "GenSigSwitchedByIgnition" SG_ 967 MO_Kuehlerluefter_2 0;
BA_ "Fehlerwert" SG_ 967 MO_Kuehlerluefter_2 127;
BA_ "GenSigSendType" SG_ 967 MO_Kuehlerluefter_MUX 0;
BA_ "GenSigSwitchedByIgnition" SG_ 967 MO_Kuehlerluefter_MUX 0;
BA_ "GenSigSendType" SG_ 967 MO_OBD2_Lampe 0;
BA_ "GenSigSwitchedByIgnition" SG_ 967 MO_OBD2_Lampe 0;
BA_ "GenSigSendType" SG_ 967 MO_Oelwarnung_max 0;
BA_ "GenSigSwitchedByIgnition" SG_ 967 MO_Oelwarnung_max 0;
BA_ "GenSigSendType" SG_ 967 MO_Partikel_Lampe 0;
BA_ "GenSigSwitchedByIgnition" SG_ 967 MO_Partikel_Lampe 0;
BA_ "GenSigSendType" SG_ 967 MO_RedFahrleistung_Lampe 0;
BA_ "GenSigSwitchedByIgnition" SG_ 967 MO_RedFahrleistung_Lampe 0;
BA_ "GenSigSendType" SG_ 967 MO_Systemlampe 0;
BA_ "GenSigSwitchedByIgnition" SG_ 967 MO_Systemlampe 0;
BA_ "GenSigSendType" SG_ 967 MO_Tankdeckel_Lampe 0;
BA_ "GenSigSwitchedByIgnition" SG_ 967 MO_Tankdeckel_Lampe 0;
BA_ "GenSigSendType" SG_ 967 MO_Text_Motorstart 0;
BA_ "GenSigSwitchedByIgnition" SG_ 967 MO_Text_Motorstart 0;
BA_ "GenSigSendType" SG_ 967 MO_Text_Partikelfil_Reg 0;
BA_ "GenSigSwitchedByIgnition" SG_ 967 MO_Text_Partikelfil_Reg 0;
BA_ "GenSigSendType" SG_ 967 MO_Text_Tankdeckelwarn 0;
BA_ "GenSigSwitchedByIgnition" SG_ 967 MO_Text_Tankdeckelwarn 0;
BA_ "GenSigSendType" SG_ 967 MO_Vorglueh_Lampe 0;
BA_ "GenSigSwitchedByIgnition" SG_ 967 MO_Vorglueh_Lampe 0;
BA_ "GenSigSendType" SG_ 967 MO_Zustand_HWP 0;
BA_ "GenSigStartValue" SG_ 967 MO_Zustand_HWP 1;
BA_ "GenSigSwitchedByIgnition" SG_ 967 MO_Zustand_HWP 0;
BA_ "GenSigSendType" SG_ 967 OLEV_Oelstand_nicht_vorhanden 0;
BA_ "GenSigSwitchedByIgnition" SG_ 967 OLEV_Oelstand_nicht_vorhanden 0;
BA_ "GenSigSendType" SG_ 967 OLEV_Systemstoerung 0;
BA_ "GenSigSwitchedByIgnition" SG_ 967 OLEV_Systemstoerung 0;
BA_ "GenSigSendType" SG_ 967 WIV_Anzeige_aktiv 0;
BA_ "GenSigSwitchedByIgnition" SG_ 967 WIV_Anzeige_aktiv 0;
BA_ "GenSigSendType" SG_ 967 WIV_laufender_Motor 0;
BA_ "GenSigSwitchedByIgnition" SG_ 967 WIV_laufender_Motor 0;
BA_ "GenSigSendType" SG_ 967 WIV_nachfuellanzeige_ein 0;
BA_ "GenSigSwitchedByIgnition" SG_ 967 WIV_nachfuellanzeige_ein 0;
BA_ "GenSigSendType" SG_ 967 WIV_nicht_betriebswarm 0;
BA_ "GenSigSwitchedByIgnition" SG_ 967 WIV_nicht_betriebswarm 0;
BA_ "GenSigSendType" SG_ 967 WIV_Oeldr_Warn_Motor 0;
BA_ "GenSigSwitchedByIgnition" SG_ 967 WIV_Oeldr_Warn_Motor 0;
BA_ "GenSigSendType" SG_ 967 WIV_Oeldyn_avl 0;
BA_ "GenSigSwitchedByIgnition" SG_ 967 WIV_Oeldyn_avl 0;
BA_ "GenSigSendType" SG_ 967 WIV_Oelmenge 0;
BA_ "GenSigSwitchedByIgnition" SG_ 967 WIV_Oelmenge 0;
BA_ "GenSigSendType" SG_ 967 WIV_Oelmin_Warn 0;
BA_ "GenSigSwitchedByIgnition" SG_ 967 WIV_Oelmin_Warn 0;
BA_ "GenSigSendType" SG_ 967 WIV_Oelstand 0;
BA_ "GenSigSwitchedByIgnition" SG_ 967 WIV_Oelstand 0;
BA_ "GenSigSendType" SG_ 967 WIV_Oelstand_nicht_vorhanden 0;
BA_ "GenSigSwitchedByIgnition" SG_ 967 WIV_Oelstand_nicht_vorhanden 0;
BA_ "GenSigSendType" SG_ 967 WIV_Oelsystem_aktiv 0;
BA_ "GenSigSwitchedByIgnition" SG_ 967 WIV_Oelsystem_aktiv 0;
BA_ "GenSigSendType" SG_ 967 WIV_Schieflage 0;
BA_ "GenSigSwitchedByIgnition" SG_ 967 WIV_Schieflage 0;
BA_ "GenSigSendType" SG_ 967 WIV_Sensorfehler 0;
BA_ "GenSigSwitchedByIgnition" SG_ 967 WIV_Sensorfehler 0;
BA_ "GenSigSendType" SG_ 967 WIV_Ueberfuell_deaktiv 0;
BA_ "GenSigSwitchedByIgnition" SG_ 967 WIV_Ueberfuell_deaktiv 0;
BA_ "GenSigSendType" SG_ 967 WIV_Ueberfuell_Warn 0;
BA_ "GenSigSwitchedByIgnition" SG_ 967 WIV_Ueberfuell_Warn 0;
BA_ "GenSigSendType" SG_ 967 WIV_Unterfuell_Warn 0;
BA_ "GenSigSwitchedByIgnition" SG_ 967 WIV_Unterfuell_Warn 0;
BA_ "GenSigSendType" SG_ 966 SOK_Motor_26_Signatur 0;
BA_ "GenSigFuncType" SG_ 966 SOK_Motor_26_Signatur 15;
BA_ "GenSigSwitchedByIgnition" SG_ 966 SOK_Motor_26_Signatur 0;
BA_ "GenSigSendType" SG_ 1366 MO_Fahrzeugabstellzeit 0;
BA_ "GenSigStartValue" SG_ 1366 MO_Fahrzeugabstellzeit 254;
BA_ "GenSigSwitchedByIgnition" SG_ 1366 MO_Fahrzeugabstellzeit 0;
BA_ "Fehlerwert" SG_ 1366 MO_Fahrzeugabstellzeit 255;
BA_ "GenSigSendType" SG_ 1366 MO_Fahrzeugabstellzeit_Status 0;
BA_ "GenSigSwitchedByIgnition" SG_ 1366 MO_Fahrzeugabstellzeit_Status 0;
BA_ "GenSigSendType" SG_ 1366 MO_HV_Auszeit 0;
BA_ "GenSigStartValue" SG_ 1366 MO_HV_Auszeit 510;
BA_ "GenSigSwitchedByIgnition" SG_ 1366 MO_HV_Auszeit 0;
BA_ "Fehlerwert" SG_ 1366 MO_HV_Auszeit 511;
BA_ "GenSigSendType" SG_ 1366 MO_HV_Auszeit_Status 0;
BA_ "GenSigSwitchedByIgnition" SG_ 1366 MO_HV_Auszeit_Status 0;
BA_ "GenSigSendType" SG_ 1366 MO_Verbau_StartSys_EM_HV 0;
BA_ "GenSigSwitchedByIgnition" SG_ 1366 MO_Verbau_StartSys_EM_HV 0;
BA_ "GenSigSendType" SG_ 1366 MO_Verbau_StartSys_EM_MV 0;
BA_ "GenSigSwitchedByIgnition" SG_ 1366 MO_Verbau_StartSys_EM_MV 0;
BA_ "GenSigSendType" SG_ 1366 MO_Verbau_StartSys_Q_Diode 0;
BA_ "GenSigSwitchedByIgnition" SG_ 1366 MO_Verbau_StartSys_Q_Diode 0;
BA_ "GenSigSendType" SG_ 1366 MO_Verbau_StartSys_Ritzelstarter 0;
BA_ "GenSigSwitchedByIgnition" SG_ 1366 MO_Verbau_StartSys_Ritzelstarter 0;
BA_ "GenSigSendType" SG_ 1366 MO_Verbau_StartSys_RSG_MV 0;
BA_ "GenSigSwitchedByIgnition" SG_ 1366 MO_Verbau_StartSys_RSG_MV 0;
BA_ "GenSigSendType" SG_ 1366 MO_Verbau_StartSys_RSG_NV 0;
BA_ "GenSigSwitchedByIgnition" SG_ 1366 MO_Verbau_StartSys_RSG_NV 0;
BA_ "GenSigSendType" SG_ 1366 MO_Ziel_SoC_Fremdladung 0;
BA_ "GenSigStartValue" SG_ 1366 MO_Ziel_SoC_Fremdladung 254;
BA_ "GenSigSwitchedByIgnition" SG_ 1366 MO_Ziel_SoC_Fremdladung 0;
BA_ "GenSigSendType" SG_ 2589283475 SCR_Einheit 0;
BA_ "GenSigSwitchedByIgnition" SG_ 2589283475 SCR_Einheit 0;
BA_ "GenSigSendType" SG_ 2589283475 SCR_Fuellstand 0;
BA_ "GenSigStartValue" SG_ 2589283475 SCR_Fuellstand 127;
BA_ "GenSigSwitchedByIgnition" SG_ 2589283475 SCR_Fuellstand 0;
BA_ "GenSigSendType" SG_ 2589283475 SCR_Nachfuellmenge_Einheit 0;
BA_ "GenSigSwitchedByIgnition" SG_ 2589283475 SCR_Nachfuellmenge_Einheit 0;
BA_ "GenSigSendType" SG_ 2589283475 SCR_Nachfuellmenge_max 0;
BA_ "GenSigStartValue" SG_ 2589283475 SCR_Nachfuellmenge_max 255;
BA_ "GenSigSwitchedByIgnition" SG_ 2589283475 SCR_Nachfuellmenge_max 0;
BA_ "GenSigSendType" SG_ 2589283475 SCR_Nachfuellmenge_min 0;
BA_ "GenSigStartValue" SG_ 2589283475 SCR_Nachfuellmenge_min 127;
BA_ "GenSigSwitchedByIgnition" SG_ 2589283475 SCR_Nachfuellmenge_min 0;
BA_ "GenSigSendType" SG_ 2589283475 SCR_Restreichweite 0;
BA_ "GenSigStartValue" SG_ 2589283475 SCR_Restreichweite 32767;
BA_ "GenSigSwitchedByIgnition" SG_ 2589283475 SCR_Restreichweite 0;
BA_ "GenSigSendType" SG_ 2589283475 SCR_Retriggersignal 0;
BA_ "GenSigSwitchedByIgnition" SG_ 2589283475 SCR_Retriggersignal 0;
BA_ "GenSigSendType" SG_ 2589283475 SCR_Tankvolumen 0;
BA_ "GenSigStartValue" SG_ 2589283475 SCR_Tankvolumen 63;
BA_ "GenSigSwitchedByIgnition" SG_ 2589283475 SCR_Tankvolumen 0;
BA_ "GenSigSendType" SG_ 2589283475 SCR_Zustand 0;
BA_ "GenSigSwitchedByIgnition" SG_ 2589283475 SCR_Zustand 0;
BA_ "GenSigSendType" SG_ 1367 AGK_Charisma_FahrPr 3;
BA_ "GenSigSwitchedByIgnition" SG_ 1367 AGK_Charisma_FahrPr 0;
BA_ "GenSigSendType" SG_ 1367 AGK_Charisma_Status 3;
BA_ "GenSigSwitchedByIgnition" SG_ 1367 AGK_Charisma_Status 0;
BA_ "GenSigSendType" SG_ 1367 MO_Bordnetz_Anf 3;
BA_ "GenSigSwitchedByIgnition" SG_ 1367 MO_Bordnetz_Anf 0;
BA_ "GenSigSendType" SG_ 1367 MO_El_Grundlast_Anf 3;
BA_ "GenSigSwitchedByIgnition" SG_ 1367 MO_El_Grundlast_Anf 0;
BA_ "GenSigSendType" SG_ 1367 Mo_Empf_Red_Genlast 3;
BA_ "GenSigSwitchedByIgnition" SG_ 1367 Mo_Empf_Red_Genlast 0;
BA_ "GenSigSendType" SG_ 1367 MO_FestSpannungsAnf 3;
BA_ "GenSigSwitchedByIgnition" SG_ 1367 MO_FestSpannungsAnf 0;
BA_ "GenSigSendType" SG_ 1367 MO_Freilauf_Charisma_FahrPr 3;
BA_ "GenSigSwitchedByIgnition" SG_ 1367 MO_Freilauf_Charisma_FahrPr 0;
BA_ "GenSigSendType" SG_ 1367 MO_Freilauf_Charisma_Status 3;
BA_ "GenSigSwitchedByIgnition" SG_ 1367 MO_Freilauf_Charisma_Status 0;
BA_ "GenSigSendType" SG_ 1367 MO_Kaltstartleistung_Anf 0;
BA_ "GenSigStartValue" SG_ 1367 MO_Kaltstartleistung_Anf 126;
BA_ "GenSigSwitchedByIgnition" SG_ 1367 MO_Kaltstartleistung_Anf 0;
BA_ "Fehlerwert" SG_ 1367 MO_Kaltstartleistung_Anf 127;
BA_ "GenSigSendType" SG_ 1367 MO_Kaltstarttemperatur 0;
BA_ "GenSigStartValue" SG_ 1367 MO_Kaltstarttemperatur 254;
BA_ "GenSigSwitchedByIgnition" SG_ 1367 MO_Kaltstarttemperatur 0;
BA_ "Fehlerwert" SG_ 1367 MO_Kaltstarttemperatur 255;
BA_ "GenSigSendType" SG_ 1367 MO_Lastabwurf 3;
BA_ "GenSigSwitchedByIgnition" SG_ 1367 MO_Lastabwurf 0;
BA_ "GenSigSendType" SG_ 1367 MO_Strecke_Reg_Anf 0;
BA_ "GenSigStartValue" SG_ 1367 MO_Strecke_Reg_Anf 63;
BA_ "GenSigSwitchedByIgnition" SG_ 1367 MO_Strecke_Reg_Anf 0;
BA_ "GenSigSendType" SG_ 706 MO_ADR_Status 3;
BA_ "GenSigSwitchedByIgnition" SG_ 706 MO_ADR_Status 0;
BA_ "GenSigSendType" SG_ 706 MO_AGA_Sound_Texte 3;
BA_ "GenSigSwitchedByIgnition" SG_ 706 MO_AGA_Sound_Texte 0;
BA_ "GenSigSendType" SG_ 706 MO_Anz_Kuehlerluefter 0;
BA_ "GenSigSwitchedByIgnition" SG_ 706 MO_Anz_Kuehlerluefter 0;
BA_ "GenSigSendType" SG_ 706 MO_Anzeige_FMAus_Text 3;
BA_ "GenSigSwitchedByIgnition" SG_ 706 MO_Anzeige_FMAus_Text 0;
BA_ "GenSigSendType" SG_ 706 MO_Anzeige_StSt_Symbol 3;
BA_ "GenSigSwitchedByIgnition" SG_ 706 MO_Anzeige_StSt_Symbol 0;
BA_ "GenSigSendType" SG_ 706 MO_Anzeige_StSt_Text 3;
BA_ "GenSigSwitchedByIgnition" SG_ 706 MO_Anzeige_StSt_Text 0;
BA_ "GenSigSendType" SG_ 706 MO_ElAntrieb_Abschleppwarnung 3;
BA_ "GenSigSwitchedByIgnition" SG_ 706 MO_ElAntrieb_Abschleppwarnung 0;
BA_ "GenSigSendType" SG_ 706 MO_EM_Ueberhitzungswarnung 3;
BA_ "GenSigSwitchedByIgnition" SG_ 706 MO_EM_Ueberhitzungswarnung 0;
BA_ "GenSigSendType" SG_ 706 MO_KEF_Status 0;
BA_ "GenSigSwitchedByIgnition" SG_ 706 MO_KEF_Status 0;
BA_ "GenSigSendType" SG_ 706 MO_Rekuperationsstufe 3;
BA_ "GenSigStartValue" SG_ 706 MO_Rekuperationsstufe 7;
BA_ "GenSigSwitchedByIgnition" SG_ 706 MO_Rekuperationsstufe 0;
BA_ "GenSigSendType" SG_ 706 MO_SREG_Beladung 0;
BA_ "GenSigStartValue" SG_ 706 MO_SREG_Beladung 62;
BA_ "GenSigSwitchedByIgnition" SG_ 706 MO_SREG_Beladung 0;
BA_ "Fehlerwert" SG_ 706 MO_SREG_Beladung 63;
BA_ "GenSigSendType" SG_ 706 MO_SREG_Status 3;
BA_ "GenSigSwitchedByIgnition" SG_ 706 MO_SREG_Status 0;
BA_ "GenSigSendType" SG_ 706 MO_VREG_Status 3;
BA_ "GenSigSwitchedByIgnition" SG_ 706 MO_VREG_Status 0;
BA_ "GenSigSendType" SG_ 706 PEA_Texte 3;
BA_ "GenSigSwitchedByIgnition" SG_ 706 PEA_Texte 0;
BA_ "GenSigSendType" SG_ 706 TSK_Einheit_vMax_FahrerInfo 0;
BA_ "GenSigSwitchedByIgnition" SG_ 706 TSK_Einheit_vMax_FahrerInfo 0;
BA_ "GenSigSendType" SG_ 706 TSK_Status_vMax_FahrerInfo 0;
BA_ "GenSigSwitchedByIgnition" SG_ 706 TSK_Status_vMax_FahrerInfo 0;
BA_ "GenSigSendType" SG_ 706 TSK_Ueberstimmt_vMax_FahrerInfo 3;
BA_ "GenSigSwitchedByIgnition" SG_ 706 TSK_Ueberstimmt_vMax_FahrerInfo 0;
BA_ "GenSigSendType" SG_ 706 TSK_vMax_FahrerInfo 0;
BA_ "GenSigSwitchedByIgnition" SG_ 706 TSK_vMax_FahrerInfo 0;
BA_ "GenSigSendType" SG_ 269 MO_Drehzahl_01 0;
BA_ "GenSigSwitchedByIgnition" SG_ 269 MO_Drehzahl_01 0;
BA_ "GenSigSendType" SG_ 269 MO_Drehzahl_VM 0;
BA_ "GenSigSwitchedByIgnition" SG_ 269 MO_Drehzahl_VM 0;
BA_ "GenSigSendType" SG_ 269 MO_EM1_SollDrehzahl 0;
BA_ "GenSigStartValue" SG_ 269 MO_EM1_SollDrehzahl 32767;
BA_ "GenSigSwitchedByIgnition" SG_ 269 MO_EM1_SollDrehzahl 0;
BA_ "GenSigSendType" SG_ 269 MO_EM2_SollDrehzahl 0;
BA_ "GenSigStartValue" SG_ 269 MO_EM2_SollDrehzahl 32767;
BA_ "GenSigSwitchedByIgnition" SG_ 269 MO_EM2_SollDrehzahl 0;
BA_ "GenSigSendType" SG_ 269 MO_erste_Ungenauschwelle 0;
BA_ "GenSigSwitchedByIgnition" SG_ 269 MO_erste_Ungenauschwelle 0;
BA_ "GenSigSendType" SG_ 269 MO_HYB_E_Faktor 0;
BA_ "GenSigSwitchedByIgnition" SG_ 269 MO_HYB_E_Faktor 0;
BA_ "GenSigSendType" SG_ 269 MO_HYB_EMode_Info 0;
BA_ "GenSigSwitchedByIgnition" SG_ 269 MO_HYB_EMode_Info 0;
BA_ "GenSigSendType" SG_ 269 MO_HYB_Freigabe_VM_Eingr 0;
BA_ "GenSigSwitchedByIgnition" SG_ 269 MO_HYB_Freigabe_VM_Eingr 0;
BA_ "GenSigSendType" SG_ 269 MO_HYB_Komfortstufe 0;
BA_ "GenSigSendType" SG_ 269 MO_HYB_LowSpeedModus 0;
BA_ "GenSigSwitchedByIgnition" SG_ 269 MO_HYB_LowSpeedModus 0;
BA_ "GenSigSendType" SG_ 269 MO_HYB_max_ind_VM_Mom_02 0;
BA_ "GenSigStartValue" SG_ 269 MO_HYB_max_ind_VM_Mom_02 254;
BA_ "GenSigSwitchedByIgnition" SG_ 269 MO_HYB_max_ind_VM_Mom_02 0;
BA_ "Fehlerwert" SG_ 269 MO_HYB_max_ind_VM_Mom_02 255;
BA_ "GenSigSendType" SG_ 269 MO_HYB_Modus_Ankopplung_VM 0;
BA_ "GenSigSwitchedByIgnition" SG_ 269 MO_HYB_Modus_Ankopplung_VM 0;
BA_ "GenSigSendType" SG_ 269 MO_HYB_Schaltverhinderung 0;
BA_ "GenSigSendType" SG_ 269 MO_HYB_Sollstatus_K0 0;
BA_ "GenSigSwitchedByIgnition" SG_ 269 MO_HYB_Sollstatus_K0 0;
BA_ "GenSigSendType" SG_ 269 MO_HYB_Stoppmodus 0;
BA_ "GenSigSendType" SG_ 269 MO_HYB_VM_bereit 0;
BA_ "GenSigSwitchedByIgnition" SG_ 269 MO_HYB_VM_bereit 0;
BA_ "GenSigSendType" SG_ 269 MO_HYB_VM_Mom_oE_02 0;
BA_ "GenSigStartValue" SG_ 269 MO_HYB_VM_Mom_oE_02 254;
BA_ "GenSigSwitchedByIgnition" SG_ 269 MO_HYB_VM_Mom_oE_02 0;
BA_ "Fehlerwert" SG_ 269 MO_HYB_VM_Mom_oE_02 255;
BA_ "GenSigSendType" SG_ 269 MO_HYB_Zielzustand 0;
BA_ "GenSigSwitchedByIgnition" SG_ 269 MO_HYB_Zielzustand 0;
BA_ "Fehlerwert" SG_ 269 MO_HYB_Zielzustand 7;
BA_ "GenSigSendType" SG_ 269 MO_Luftpfad_Verzugszeit_praed 0;
BA_ "GenSigSwitchedByIgnition" SG_ 269 MO_Luftpfad_Verzugszeit_praed 0;
BA_ "GenSigSendType" SG_ 269 MO_Mom_Begr_Fahr 0;
BA_ "GenSigStartValue" SG_ 269 MO_Mom_Begr_Fahr 510;
BA_ "GenSigSwitchedByIgnition" SG_ 269 MO_Mom_Begr_Fahr 0;
BA_ "Fehlerwert" SG_ 269 MO_Mom_Begr_Fahr 511;
BA_ "GenSigSendType" SG_ 269 MO_Mom_Begr_Schalt 0;
BA_ "GenSigStartValue" SG_ 269 MO_Mom_Begr_Schalt 1022;
BA_ "GenSigSwitchedByIgnition" SG_ 269 MO_Mom_Begr_Schalt 0;
BA_ "GenSigSendType" SG_ 269 MO_Mom_Ist_Summe 0;
BA_ "GenSigStartValue" SG_ 269 MO_Mom_Ist_Summe 1022;
BA_ "GenSigSwitchedByIgnition" SG_ 269 MO_Mom_Ist_Summe 0;
BA_ "GenSigSendType" SG_ 269 MO_Mom_neg_verfuegbar 0;
BA_ "GenSigStartValue" SG_ 269 MO_Mom_neg_verfuegbar 510;
BA_ "GenSigSwitchedByIgnition" SG_ 269 MO_Mom_neg_verfuegbar 0;
BA_ "Fehlerwert" SG_ 269 MO_Mom_neg_verfuegbar 511;
BA_ "GenSigSendType" SG_ 269 MO_Mom_Schub 0;
BA_ "GenSigStartValue" SG_ 269 MO_Mom_Schub 510;
BA_ "GenSigSwitchedByIgnition" SG_ 269 MO_Mom_Schub 0;
BA_ "GenSigSendType" SG_ 269 MO_Mom_Soll_gefiltert 0;
BA_ "GenSigStartValue" SG_ 269 MO_Mom_Soll_gefiltert 1022;
BA_ "GenSigSwitchedByIgnition" SG_ 269 MO_Mom_Soll_gefiltert 0;
BA_ "GenSigSendType" SG_ 269 MO_Mom_Soll_Roh 0;
BA_ "GenSigStartValue" SG_ 269 MO_Mom_Soll_Roh 1022;
BA_ "GenSigSwitchedByIgnition" SG_ 269 MO_Mom_Soll_Roh 0;
BA_ "GenSigSendType" SG_ 269 MO_Mom_Traegheit_Summe 0;
BA_ "GenSigStartValue" SG_ 269 MO_Mom_Traegheit_Summe 1022;
BA_ "GenSigSwitchedByIgnition" SG_ 269 MO_Mom_Traegheit_Summe 0;
BA_ "GenSigSendType" SG_ 269 MO_Momentenintegral_02 0;
BA_ "GenSigSwitchedByIgnition" SG_ 269 MO_Momentenintegral_02 0;
BA_ "GenSigSendType" SG_ 269 MO_QBit_Drehzahl_01 0;
BA_ "GenSigStartValue" SG_ 269 MO_QBit_Drehzahl_01 1;
BA_ "GenSigSwitchedByIgnition" SG_ 269 MO_QBit_Drehzahl_01 0;
BA_ "GenSigSendType" SG_ 269 MO_QBit_Motormomente 0;
BA_ "GenSigStartValue" SG_ 269 MO_QBit_Motormomente 1;
BA_ "GenSigSwitchedByIgnition" SG_ 269 MO_QBit_Motormomente 0;
BA_ "GenSigSendType" SG_ 269 MO_Status_Normalbetrieb_01 0;
BA_ "GenSigSwitchedByIgnition" SG_ 269 MO_Status_Normalbetrieb_01 0;
BA_ "GenSigSendType" SG_ 269 MO_TNW_Max_Strom_Lim 0;
BA_ "GenSigStartValue" SG_ 269 MO_TNW_Max_Strom_Lim 8190;
BA_ "GenSigSwitchedByIgnition" SG_ 269 MO_TNW_Max_Strom_Lim 0;
BA_ "GenSigSendType" SG_ 269 MO_TNW_Min_Strom_Lim 0;
BA_ "GenSigStartValue" SG_ 269 MO_TNW_Min_Strom_Lim 8190;
BA_ "GenSigSwitchedByIgnition" SG_ 269 MO_TNW_Min_Strom_Lim 0;
BA_ "GenSigSendType" SG_ 269 Motor_50_BZ 0;
BA_ "GenSigFuncType" SG_ 269 Motor_50_BZ 1;
BA_ "GenSigSwitchedByIgnition" SG_ 269 Motor_50_BZ 0;
BA_ "GenSigSendType" SG_ 269 Motor_50_CRC 0;
BA_ "GenSigFuncType" SG_ 269 Motor_50_CRC 2;
BA_ "GenSigSwitchedByIgnition" SG_ 269 Motor_50_CRC 0;
BA_REL_ "GenSigTimeoutTime" BU_SG_REL_ Gateway_Max SG_ 1600 MO_Kuehlmittel_Temp 5000;
BA_REL_ "GenSigTimeoutTime" BU_SG_REL_ Gateway_Max SG_ 958 MO_StartStopp_Status 1000;
BA_REL_ "GenSigTimeoutTime" BU_SG_REL_ Gateway_Max SG_ 958 MO_StartStopp_Wiederstart 1000;
BA_REL_ "GenSigTimeoutTime" BU_SG_REL_ Gateway_Max SG_ 958 MO_StartStopp_Motorstopp 1000;
BA_REL_ "GenSigTimeoutTime" BU_SG_REL_ Gateway_Max SG_ 958 MO_Freig_Reku 1000;
BA_REL_ "GenSigTimeoutTime" BU_SG_REL_ Gateway_Max SG_ 958 MO_Kl_75 1000;
BA_REL_ "GenSigTimeoutTime" BU_SG_REL_ Gateway_Max SG_ 958 MO_Kl_50 1000;
BA_REL_ "GenSigTimeoutTime" BU_SG_REL_ Gateway_Max SG_ 958 MO_Gangposition 1000;
BA_REL_ "GenSigTimeoutTime" BU_SG_REL_ Gateway_Max SG_ 958 MO_StartStopp_Fahrerwunsch 1000;
BA_REL_ "GenSigTimeoutTime" BU_SG_REL_ Gateway_Max SG_ 958 MO_HYB_Fahrbereitschaft 1000;
BA_REL_ "GenSigTimeoutTime" BU_SG_REL_ Gateway_Max SG_ 958 MO_Fahrer_bremst 1000;
BA_REL_ "GenSigTimeoutTime" BU_SG_REL_ Gateway_Max SG_ 958 MO_BLS 1000;
BA_REL_ "GenSigTimeoutTime" BU_SG_REL_ Gateway_Max SG_ 958 MO_Motor_laeuft 1000;
BA_REL_ "GenSigTimeoutTime" BU_SG_REL_ Gateway_Max SG_ 958 MO_Kickdown 1000;
BA_REL_ "GenSigTimeoutTime" BU_SG_REL_ Gateway_Max SG_ 1631 TSK_QBit_Fahrzeugmasse 5000;
BA_REL_ "GenSigTimeoutTime" BU_SG_REL_ Gateway_Max SG_ 1631 MO_SpannungsAnf_02 5000;
BA_REL_ "GenSigTimeoutTime" BU_SG_REL_ Gateway_Max SG_ 1631 MO_Energieinhalt_BMS 5000;
BA_REL_ "GenSigTimeoutTime" BU_SG_REL_ Gateway_Max SG_ 1631 TSK_Fahrzeugmasse_02 5000;
BA_REL_ "GenSigTimeoutTime" BU_SG_REL_ Gateway_Max SG_ 1648 MO_Fahrzeugtyp 5000;
BA_REL_ "GenSigTimeoutTime" BU_SG_REL_ Gateway_Max SG_ 1648 MO_Hybrid_StartStopp_LED 5000;
BA_REL_ "GenSigTimeoutTime" BU_SG_REL_ Gateway_Max SG_ 1654 StSt_Koord_Wiederstart_Anz_09 5000;
BA_REL_ "GenSigTimeoutTime" BU_SG_REL_ Gateway_Max SG_ 1654 StSt_Koord_Wiederstart_Anz_10 5000;
BA_REL_ "GenSigTimeoutTime" BU_SG_REL_ Gateway_Max SG_ 1654 StSt_Koord_Wiederstart_Anz_11 5000;
BA_REL_ "GenSigTimeoutTime" BU_SG_REL_ Gateway_Max SG_ 1654 MO_Wiederstart_Anz_01 5000;
BA_REL_ "GenSigTimeoutTime" BU_SG_REL_ Gateway_Max SG_ 1654 MO_Wiederstart_Anz_02 5000;
BA_REL_ "GenSigTimeoutTime" BU_SG_REL_ Gateway_Max SG_ 1654 MO_Wiederstart_Anz_03 5000;
BA_REL_ "GenSigTimeoutTime" BU_SG_REL_ Gateway_Max SG_ 1654 MO_Wiederstart_Anz_Std 5000;
BA_REL_ "GenSigTimeoutTime" BU_SG_REL_ Gateway_Max SG_ 1654 MO_Stoppverbot_Anz_01 5000;
BA_REL_ "GenSigTimeoutTime" BU_SG_REL_ Gateway_Max SG_ 1654 MO_Stoppverbot_Anz_02 5000;
BA_REL_ "GenSigTimeoutTime" BU_SG_REL_ Gateway_Max SG_ 1654 MO_Stoppverbot_Anz_03 5000;
BA_REL_ "GenSigTimeoutTime" BU_SG_REL_ Gateway_Max SG_ 1654 MO_Stoppverbot_Anz_04 5000;
BA_REL_ "GenSigTimeoutTime" BU_SG_REL_ Gateway_Max SG_ 1654 MO_Stoppverbot_Anz_05 5000;
BA_REL_ "GenSigTimeoutTime" BU_SG_REL_ Gateway_Max SG_ 1654 MO_Stoppverbot_Anz_06 5000;
BA_REL_ "GenSigTimeoutTime" BU_SG_REL_ Gateway_Max SG_ 1654 MO_Stoppverbot_Anz_07 5000;
BA_REL_ "GenSigTimeoutTime" BU_SG_REL_ Gateway_Max SG_ 1654 MO_Stoppverbot_Anz_08 5000;
BA_REL_ "GenSigTimeoutTime" BU_SG_REL_ Gateway_Max SG_ 1654 MO_Stoppverbot_Anz_09 5000;
BA_REL_ "GenSigTimeoutTime" BU_SG_REL_ Gateway_Max SG_ 1654 MO_Stoppverbot_Anz_10 5000;
BA_REL_ "GenSigTimeoutTime" BU_SG_REL_ Gateway_Max SG_ 1654 MO_Stoppverbot_Anz_11 5000;
BA_REL_ "GenSigTimeoutTime" BU_SG_REL_ Gateway_Max SG_ 1654 MO_Stoppverbot_Anz_Std 5000;
BA_REL_ "GenSigTimeoutTime" BU_SG_REL_ Gateway_Max SG_ 1654 StSt_Koord_Stoppverbot_Anz_20 5000;
BA_REL_ "GenSigTimeoutTime" BU_SG_REL_ Gateway_Max SG_ 1654 StSt_Koord_Stoppverbot_Anz_21 5000;
BA_REL_ "GenSigTimeoutTime" BU_SG_REL_ Gateway_Max SG_ 1654 StSt_Koord_Wiederstart_Anz_Std 5000;
BA_REL_ "GenSigTimeoutTime" BU_SG_REL_ Gateway_Max SG_ 1654 StSt_Koord_Status_Bremspedalkzpt 5000;
BA_REL_ "GenSigTimeoutTime" BU_SG_REL_ Gateway_Max SG_ 1654 StSt_Koord_Wiederstart_Anz_01 5000;
BA_REL_ "GenSigTimeoutTime" BU_SG_REL_ Gateway_Max SG_ 1654 StSt_Koord_Wiederstart_Anz_02 5000;
BA_REL_ "GenSigTimeoutTime" BU_SG_REL_ Gateway_Max SG_ 1654 StSt_Koord_Wiederstart_Anz_03 5000;
BA_REL_ "GenSigTimeoutTime" BU_SG_REL_ Gateway_Max SG_ 1654 StSt_Koord_Wiederstart_Anz_04 5000;
BA_REL_ "GenSigTimeoutTime" BU_SG_REL_ Gateway_Max SG_ 1654 StSt_Koord_Wiederstart_Anz_05 5000;
BA_REL_ "GenSigTimeoutTime" BU_SG_REL_ Gateway_Max SG_ 1654 StSt_Koord_Wiederstart_Anz_06 5000;
BA_REL_ "GenSigTimeoutTime" BU_SG_REL_ Gateway_Max SG_ 1654 StSt_Koord_Wiederstart_Anz_07 5000;
BA_REL_ "GenSigTimeoutTime" BU_SG_REL_ Gateway_Max SG_ 1654 StSt_Koord_Wiederstart_Anz_08 5000;
BA_REL_ "GenSigTimeoutTime" BU_SG_REL_ Gateway_Max SG_ 1654 StSt_Koord_Stoppverbot_Anz_01 5000;
BA_REL_ "GenSigTimeoutTime" BU_SG_REL_ Gateway_Max SG_ 1654 StSt_Koord_Stoppverbot_Anz_02 5000;
BA_REL_ "GenSigTimeoutTime" BU_SG_REL_ Gateway_Max SG_ 1654 StSt_Koord_Stoppverbot_Anz_03 5000;
BA_REL_ "GenSigTimeoutTime" BU_SG_REL_ Gateway_Max SG_ 1654 StSt_Koord_Stoppverbot_Anz_04 5000;
BA_REL_ "GenSigTimeoutTime" BU_SG_REL_ Gateway_Max SG_ 1654 StSt_Koord_Stoppverbot_Anz_05 5000;
BA_REL_ "GenSigTimeoutTime" BU_SG_REL_ Gateway_Max SG_ 1654 StSt_Koord_Stoppverbot_Anz_06 5000;
BA_REL_ "GenSigTimeoutTime" BU_SG_REL_ Gateway_Max SG_ 1654 StSt_Koord_Stoppverbot_Anz_07 5000;
BA_REL_ "GenSigTimeoutTime" BU_SG_REL_ Gateway_Max SG_ 1654 StSt_Koord_Stoppverbot_Anz_08 5000;
BA_REL_ "GenSigTimeoutTime" BU_SG_REL_ Gateway_Max SG_ 1654 StSt_Koord_Stoppverbot_Anz_09 5000;
BA_REL_ "GenSigTimeoutTime" BU_SG_REL_ Gateway_Max SG_ 1654 StSt_Koord_Stoppverbot_Anz_10 5000;
BA_REL_ "GenSigTimeoutTime" BU_SG_REL_ Gateway_Max SG_ 1654 StSt_Koord_Stoppverbot_Anz_11 5000;
BA_REL_ "GenSigTimeoutTime" BU_SG_REL_ Gateway_Max SG_ 1654 StSt_Koord_Stoppverbot_Anz_12 5000;
BA_REL_ "GenSigTimeoutTime" BU_SG_REL_ Gateway_Max SG_ 1654 StSt_Koord_Stoppverbot_Anz_13 5000;
BA_REL_ "GenSigTimeoutTime" BU_SG_REL_ Gateway_Max SG_ 1654 StSt_Koord_Stoppverbot_Anz_14 5000;
BA_REL_ "GenSigTimeoutTime" BU_SG_REL_ Gateway_Max SG_ 1654 StSt_Koord_Stoppverbot_Anz_15 5000;
BA_REL_ "GenSigTimeoutTime" BU_SG_REL_ Gateway_Max SG_ 1654 StSt_Koord_Stoppverbot_Anz_16 5000;
BA_REL_ "GenSigTimeoutTime" BU_SG_REL_ Gateway_Max SG_ 1654 StSt_Koord_Stoppverbot_Anz_17 5000;
BA_REL_ "GenSigTimeoutTime" BU_SG_REL_ Gateway_Max SG_ 1654 StSt_Koord_Stoppverbot_Anz_Std 5000;
BA_REL_ "GenSigTimeoutTime" BU_SG_REL_ Gateway_Max SG_ 1654 StSt_Koord_Stoppverbot_Anz_18 5000;
BA_REL_ "GenSigTimeoutTime" BU_SG_REL_ Gateway_Max SG_ 1654 StSt_Koord_Stoppverbot_Anz_19 5000;
BA_REL_ "GenSigTimeoutTime" BU_SG_REL_ Gateway_Max SG_ 967 MO_E_Warnungen 1000;
BA_REL_ "GenSigTimeoutTime" BU_SG_REL_ Gateway_Max SG_ 967 MO_Text_Motorstart 1000;
BA_REL_ "GenSigTimeoutTime" BU_SG_REL_ Gateway_Max SG_ 1366 MO_Fahrzeugabstellzeit_Status 5000;
BA_REL_ "GenSigTimeoutTime" BU_SG_REL_ Gateway_Max SG_ 1366 MO_HV_Auszeit_Status 5000;
BA_REL_ "GenSigTimeoutTime" BU_SG_REL_ Gateway_Max SG_ 1366 MO_Fahrzeugabstellzeit 5000;
BA_REL_ "GenSigTimeoutTime" BU_SG_REL_ Gateway_Max SG_ 1366 MO_HV_Auszeit 5000;
BA_REL_ "GenSigTimeoutTime" BU_SG_REL_ Gateway_Max SG_ 1366 MO_Verbau_StartSys_Ritzelstarter 5000;
BA_REL_ "GenSigTimeoutTime" BU_SG_REL_ Gateway_Max SG_ 1366 MO_Ziel_SoC_Fremdladung 5000;
BA_REL_ "GenSigTimeoutTime" BU_SG_REL_ Gateway_Max SG_ 1367 Mo_Empf_Red_Genlast 5000;
BA_REL_ "GenSigTimeoutTime" BU_SG_REL_ Gateway_Max SG_ 1367 MO_Bordnetz_Anf 5000;
BA_REL_ "GenSigTimeoutTime" BU_SG_REL_ Gateway_Max SG_ 1367 MO_Strecke_Reg_Anf 5000;
BA_REL_ "GenSigTimeoutTime" BU_SG_REL_ Gateway_Max SG_ 1367 MO_FestSpannungsAnf 5000;
BA_REL_ "GenSigTimeoutTime" BU_SG_REL_ Gateway_Max SG_ 1367 MO_El_Grundlast_Anf 5000;
BA_REL_ "GenSigTimeoutTime" BU_SG_REL_ Gateway_Max SG_ 1367 MO_Lastabwurf 5000;
BA_REL_ "GenSigTimeoutTime" BU_SG_REL_ Gateway_Max SG_ 706 MO_Anzeige_StSt_Symbol 5000;
BA_REL_ "GenSigTimeoutTime" BU_SG_REL_ Gateway_Max SG_ 269 MO_QBit_Drehzahl_01 500;
BA_REL_ "GenSigTimeoutTime" BU_SG_REL_ Gateway_Max SG_ 269 MO_Drehzahl_01 500;
BA_REL_ "GenSigTimeoutTime" BU_SG_REL_ Gateway_Max SG_ 269 MO_Drehzahl_VM 500;
BA_REL_ "GenSigTimeoutTime" BU_SG_REL_ Getriebe_DQ SG_ 817 MFL_Tip_Down 5000;
BA_REL_ "GenSigTimeoutTime" BU_SG_REL_ Getriebe_DQ SG_ 817 MFL_Tip_Up 5000;
BA_REL_ "GenSigTimeoutTime" BU_SG_REL_ Getriebe_DQ SG_ 817 MFL_Tip_links_Err 5000;
BA_REL_ "GenSigTimeoutTime" BU_SG_REL_ Getriebe_DQ SG_ 817 MFL_Tip_rechts_Err 5000;
BA_REL_ "GenSigTimeoutTime" BU_SG_REL_ Getriebe_DQ SG_ 1600 MO_QBit_Ansaugluft_Temp 5000;
BA_REL_ "GenSigTimeoutTime" BU_SG_REL_ Getriebe_DQ SG_ 1600 MO_QBit_Oel_Temp 5000;
BA_REL_ "GenSigTimeoutTime" BU_SG_REL_ Getriebe_DQ SG_ 1600 MO_QBit_Kuehlmittel_Temp 5000;
BA_REL_ "GenSigTimeoutTime" BU_SG_REL_ Getriebe_DQ SG_ 1600 MO_Absperrventil_oeffnen 5000;
BA_REL_ "GenSigTimeoutTime" BU_SG_REL_ Getriebe_DQ SG_ 1600 MO_Ansaugluft_Temp 5000;
BA_REL_ "GenSigTimeoutTime" BU_SG_REL_ Getriebe_DQ SG_ 1600 MO_Oel_Temp 5000;
BA_REL_ "GenSigTimeoutTime" BU_SG_REL_ Getriebe_DQ SG_ 1600 MO_Kuehlmittel_Temp 5000;
BA_REL_ "GenSigTimeoutTime" BU_SG_REL_ Getriebe_DQ SG_ 1600 MO_Hoeheninfo 5000;
BA_REL_ "GenSigTimeoutTime" BU_SG_REL_ Getriebe_DQ SG_ 1600 MO_Getriebe_kuehlen 5000;
BA_REL_ "GenSigTimeoutTime" BU_SG_REL_ Getriebe_DQ SG_ 958 MO_StartStopp_Status 1000;
BA_REL_ "GenSigTimeoutTime" BU_SG_REL_ Getriebe_DQ SG_ 958 MO_StartStopp_Wiederstart 1000;
BA_REL_ "GenSigTimeoutTime" BU_SG_REL_ Getriebe_DQ SG_ 958 MO_StartStopp_Motorstopp 1000;
BA_REL_ "GenSigTimeoutTime" BU_SG_REL_ Getriebe_DQ SG_ 958 MO_Kl_50 1000;
BA_REL_ "GenSigTimeoutTime" BU_SG_REL_ Getriebe_DQ SG_ 958 MO_StartStopp_Fahrerwunsch 1000;
BA_REL_ "GenSigTimeoutTime" BU_SG_REL_ Getriebe_DQ SG_ 958 MO_Fahrer_bremst 1000;
BA_REL_ "GenSigTimeoutTime" BU_SG_REL_ Getriebe_DQ SG_ 958 MO_QBit_Fahrer_bremst 1000;
BA_REL_ "GenSigTimeoutTime" BU_SG_REL_ Getriebe_DQ SG_ 958 MO_BLS 1000;
BA_REL_ "GenSigTimeoutTime" BU_SG_REL_ Getriebe_DQ SG_ 958 MO_Kickdown 1000;
BA_REL_ "GenSigTimeoutTime" BU_SG_REL_ Getriebe_DQ SG_ 958 MO_Freigabe_Segeln 1000;
BA_REL_ "GenSigTimeoutTime" BU_SG_REL_ Getriebe_DQ SG_ 958 MO_FMAus_aktiv 1000;
BA_REL_ "GenSigTimeoutTime" BU_SG_REL_ Getriebe_DQ SG_ 958 MO_FMAus_Startvariante 1000;
BA_REL_ "GenSigTimeoutTime" BU_SG_REL_ Getriebe_DQ SG_ 958 MO_Zylinderabschaltung 1000;
BA_REL_ "GenSigTimeoutTime" BU_SG_REL_ Getriebe_DQ SG_ 967 MO_Kuehlerluefter_MUX 1000;
BA_REL_ "GenSigTimeoutTime" BU_SG_REL_ Getriebe_DQ SG_ 967 MO_Kuehlerluefter_1 1000;
BA_REL_ "GenSigTimeoutTime" BU_SG_REL_ Getriebe_DQ SG_ 967 MO_Kuehlerluefter_2 1000;
BA_REL_ "GenSigTimeoutTime" BU_SG_REL_ Getriebe_DQ SG_ 269 Motor_50_CRC 500;
BA_REL_ "GenSigTimeoutTime" BU_SG_REL_ Getriebe_DQ SG_ 269 Motor_50_BZ 500;
BA_REL_ "GenSigTimeoutTime" BU_SG_REL_ Getriebe_DQ SG_ 269 MO_Mom_Soll_Roh 500;
BA_REL_ "GenSigTimeoutTime" BU_SG_REL_ Getriebe_DQ SG_ 269 MO_Mom_Ist_Summe 500;
BA_REL_ "GenSigTimeoutTime" BU_SG_REL_ Getriebe_DQ SG_ 269 MO_Mom_Soll_gefiltert 500;
BA_REL_ "GenSigTimeoutTime" BU_SG_REL_ Getriebe_DQ SG_ 269 MO_Mom_Schub 500;
BA_REL_ "GenSigTimeoutTime" BU_SG_REL_ Getriebe_DQ SG_ 269 MO_Status_Normalbetrieb_01 500;
BA_REL_ "GenSigTimeoutTime" BU_SG_REL_ Getriebe_DQ SG_ 269 MO_QBit_Motormomente 500;
BA_REL_ "GenSigTimeoutTime" BU_SG_REL_ Getriebe_DQ SG_ 269 MO_Mom_neg_verfuegbar 500;
BA_REL_ "GenSigTimeoutTime" BU_SG_REL_ Getriebe_DQ SG_ 269 MO_Mom_Begr_Fahr 500;
BA_REL_ "GenSigTimeoutTime" BU_SG_REL_ Getriebe_DQ SG_ 269 MO_Mom_Begr_Schalt 500;
BA_REL_ "GenSigTimeoutTime" BU_SG_REL_ Getriebe_DQ SG_ 269 MO_Momentenintegral_02 500;
BA_REL_ "GenSigTimeoutTime" BU_SG_REL_ Getriebe_DQ SG_ 269 MO_QBit_Drehzahl_01 500;
BA_REL_ "GenSigTimeoutTime" BU_SG_REL_ Getriebe_DQ SG_ 269 MO_Drehzahl_01 500;
BA_REL_ "GenSigTimeoutTime" BU_SG_REL_ Getriebe_DQ SG_ 269 MO_Luftpfad_Verzugszeit_praed 500;
BA_REL_ "GenSigTimeoutTime" BU_SG_REL_ Motor_konv SG_ 1171 MFG_01_CRC 2000;
BA_REL_ "GenSigTimeoutTime" BU_SG_REL_ Motor_konv SG_ 1171 MFG_01_BZ 2000;
BA_REL_ "GenSigTimeoutTime" BU_SG_REL_ Motor_konv SG_ 1171 MF_Anlassersperre 2000;
BA_REL_ "GenSigTimeoutTime" BU_SG_REL_ Motor_konv SG_ 1171 MF_StartStopp_Info 2000;
BA_REL_ "GenSigTimeoutTime" BU_SG_REL_ Motor_konv SG_ 1171 MF_nachtr_Stopp_Anf 2000;
BA_REL_ "GenSigTimeoutTime" BU_SG_REL_ Motor_konv SG_ 1165 MFG_02_CRC 2000;
BA_REL_ "GenSigTimeoutTime" BU_SG_REL_ Motor_konv SG_ 1165 MFG_02_BZ 2000;
BA_REL_ "GenSigTimeoutTime" BU_SG_REL_ Motor_konv SG_ 1165 MF_VBEG_Anforderung 2000;
BA_REL_ "GenSigTimeoutTime" BU_SG_REL_ Motor_konv SG_ 1165 MF_MFSS_aktiv 2000;
BA_REL_ "GenSigTimeoutTime" BU_SG_REL_ Motor_konv SG_ 1165 MF_MFSS_kodiert 2000;
BA_REL_ "GenSigTimeoutTime" BU_SG_REL_ Motor_konv SG_ 1165 MFG_Status_SREG 2000;
BA_REL_ "GenSigTimeoutTime" BU_SG_REL_ Motor_konv SG_ 1165 MFG_Taster_SREG 2000;
BA_REL_ "GenSigTimeoutTime" BU_SG_REL_ Motor_konv SG_ 1165 MFG_Taster_VREG 2000;
BA_REL_ "GenSigTimeoutTime" BU_SG_REL_ Motor_konv SG_ 1165 MF_VBEG_Geschwindigkeit 2000;
BA_REL_ "GenSigTimeoutTime" BU_SG_REL_ Motor_konv SG_ 1165 MF_ADR_Solldrehzahl 2000;
BA_REL_ "GenSigTimeoutTime" BU_SG_REL_ Motor_konv SG_ 1165 MF_ADR_pos_Rampe 2000;
BA_REL_ "GenSigTimeoutTime" BU_SG_REL_ Motor_konv SG_ 1165 MF_ADR_Fahrpedalsperre 2000;
BA_REL_ "GenSigTimeoutTime" BU_SG_REL_ Motor_konv SG_ 1165 MF_ADR_neg_Rampe 2000;
BA_REL_ "GenSigTimeoutTime" BU_SG_REL_ Motor_konv SG_ 1165 MF_ADR_Anforderung 2000;
BA_REL_ "GenSigTimeoutTime" BU_SG_REL_ Motor_konv SG_ 817 MFL_Tip_Down 5000;
BA_REL_ "GenSigTimeoutTime" BU_SG_REL_ Motor_konv SG_ 817 MFL_Tip_Up 5000;
BA_REL_ "GenSigTimeoutTime" BU_SG_REL_ Parksperre SG_ 329 MO_EP_01_CRC 1000;
BA_REL_ "GenSigTimeoutTime" BU_SG_REL_ Parksperre SG_ 329 MO_EP_01_BZ 1000;
BA_REL_ "GenSigTimeoutTime" BU_SG_REL_ Parksperre SG_ 329 MO_EP_Vorgabe_Position 1000;
BA_REL_ "GenSigTimeoutTime" BU_SG_REL_ Parksperre SG_ 329 MO_EP_Mute 1000;
VAL_ 1171 MF_ZV_Lock 0 "Locktaster_nicht_betaetigt" 1 "Locktaster_betaetigt" ;
VAL_ 1171 MF_Motorweiterlauf 0 "inaktiv" 1 "aktiv" ;
VAL_ 1171 MF_Abzugssperre 0 "inaktiv" 1 "aktiv" ;
VAL_ 1171 MF_Anlassersperre 0 "inaktiv" 1 "aktiv" ;
VAL_ 1171 MF_Variante 0 "keine_Sonderfunktion" 1 "Sondersignalfahrzeug" 2 "Taxi" 3 "Fahrhilfe" 4 "Fahrschule_Extra" 5 "SSF" 6 "DBMC" 7 "Arbeitsmaschine" ;
VAL_ 1171 MF_Schluessel_scan 0 "inaktiv" 1 "aktiv" ;
VAL_ 1171 MF_Laderelais 0 "Relais_offen" 1 "Relais_geschlossen" ;
VAL_ 1171 MF_StartStopp_Info 0 "Motorlauf_nicht_notwendig_(Stoppfreigabe)" 1 "Motoranlauf_nicht_zwingend_notwendig_(Stoppverbot,keine_Startanforderung)" 2 "Motoranlauf_zwingend_notwendig_(Startanforderung)" 3 "Systemfehler" ;
VAL_ 1171 MF_Fernbed_ein 0 "inaktiv" 1 "aktiv" ;
VAL_ 1171 MF_Standlicht 0 "inaktiv" 1 "aktiv" ;
VAL_ 1171 MF_Fahrlicht 0 "inaktiv" 1 "aktiv" ;
VAL_ 1171 MF_interm_Fernlicht 0 "inaktiv" 1 "aktiv" ;
VAL_ 1171 MF_Warnblinker 0 "inaktiv" 1 "aktiv" ;
VAL_ 1171 MF_Fussraumbel 0 "inaktiv" 1 "aktiv" ;
VAL_ 1171 MF_Innenraumbel 0 "inaktiv" 1 "aktiv" ;
VAL_ 1171 MF_Innenraumbel_Unterdrueck 0 "inaktiv" 1 "aktiv" ;
VAL_ 1171 MF_Notstart 0 "kein_Notstart" 1 "Notstart" ;
VAL_ 1171 MF_Blk_li 0 "inaktiv" 1 "aktiv" ;
VAL_ 1171 MF_Blk_re 0 "inaktiv" 1 "aktiv" ;
VAL_ 1171 MF_Lichthupe 0 "inaktiv" 1 "aktiv" ;
VAL_ 1171 MF_Fernlicht 0 "inaktiv" 1 "aktiv" ;
VAL_ 1171 MF_HFS_verriegeln 0 "nicht_verriegeln" 1 "verriegeln" ;
VAL_ 1171 MF_HFS_entriegeln 0 "nicht_entriegeln" 1 "entriegeln" ;
VAL_ 1171 MF_HBFS_verriegeln 0 "nicht_verriegeln" 1 "verriegeln" ;
VAL_ 1171 MF_HBFS_entriegeln 0 "nicht_entriegeln" 1 "entriegeln" ;
VAL_ 1171 MF_Tippwischen 0 "inaktiv" 1 "aktiv" ;
VAL_ 1171 MF_Frontintervall 0 "inaktiv" 1 "aktiv" ;
VAL_ 1171 MF_Wischerstufe_1 0 "inaktiv" 1 "aktiv" ;
VAL_ 1171 MF_Wischerstufe_2 0 "inaktiv" 1 "aktiv" ;
VAL_ 1171 MF_Frontwaschen 0 "inaktiv" 1 "aktiv" ;
VAL_ 1171 MF_nachtr_Stopp_Anf 0 "nicht_angefordert" 1 "angefordert" ;
VAL_ 1171 MF_Heckintervall 0 "inaktiv" 1 "aktiv" ;
VAL_ 1171 MF_Heckwaschen 0 "inaktiv" 1 "aktiv" ;
VAL_ 1171 MF_Summer 0 "inaktiv" 1 "aktiv" ;
VAL_ 1171 MF_Alarm_Blinkertakt 0 "inaktiv" 1 "aktiv" ;
VAL_ 1171 MF_Alarm_Blinker 0 "inaktiv" 1 "aktiv" ;
VAL_ 1171 MF_TFL_Abschaltung 0 "inaktiv" 1 "aktiv" ;
VAL_ 1171 MF_interm_Takt 0 "inaktiv" 1 "aktiv" ;
VAL_ 1171 MF_Tuerentriegelung_hinten 0 "inaktiv" 1 "aktiv" ;
VAL_ 1171 MF_interm_Fahrlicht 0 "inaktiv" 1 "aktiv" ;
VAL_ 1171 MF_Signalhorn 0 "inaktiv" 1 "aktiv" ;
VAL_ 1171 MF_FH_FT_hoch 0 "inaktiv" 1 "aktiv" ;
VAL_ 1171 MF_FH_FT_tief 0 "inaktiv" 1 "aktiv" ;
VAL_ 1171 MF_FH_BT_hoch 0 "inaktiv" 1 "aktiv" ;
VAL_ 1171 MF_FH_BT_tief 0 "inaktiv" 1 "aktiv" ;
VAL_ 1171 MF_FT_verriegeln 0 "nicht_verriegeln" 1 "verriegeln" ;
VAL_ 1171 MF_FT_entriegeln 0 "nicht_entriegeln" 1 "entriegeln" ;
VAL_ 1171 MF_BT_verriegeln 0 "nicht_verriegeln" 1 "verriegeln" ;
VAL_ 1171 MF_BT_entriegeln 0 "nicht_entriegeln" 1 "entriegeln" ;
VAL_ 1165 MF_VBEG_Anforderung 0 "nicht_angefordert" 1 "angefordert" ;
VAL_ 1165 MF_MFSS_aktiv 0 "inaktiv" 1 "aktiv" ;
VAL_ 1165 MF_MFSS_kodiert 0 "auskodiert" 1 "kodiert" ;
VAL_ 1165 MFG_Status_SREG 0 "Sperrung_SREG" 1 "Keine_SREG_Sperrung" ;
VAL_ 1165 MFG_Taster_SREG 0 "Taster_SREG_inaktiv" 1 "Taster_SREG_aktiviert" 2 "Init" 3 "Fehler" ;
VAL_ 1165 MFG_Taster_VREG 0 "Taster_VREG_inaktiv" 1 "Taster_VREG_aktiviert" 2 "Init" 3 "Fehler" ;
VAL_ 1165 MFG_Heizstufe_LSH 0 "Init" 1 "Stufe_1" 2 "Stufe_2" 3 "Stufe_3" 4 "Stufe_4" 5 "Stufe_5" 6 "Stufe_6" 7 "Stufe_7" 8 "Stufe_8" 9 "Stufe_9" 10 "Stufe_10" 15 "Fehler" ;
VAL_ 1165 MFG_Zuheizer_Freigabe 0 "keine_Freigabe_Zuheizer" 1 "Zuheizerfreigabe" ;
VAL_ 1165 MF_VBEG_Geschwindigkeit 255 "Init" ;
VAL_ 1165 MF_ADR_Fahrpedalsperre 0 "inaktiv" 1 "aktiv" ;
VAL_ 1165 MF_ADR_Anforderung 0 "nicht_angefordert" 1 "angefordert" ;
VAL_ 817 MFL_Lokalaktiv 0 "war_nicht_lokal_aktiv" 1 "war_lokal_aktiv" ;
VAL_ 817 MFL_M_Taste 0 "nicht_betaetigt" 1 "betaetigt" ;
VAL_ 817 MFL_Paddle_Verbau 0 "verbaut" 1 "nicht_verbaut" ;
VAL_ 817 MFL_Tastencode_1 0 "Key_Released__No_Key" 1 "Context_Menu" 2 "Menu_Up__Next_Screen" 3 "Menu_Down__Previous_Screen" 4 "Up" 5 "Down" 6 "Up__Down_ThumbWheel" 7 "OK__ThumbWheel_Button" 8 "Cancel__Escape" 9 "Main_Menu" 10 "Side_Menu_left" 11 "Side_Menu_right" 12 "FAS_Menu" 13 "Left__Right_ThumbWheel" 14 "FAS_Menu_ThumbWheel" 16 "Volume_Up" 17 "Volume_Down" 18 "Volume_Up__Down_ThumbWheel" 19 "Volume_ThumbWheel_Button" 20 "Audio_Source" 21 "Arrow_A_Up__Right" 22 "Arrow_A_Down__Left" 23 "Arrow_B_Up__Right" 24 "Arrow_B_Down__Left" 25 "PTT__PushToTalk" 26 "PTT_Cancel" 27 "Route_Info" 28 "Hook" 29 "Hang_Up" 30 "Off_Hook" 31 "Light_On__Off" 32 "Mute" 33 "Joker1" 34 "Joker2" 35 "View" 36 "Arrow_A_Up__Down_ThumbWheel" 37 "Lenkradheizung" 38 "Rekuperation" 39 "Tube_Toggle" 40 "DRS_Drag_Reduction_System" 41 "Stopwatch_Start_Stop" 42 "Stopwatch_Nextlap" 100 "MAP" 101 "MAP_Boost" 102 "Turn_signal_left" 103 "Turn_signal_right" 104 "Turn_signal_off" 105 "Flashlight" 106 "Highbeam" 107 "Washer_button" 108 "Wiper_button_left" 109 "Wiper_button_right" 110 "Wiper_button_cancel" 111 "Exhaust_Sound" 112 "Drive_Select_button" 113 "Sport_button" 114 "ESP_Drift_Selection_ThumbWheel" 115 "PTT_special_vehicle" 116 "TravelAssist" 117 "Launch_Control" 118 "Drift_Mode_Button_Increase" 119 "Drift_Mode_Button_Decrease" 120 "Drift_Mode_Button_Select" 121 "Drive_Mode_Button_Increase" 122 "Drive_Mode_Button_Decrease" 123 "Drive_Mode_Button_Select" 124 "E_Boost_Button_Increase" 125 "E_Boost_Button_Decrease" 126 "E_Boost_Button_Select" 127 "PerformanceHybridButton_Increase" 128 "PerformanceHybridButton_Decrease" 129 "EV_Mode_Button" 130 "HUD_Button" 131 "PASM_Wheel" 132 "PASM_Button" 133 "PTV_Wheel" 134 "PTV_Button" 135 "TC_ESC_Wheel" 136 "TC_ESC_Button" 240 "Startup_Reset" 241 "Initialization" ;
VAL_ 817 MFL_Tastencode_2 0 "Key_Released__No_Key" 1 "Context_Menu" 2 "Menu_Up__Next_Screen" 3 "Menu_Down__Previous_Screen" 4 "Up" 5 "Down" 6 "Up__Down_ThumbWheel" 7 "OK__ThumbWheel_Button" 8 "Cancel__Escape" 9 "Main_Menu" 10 "Side_Menu_left" 11 "Side_Menu_right" 12 "FAS_Menu" 13 "Left__Right_ThumbWheel" 14 "FAS_Menu_ThumbWheel" 16 "Volume_Up" 17 "Volume_Down" 18 "Volume_Up__Down_ThumbWheel" 19 "Volume_ThumbWheel_Button" 20 "Audio_Source" 21 "Arrow_A_Up__Right" 22 "Arrow_A_Down__Left" 23 "Arrow_B_Up__Right" 24 "Arrow_B_Down__Left" 25 "PTT__PushToTalk" 26 "PTT_Cancel" 27 "Route_Info" 28 "Hook" 29 "Hang_Up" 30 "Off_Hook" 31 "Light_On__Off" 32 "Mute" 33 "Joker1" 34 "Joker2" 35 "View" 36 "Arrow_A_Up_Right_Down_Left_ThumbWheel" 37 "Lenkradheizung" 38 "Rekuperation" 39 "Tube_Toggle" 40 "DRS_Drag_Reduction_System" 41 "Stopwatch_Start_Stop" 42 "Stopwatch_Nextlap" 100 "MAP" 101 "MAP_Boost" 102 "Turn_signal_left" 103 "Turn_signal_right" 104 "Turn_signal_off" 105 "Flashlight" 106 "Highbeam" 107 "Washer_button" 108 "Wiper_button_left" 109 "Wiper_button_right" 110 "Wiper_button_cancel" 111 "Exhaust_Sound" 112 "Drive_Select_button" 113 "Sport_button" 114 "ESP_Drift_Selection_ThumbWheel" 115 "PTT_special_vehicle" 116 "TravelAssist" 117 "Launch_Control" 118 "Drift_Mode_Button_Increase" 119 "Drift_Mode_Button_Decrease" 120 "Drift_Mode_Button_Select" 121 "Drive_Mode_Button_Increase" 122 "Drive_Mode_Button_Decrease" 123 "Drive_Mode_Button_Select" 124 "E_Boost_Button_Increase" 125 "E_Boost_Button_Decrease" 126 "E_Boost_Button_Select" 127 "PerformanceHybridButton_Increase" 128 "PerformanceHybridButton_Decrease" 129 "EV_Mode_Button" 130 "HUD_Button" 131 "PASM_Wheel" 132 "PASM_Button" 133 "PTV_Wheel" 134 "PTV_Button" 135 "TC_ESC_Wheel" 136 "TC_ESC_Button" 240 "Startup_Reset" 241 "Initialization" ;
VAL_ 817 MFL_Eventcode_1 0 "W_no_event____T_no_event" 1 "W_1_Tick_up__T_pressed_normal" 2 "W_2_Ticks_up__T_touched" 3 "W_3_Ticks_up__T_double_click_nor" 4 "W_4_Ticks_up__T_long_press_nor_1" 5 "W_5_Ticks_up__T_long_press_nor_2" 6 "W_6_Ticks_up__T_long_press_nor_3" 7 "W_7_Ticks_up" 9 "W_7_Ticks_dn__T_pressed_strong" 10 "W_6_Ticks_dn" 11 "W_5_Ticks_dn__T_double_click_str" 12 "W_4_Ticks_dn__T_long_press_str_1" 13 "W_3_Ticks_dn__T_long_press_str_2" 14 "W_2_Ticks_dn__T_long_press_str_3" 15 "W_1_Tick_dn" ;
VAL_ 817 MFL_Eventcode_2 0 "W_no_event____T_no_event" 1 "W_1_Tick_up__T_pressed_normal" 2 "W_2_Ticks_up__T_touched" 3 "W_3_Ticks_up__T_double_click_nor" 4 "W_4_Ticks_up__T_long_press_nor_1" 5 "W_5_Ticks_up__T_long_press_nor_2" 6 "W_6_Ticks_up__T_long_press_nor_3" 7 "W_7_Ticks_up" 9 "W_7_Ticks_dn__T_pressed_strong" 10 "W_6_Ticks_dn" 11 "W_5_Ticks_dn__T_double_click_str" 12 "W_4_Ticks_dn__T_long_press_str_1" 13 "W_3_Ticks_dn__T_long_press_str_2" 14 "W_2_Ticks_dn__T_long_press_str_3" 15 "W_1_Tick_dn" ;
VAL_ 817 MFL_Marke 0 "VW" 1 "Audi" 2 "Seat" 3 "Skoda" 4 "VW_Nutzf" 5 "Bugatti" 6 "Lamborghini" 7 "Bentley" 8 "Rolls Royce" 9 "Quattro" 10 "kein_Hersteller_1" 11 "kein_Hersteller_2" 12 "kein_Hersteller_3" 13 "kein_Hersteller_4" 14 "Ford" 15 "Porsche" ;
VAL_ 817 MFL_Touch_Event 0 "nicht_betaetigt" 1 "Tippen" 2 "Wischen_Slide" 3 "Geste" 4 "Doppeltippen" 5 "Longpress_1" 6 "Longpress_2" 7 "Longpress_3" 8 "Press" 9 "Strongpress" 10 "reserviert" 11 "reserviert" 12 "reserviert" 13 "reserviert" 14 "Taktgeber_Inkrement" 15 "Fehler" ;
VAL_ 817 MFL_Tip_Down 0 "nicht_betaetigt" 1 "betaetigt" ;
VAL_ 817 MFL_Tip_Up 0 "nicht_betaetigt" 1 "betaetigt" ;
VAL_ 817 MFL_SatModul_links_Err 0 "kein_Fehler" 1 "Fehler" ;
VAL_ 817 MFL_SatModul_rechts_Err 0 "kein_Fehler" 1 "Fehler" ;
VAL_ 817 MFL_LR_HZG_Status 0 "inaktiv" 1 "aktiv" ;
VAL_ 817 MFL_LR_HZG_Err 0 "normal" 1 "Fehler" ;
VAL_ 817 MFL_Signalhorn 0 "nicht_betaetigt" 1 "betaetigt" ;
VAL_ 817 MFL_Signalhorn_Err 0 "normal" 1 "Fehler" ;
VAL_ 817 MFL_Tip_links_Err 0 "normal" 1 "Fehler" ;
VAL_ 817 MFL_Tip_rechts_Err 0 "normal" 1 "Fehler" ;
VAL_ 817 MFL_Taste_links_Err 0 "normal" 1 "Fehler" ;
VAL_ 817 MFL_Taste_rechts_Err 0 "normal" 1 "Fehler" ;
VAL_ 817 MFL_ECU_Err 0 "normal" 1 "Fehler" ;
VAL_ 817 MFL_Response_Err 0 "normal" 1 "Fehler" ;
VAL_ 329 MO_EP_Vorgabe_Position 0 "Init" 1 "beibehalten" 2 "P_Einlegen" 3 "P_Auslegen__N" 4 "R" 5 "D" 6 "P_Einlegen_auto" ;
VAL_ 329 MO_EP_Mute 0 "Senden_ein" 1 "Senden_aus" ;
VAL_ 329 MO_EP_Ist_Haltemagnet 0 "Init__nicht_verbaut" 1 "haelt_nicht" 2 "haelt" 3 "Fehler" ;
VAL_ 15 MO_SOPC 0 "kein_SOPC" 1 "SOPC" ;
VAL_ 1600 MO_QBit_Ansaugluft_Temp 0 "gueltiger_Wert" 1 "Ersatz_Init_oder_Fehlerwert" ;
VAL_ 1600 MO_QBit_Oel_Temp 0 "gueltiger_Wert" 1 "Ersatz_Init_oder_Fehlerwert" ;
VAL_ 1600 MO_QBit_Kuehlmittel_Temp 0 "gueltiger_Wert" 1 "Ersatz_Init_oder_Fehlerwert" ;
VAL_ 1600 MO_KL15_Abschaltempfehlung 0 "Keine Empfehlung" 1 "Abschaltempfehlung" ;
VAL_ 1600 MO_HYB_Fehler_HV_Netz 0 "i_O" 1 "kein_generatorischer_Betrieb_moeglich" ;
VAL_ 1600 MO_aktives_Getriebeheizen 0 "kein_Ventil_ansteuern" 1 "Ventil_muss_angesteuert_werden" ;
VAL_ 1600 MO_Absperrventil_oeffnen 0 "nicht_verfuegbar" 1 "Ansteuerung_Ventil_zulaessig" 2 "Ventil_oeffnen_oder_geoeffnet" 3 "Ventil_schliessen_oder_geschlossen" ;
VAL_ 1600 MO_Ansaugluft_Temp 254 "Init" 255 "Fehler" ;
VAL_ 1600 MO_Oel_Temp 253 "nicht_verbaut" 254 "Init" 255 "Fehler" ;
VAL_ 1600 MO_Kuehlmittel_Temp 254 "Init" 255 "Fehler" ;
VAL_ 1600 MO_Hoeheninfo 255 "Fehler" ;
VAL_ 1600 MO_Kennfeldk 0 "keine Kennfeldkühlung vorhanden" 1 "Kennfeldkühlung vorhanden" ;
VAL_ 1600 MO_Versionsinfo_02 0 "zum_Projektbeginn_aufgeraeumter_CAN" 1 "Motor_03_mit_10ms" 16 "MQB_mit_neuer_Momentenschnittstelle" ;
VAL_ 1600 MO_QBit_Hoeheninfo 0 "gueltiger_Wert" 1 "Ersatz_Init_oder_Fehlerwert" ;
VAL_ 1600 MO_Getriebe_kuehlen 0 "nicht_kuehlen" 1 "kuehlen" ;
VAL_ 1600 MO_Heizungspumpenansteuerung 13 "Fehler" 14 "Init" 15 "nicht_verbaut" ;
VAL_ 1600 MO_SpannungsAnf 0 "keine_Anforderung" 1 "Anforderung" ;
VAL_ 1607 MO_ITM_Kuehlmittel_Temp 0 "nicht_verbaut" 1 "Init" 2 "Fehler" ;
VAL_ 1607 MO_E85_Sensor 13 "nicht_verbaut" 14 "Init" 15 "Fehler" ;
VAL_ 1607 SCR_Anz_Motorstarts 0 "Anzahl_moeglicher_Restarts" 1 "Anzahl_moeglicher_Restarts" 2 "Anzahl_moeglicher_Restarts" 3 "Anzahl_moeglicher_Restarts" 4 "Anzahl_moeglicher_Restarts" 5 "Anzahl_moeglicher_Restarts" 6 "Anzahl_moeglicher_Restarts" 7 "Anzahl_moeglicher_Restarts" 8 "Anzahl_moeglicher_Restarts" 9 "Anzahl_moeglicher_Restarts" 10 "Anzahl_moeglicher_Restarts" 11 "Anzahl_moeglicher_Restarts" 12 "Anzahl_moeglicher_Restarts" 13 "Anzahl_moeglicher_Restarts" 14 "Fahrbarkeitseinschraenkung" 15 "keine_Einschraenkung" ;
VAL_ 1607 SCR_Reichweite 32767 "keine_Anzeige" ;
VAL_ 1607 MO_Ethanol_Spuelhinweis 0 "Kein_Hinweis" 1 "Spuelhinweis_aktiv" ;
VAL_ 1607 SCR_Warnstufe_1 0 "nicht_aktiv" 1 "Warnstufe_1_aktiv" ;
VAL_ 1607 SCR_Warnstufe_2 0 "nicht_aktiv" 1 "Warnstufe_2_aktiv" ;
VAL_ 1607 SCR_Text 0 "kein_Text" 1 "Warntext_1" 2 "Warntext_2" 3 "Hinweis_Fuellstand" 4 "Reserve" 5 "SysFehler_1" 6 "SysFehler_2" 7 "Hinweis_Systemfehler" ;
VAL_ 1607 SCR_Akustik 0 "keine_Akustik" 1 "Akustik_1" 2 "Akustik_2" 3 "Akustik_bei_Hinweis" ;
VAL_ 1607 SCR_verbaut 0 "kein_SCR" 1 "SCR_verbaut" ;
VAL_ 1607 MO_Kraftstofffilter_Wasser 0 "keine_Anzeige" 1 "Abscheidevolumen_erschoepft" ;
VAL_ 1607 SCR_Systemfehler 0 "Warnung_nicht_aktiv" 1 "Warnung_aktiv" ;
VAL_ 1607 SCR_Inducement_Strategie 0 "Restart_Strategie" 1 "Reduced_Drivability_Strategie" ;
VAL_ 1607 MO_CO2_Faktor 0 "nicht_verbaut" 4095 "Fehler" ;
VAL_ 1607 MO_MKB_MUX 0 "MKB_01" 1 "MKB_02" 2 "MKB_03" 3 "MKB_04" ;
VAL_ 1607 MO_MKB_01 0 "Minus" 1 "A" 2 "B" 3 "C" 4 "D" 5 "E" 6 "F" 7 "G" 8 "H" 9 "I" 10 "J" 11 "K" 12 "L" 13 "M" 14 "N" 15 "O" 16 "P" 17 "Q" 18 "R" 19 "S" 20 "T" 21 "U" 22 "V" 23 "W" 24 "X" 25 "Y" 26 "Z" 27 "Leerzeichen" 28 "Leerzeichen" 29 "Leerzeichen" 30 "Leerzeichen" 31 "Unterstrich" ;
VAL_ 1607 MO_MKB_02 0 "Minus" 1 "A" 2 "B" 3 "C" 4 "D" 5 "E" 6 "F" 7 "G" 8 "H" 9 "I" 10 "J" 11 "K" 12 "L" 13 "M" 14 "N" 15 "O" 16 "P" 17 "Q" 18 "R" 19 "S" 20 "T" 21 "U" 22 "V" 23 "W" 24 "X" 25 "Y" 26 "Z" 27 "Leerzeichen" 28 "Leerzeichen" 29 "Leerzeichen" 30 "Leerzeichen" 31 "Unterstrich" ;
VAL_ 1607 MO_MKB_03 0 "Minus" 1 "A" 2 "B" 3 "C" 4 "D" 5 "E" 6 "F" 7 "G" 8 "H" 9 "I" 10 "J" 11 "K" 12 "L" 13 "M" 14 "N" 15 "O" 16 "P" 17 "Q" 18 "R" 19 "S" 20 "T" 21 "U" 22 "V" 23 "W" 24 "X" 25 "Y" 26 "Z" 27 "Leerzeichen" 28 "Leerzeichen" 29 "Leerzeichen" 30 "Leerzeichen" 31 "Unterstrich" ;
VAL_ 1607 MO_MKB_04 0 "Minus" 1 "A" 2 "B" 3 "C" 4 "D" 5 "E" 6 "F" 7 "G" 8 "H" 9 "I" 10 "J" 11 "K" 12 "L" 13 "M" 14 "N" 15 "O" 16 "P" 17 "Q" 18 "R" 19 "S" 20 "T" 21 "U" 22 "V" 23 "W" 24 "X" 25 "Y" 26 "Z" 27 "Leerzeichen" 28 "Leerzeichen" 29 "Leerzeichen" 30 "Leerzeichen" 31 "Unterstrich" ;
VAL_ 958 MO_StartStopp_Status 0 "System_in_diesem_KL15_Zyklus_nicht_verfuegbar" 1 "System_aktiv_keine_Freigabe_durch_StartStop_Koordinator" 2 "System_aktiv_alle_Freigaben_liegen_vor" 3 "System_aktiv_mindestens_eine_Freigabe_fehlt" ;
VAL_ 958 MO_StartStopp_Wiederstart 0 "Wiederstart_inaktiv" 1 "Wiederstart_aktiv" ;
VAL_ 958 MO_StartStopp_Motorstopp 0 "Motor_Stop_inaktiv" 1 "Motor_Stop_aktiv" ;
VAL_ 958 MO_Freig_Reku 0 "Rekuperations-Modus aus" 1 "Empfehlung Spannungsanhebung" 2 "Empfehlung Spannungsabsenkung" 3 "Rekuperationsmodus aktiv, Spannungsvariation nicht notwendig" ;
VAL_ 958 MO_Kl_75 0 "Aus" 1 "Ein" ;
VAL_ 958 MO_Kl_50 0 "aus" 1 "KL50_ein_Startausfuehrung_Fahrer" ;
VAL_ 958 MO_Gangposition 0 "Gang_N" 1 "Gang_1" 2 "Gang_2" 3 "Gang_3" 4 "Gang_4" 5 "Gang_5" 6 "Gang_6" 7 "Gang_7" 8 "Gang_8" 9 "Automat_P" 10 "Automat_Vorwaerts_S" 11 "Automat_Vorwaerts_D/E" 12 "Zwischenstellung" 13 "Gang_R" 14 "Istgang_nicht_definiert" 15 "Fehler" ;
VAL_ 958 MO_StartStopp_Fahrerwunsch 0 "Init" 1 "Stoppverbot_durch_Fahrer" 2 "Stoppfreigabe_durch_Fahrer" 3 "Stoppanforderung_durch_Fahrer" ;
VAL_ 958 MO_HYB_Fahrbereitschaft 0 "keine_Fahrbereitschaft" 1 "Fahrbereitschaft" ;
VAL_ 958 MO_Ext_E_Fahrt_aktiv 0 "Rueckmeldung_E_Taster_aus" 1 "Rueckmeldung_E_Taster_ein" ;
VAL_ 958 MO_Fahrer_bremst 0 "kein_Bremsen" 1 "Bremse_betaetigt" ;
VAL_ 958 MO_QBit_Fahrer_bremst 0 "gueltiger_Wert" 1 "Ersatz_Init_oder_Fehlerwert" ;
VAL_ 958 MO_BLS 0 "kein_Bremsen" 1 "Bremse_betaetigt" ;
VAL_ 958 MO_Konsistenz_Bremsped 0 "Bremspedalinformation_plausibel" 1 "Bremspedalinformation_unplausibel" ;
VAL_ 958 MO_Timeout_ESP 0 "Empfang_iO" 1 "Timeout" ;
VAL_ 958 MO_Klima_Eingr 0 "kein Eingriff" 1 "Klimakompressor ausschalten" 2 "Klimakompressor Leistungsreduzierung" 3 "Klimakompressor aufgrund der Heissleuchtenvorwarnung ausschalten" ;
VAL_ 958 MO_Aussp_Anlass 0 "Anlasser_darf_angesteuert_werden" 1 "Anlasser_ausspuren__Ansteuerung_nicht_moeglich" ;
VAL_ 958 MO_Freig_Anlass 0 "Start_nicht_zulaessig" 1 "Startfreigabe" ;
VAL_ 958 MO_Kuppl_schalter 0 "Schalter_sagt_ausgekuppelt" 1 "Schalter_sagt_eingekuppelt" ;
VAL_ 958 MO_Interlock 0 "Interlockschalter_nicht_betaetigt" 1 "Interlockschalter_betaetigt" ;
VAL_ 958 MO_Motor_laeuft 0 "Motor_laeuft_nicht" 1 "Motor_laeuft_autark_und_stabil_und_darf_mechanisch_belastet_werden" ;
VAL_ 958 MO_Kickdown 0 "kein_Kickdown" 1 "Kickdown" ;
VAL_ 958 MO_QBit_KL_75 0 "gueltiger_Wert" 1 "Ersatz_Init_oder_Fehlerwert" ;
VAL_ 958 MO_EKlKomLeiRed 0 "keine_Leistungsbegr" 1 "Leistungsbegr_75" 2 "Leistungsbegr_50" 3 "Leistungsbegr_25" ;
VAL_ 958 MO_Handshake_STH 0 "keine EKP-Ansteuerung durch STH-Anforderung" 1 "EKP-Ansteuerung durch STH-Anforderung" ;
VAL_ 958 MO_BKV_Unterdruckwarnung 0 "Unterdruckhaushalt_iO" 1 "Unterdruckhaushalt_niO" ;
VAL_ 958 MO_Freigabe_Segeln 0 "Segelbetrieb_nicht_freigegeben" 1 "Segelbetrieb_freigegeben" ;
VAL_ 958 MO_PTC_Status 0 "nicht_unterstuetzt" 1 "Stufe_0" 2 "Stufe_1" 3 "Stufe_2" 4 "Stufe_3" 7 "PTC_am_BCM" ;
VAL_ 958 MO_QBit_Gangposition 0 "gueltiger_Wert" 1 "Ersatz_Init_oder_Fehlerwert" ;
VAL_ 958 MO_Signalquelle_Gangposition 0 "Sensorsignal" 1 "Modellsignal" ;
VAL_ 958 MO_Remotestart_Betrieb 0 "MSG_nicht_bereit_fuer_RS_Betrieb" 1 "MSG_bereit_fuer_oder_im_RS_Betrieb" ;
VAL_ 958 MO_Remotestart_moeglich 0 "Remotestart_nicht_moeglich" 1 "Remotestart_moeglich" ;
VAL_ 958 MO_FMAus_aktiv 0 "inaktiv" 1 "Segeln_mit_Motor_aus_aktiv" ;
VAL_ 958 MO_FMAus_Startvariante 0 "kein_Motorstart" 1 "Motorstart_elektrischer_Starter" 2 "GetriebeAnschleppstart" 3 "GetriebeNotAnschleppstart" ;
VAL_ 958 MO_BMS_NV_Anf_stuetzen 0 "nicht_notwendig" 1 "notwendig" ;
VAL_ 958 MO_Zylinderabschaltung 0 "Vollmotorbetrieb_VMB" 1 "Uebergang_HMB_in_VMB" 2 "Uebergang_VMB_in_HMB" 3 "Halbmotorbetrieb_HMB" ;
VAL_ 958 MO_HYB_VM_aktiv 0 "VM_nicht_aktiv" 1 "VM_aktiv" ;
VAL_ 958 MO_StartVorauss_erfuellt 0 "Signal_nicht_bedient" 1 "StartVorauss_nicht_ueberpruefbar" 2 "StartVorauss_nicht_erfuellt" 3 "StartVorauss_erfuellt" ;
VAL_ 1631 TSK_QBit_Steigung 0 "gueltiger_Wert" 1 "Ersatz_Init_oder_Fehlerwert" ;
VAL_ 1631 TSK_QBit_Fahrzeugmasse 0 "gueltiger_Wert" 1 "Ersatz_Init_oder_Fehlerwert" ;
VAL_ 1631 MO_SpannungsAnf_02 0 "keine_Anforderung" 1 "Anforderung_Stufe_1" 2 "Anforderung_Stufe_2" 3 "Anforderung_Stufe_3" ;
VAL_ 1631 MO_DPF_reg 0 "DPF_regeneriert_nicht" 1 "DPF_regeneriert" ;
VAL_ 1631 MO_Heizstrom_EKAT 127 "Fehler" ;
VAL_ 1631 MO_Heizstrom_SCR 63 "Fehler" ;
VAL_ 1631 MO_Anzeige_Kaltleuchte 0 "Lampe_aus" 1 "Lampe_an" ;
VAL_ 1631 MO_P_Generator_ungefiltert_Anf 0 "nicht_angefordert" 1 "angefordert" ;
VAL_ 1631 MO_Energieinhalt_BMS 4094 "Init" 4095 "Fehler" ;
VAL_ 1631 TSK_Fahrzeugmasse_02 255 "Fehler" ;
VAL_ 1631 TSK_Steigung_02 0 "Init_oder_nicht_verbaut" 255 "Fehler" ;
VAL_ 1648 MO_ANC_Kennfeld_Anf 0 "Kennfeld_1" 1 "Uebergang_Kennfeld_2_nach_1" 2 "Uebergang_Kennfeld_1_nach_2" 3 "Kennfeld_2" ;
VAL_ 1648 MO_Bremslicht_Reku 0 "Aus" 1 "Ein" ;
VAL_ 1648 MO_StartStopp_PopUp 0 "Statuswechsel_ohne_Taster (Init)" 1 "StSt_per_Taster_deaktiviert" 2 "StSt_per_Taster_aktiviert" 3 "nicht verwendet" ;
VAL_ 1648 MO1_Sperr_Info_WFS 0 "nicht_gesperrt" 1 "gesperrt" ;
VAL_ 1648 MO1_Freigabe_Info_WFS 0 "ungueltig" 1 "gueltig" ;
VAL_ 1648 MO_EPCL 0 "EPCL_aus_kein_Text" 1 "EPCL_gelb_Stoerung" 2 "EPCL_gelb_Leistungsbeschraenkung" 3 "EPCL_rot_Fzg_sicher_abstellen" ;
VAL_ 1648 MO_Zylabsch_Texte_02 0 "ein_ZAS_generell_keine_ZAS_Anzeigen" 1 "ZAS_im_VMB" 2 "ZAS_im_ASB_1_Zyl_aktiv" 3 "ZAS_im_ASB_2_Zyl_aktiv" 4 "ZAS_im_ASB_3_Zyl_aktiv" 5 "ZAS_im_ASB_4_Zyl_aktiv" 6 "ZAS_im_ASB_5_Zyl_aktiv" 7 "ZAS_im_ASB_6_Zyl_aktiv" 8 "ZAS_im_ASB_8_Zyl_aktiv" 9 "ZAS_im_ASB_12_Zyl_aktiv" 13 "Uebergangsbetrieb" 14 "keine_ZAS_Anzeige_ggf_Stopp_Schub_Betrieb" 15 "ZAS_Stoerungs_Anzeige" ;
VAL_ 1648 MO_Fahrzeugtyp 0 "Verbrenner_Fahrzeug" 1 "Hybrid" 2 "E_Fahrzeug" 3 "E_Fahrzeug_mit_Range_Extender" 4 "Brennstoffzellenfahrzeug" 5 "tbd" 6 "tbd" 7 "tbd" ;
VAL_ 1648 MO_Abstellzeit 254 "Init" 255 "reserviert" ;
VAL_ 1648 MO_Abstellzeit_Status 0 "Abstellzeit_nicht_berechnet" 1 "Abstellzeit_berechnet" 2 "Abstellzeit_Minimalwert" 3 "Abstellzeit_ungueltig" ;
VAL_ 1648 MO1_Freigabe_Verfallsinfo_WFS 0 "verfaellt_nicht" 1 "verfaellt" ;
VAL_ 1648 MO_Hybrid_StartStopp_LED 0 "LED_aus_und_Blinken_aus" 1 "LED_ein_und_Blinken_aus" 2 "LED_ein_und_Blinken_ein_50_percent" 3 "reserviert" ;
VAL_ 1648 MO_Fehler_Zylabsch 0 "kein_Fehler" 1 "Notlauf_Vollmotorbetrieb" 2 "Notlauf_mindestens_einem_abgesch_Zylinder" ;
VAL_ 1648 MO_Anzahl_Abgesch_Zyl 0 "Vollmotorbetrieb" 1 "1_Zylinder_abgeschaltet" 2 "2_Zylinder_abgeschaltet" 3 "3_Zylinder_abgeschaltet" 4 "4_Zylinder_abgeschaltet" 5 "5_Zylinder_abgeschaltet" 6 "6_Zylinder_abgeschaltet" 7 "8_Zylinder_abgeschaltet" ;
VAL_ 1648 MO_Zylabsch_Texte 0 "keine_Texte" 1 "Zylinderabschaltung_deaktivieren" 2 "Zylinderabschaltung_aktivieren" 3 "Zylinderabschaltung_unruhig" ;
VAL_ 1648 MO_Ethanol_BS_Texte 0 "kein_Text" 1 "E85_Warm_Up" 2 "FlexFuel_Warnung_Stufe_3" 3 "Warmfahrempfehlung_MQB__FlexFuel_Warnung_Stufe_1" 4 "FlexFuel_Warnung_Stufe_2" 5 "FlexFuel_Warnung_Stufe_4" 6 "E25_Warm_Up" ;
VAL_ 1648 MO_Drehzahl_Warnung 0 "keinen_Warnhinweis_anzeigen" 1 "Warnhinweis_anzeigen" ;
VAL_ 1648 MO_obere_Drehzahlgrenze 0 "Init" ;
VAL_ 1654 StSt_Koord_Wiederstart_Anz_09 0 "keine_Anzeige" 1 "Ampel_Info" ;
VAL_ 1654 StSt_Koord_Wiederstart_Anz_10 0 "keine_Anzeige" 1 "Race_Mode" ;
VAL_ 1654 StSt_Koord_Wiederstart_Anz_11 0 "keine_Anzeige" 1 "Wiederstart_PEA" ;
VAL_ 1654 MO_Wiederstart_Anz_01 0 "keine_Anzeige" 1 "Motortemperatur" ;
VAL_ 1654 MO_Wiederstart_Anz_02 0 "keine_Anzeige" 1 "BKV_Unterdruck" ;
VAL_ 1654 MO_Wiederstart_Anz_03 0 "keine_Anzeige" 1 "SCR_System" ;
VAL_ 1654 MO_Wiederstart_Anz_Std 0 "keine_Anzeige" 1 "Standard_Wiederstartgrund" ;
VAL_ 1654 MO_Stoppverbot_Anz_01 0 "keine_Anzeige" 1 "Abgasanlage" ;
VAL_ 1654 MO_Stoppverbot_Anz_02 0 "keine_Anzeige" 1 "Motortemperatur_Min" ;
VAL_ 1654 MO_Stoppverbot_Anz_03 0 "keine_Anzeige" 1 "Motortemperatur_Max" ;
VAL_ 1654 MO_Stoppverbot_Anz_04 0 "keine_Anzeige" 1 "Umgebungsluftdichte" ;
VAL_ 1654 MO_Stoppverbot_Anz_05 0 "keine_Anzeige" 1 "Bremsunterdruck" ;
VAL_ 1654 MO_Stoppverbot_Anz_06 0 "keine_Anzeige" 1 "Adaptionen" ;
VAL_ 1654 MO_Stoppverbot_Anz_07 0 "keine_Anzeige" 1 "Gangsensor" ;
VAL_ 1654 MO_Stoppverbot_Anz_08 0 "keine_Anzeige" 1 "Diagnose_Tankentlueftung" ;
VAL_ 1654 MO_Stoppverbot_Anz_09 0 "keine_Anzeige" 1 "FlexFuel_SCR_CNG" ;
VAL_ 1654 MO_Stoppverbot_Anz_10 0 "keine_Anzeige" 1 "OPF_DPF_Regeneration" ;
VAL_ 1654 MO_Stoppverbot_Anz_11 0 "keine_Anzeige" 1 "sporadische_Stoppverhinderung" ;
VAL_ 1654 MO_Stoppverbot_Anz_Std 0 "keine_Anzeige" 1 "Standard_Stoppvetogrund" ;
VAL_ 1654 StSt_Koord_Stoppverbot_Anz_20 0 "Ampel_verh_MotStopp_nicht" 1 "Ampel_verh_Motorstopp" ;
VAL_ 1654 StSt_Koord_Stoppverbot_Anz_21 0 "Race_Mode_verh_MotStopp_nicht" 1 "Race_Mode_verh_Motorstopp" ;
VAL_ 1654 StSt_Koord_Wiederstart_Anz_Std 0 "keine_Anzeige" 1 "Standard_Wiederstartgrund" ;
VAL_ 1654 StSt_Koord_Status_Bremspedalkzpt 0 "Bremspedalstart_moeglich" 1 "kein_Bremspedalstart_moeglich" ;
VAL_ 1654 StSt_Koord_Wiederstart_Anz_01 0 "keine_Anzeige" 1 "Kupplung_Bremse" ;
VAL_ 1654 StSt_Koord_Wiederstart_Anz_02 0 "keine_Anzeige" 1 "Fahrpedal" ;
VAL_ 1654 StSt_Koord_Wiederstart_Anz_03 0 "keine_Anzeige" 1 "Taster" ;
VAL_ 1654 StSt_Koord_Wiederstart_Anz_04 0 "keine_Anzeige" 1 "Schalten_nach_R" ;
VAL_ 1654 StSt_Koord_Wiederstart_Anz_05 0 "keine_Anzeige" 1 "Anrollen" ;
VAL_ 1654 StSt_Koord_Wiederstart_Anz_06 0 "keine_Anzeige" 1 "Notstart" ;
VAL_ 1654 StSt_Koord_Wiederstart_Anz_07 0 "keine_Anzeige" 1 "Lenkrad" ;
VAL_ 1654 StSt_Koord_Wiederstart_Anz_08 0 "keine_Anzeige" 1 "Offroad_Sport_und_ESP_Taster" ;
VAL_ 1654 StSt_Koord_Stoppverbot_Anz_01 0 "keine_Anzeige" 1 "Fahrzeugneigung" ;
VAL_ 1654 StSt_Koord_Stoppverbot_Anz_02 0 "keine_Anzeige" 1 "Wiederholstopp_Sperre" ;
VAL_ 1654 StSt_Koord_Stoppverbot_Anz_03 0 "keine_Anzeige" 1 "Rangiererkennung_MQ_DQ" ;
VAL_ 1654 StSt_Koord_Stoppverbot_Anz_04 0 "keine_Anzeige" 1 "Spielschutz" ;
VAL_ 1654 StSt_Koord_Stoppverbot_Anz_05 0 "keine_Anzeige" 1 "Taster_StSt_ausgeschaltet" ;
VAL_ 1654 StSt_Koord_Stoppverbot_Anz_06 0 "keine_Anzeige" 1 "Motorhaube" ;
VAL_ 1654 StSt_Koord_Stoppverbot_Anz_07 0 "keine_Anzeige" 1 "Fahrergurt" ;
VAL_ 1654 StSt_Koord_Stoppverbot_Anz_08 0 "keine_Anzeige" 1 "Fahrertuer" ;
VAL_ 1654 StSt_Koord_Stoppverbot_Anz_09 0 "keine_Anzeige" 1 "Fahrpedal" ;
VAL_ 1654 StSt_Koord_Stoppverbot_Anz_10 0 "keine_Anzeige" 1 "Lenkwinkel_Lenkwinkelgeschwindigkeit" ;
VAL_ 1654 StSt_Koord_Stoppverbot_Anz_11 0 "keine_Anzeige" 1 "Anhaenger" ;
VAL_ 1654 StSt_Koord_Stoppverbot_Anz_12 0 "keine_Anzeige" 1 "Wegfahrsperre_aktiv" ;
VAL_ 1654 StSt_Koord_Stoppverbot_Anz_13 0 "keine_Anzeige" 1 "dauerhafte_Fahrerabwesenheit" ;
VAL_ 1654 StSt_Koord_Stoppverbot_Anz_14 0 "keine_Anzeige" 1 "temporaere_Fahrerabwesenheit" ;
VAL_ 1654 StSt_Koord_Stoppverbot_Anz_15 0 "keine_Anzeige" 1 "Offroad_Sport_und_ESP_Taster" ;
VAL_ 1654 StSt_Koord_Stoppverbot_Anz_16 0 "keine_Anzeige" 1 "Neutralgang" ;
VAL_ 1654 StSt_Koord_Stoppverbot_Anz_17 0 "Fahrerhandl_verh_MotStopp_nicht" 1 "fehl_Fahrerhandl_verh_Motorstopp" ;
VAL_ 1654 StSt_Koord_Stoppverbot_Anz_Std 0 "keine_Anzeige" 1 "Standard_Stoppvetogrund" ;
VAL_ 1654 StSt_Koord_Stoppverbot_Anz_18 0 "PSD_verh_MotStopp_nicht" 1 "PSD_verh_Motorstopp" ;
VAL_ 1654 StSt_Koord_Stoppverbot_Anz_19 0 "Kurzstopp_verh_MotStopp_nicht" 1 "Kurzstopp_verh_Motorstopp" ;
VAL_ 1654 MO_StaGluehk 15 "Fehler" ;
VAL_ 1391 MO_Anzeige_Aufheizfortschritt 126 "Init" 127 "Fehler" ;
VAL_ 1391 MO_IstLeistung_EKAT 126 "Init" 127 "Fehler" ;
VAL_ 1391 MO_HYB_Drehzahl_VM 65280 "Fehler" ;
VAL_ 967 MO_Kuehlerluefter_MUX 0 "Kuehlerluefter_1" 1 "Kuehlerluefter_2" ;
VAL_ 967 MO_Kuehlerluefter_1 126 "Init" 127 "Fehler" ;
VAL_ 967 MO_Kuehlerluefter_2 126 "Init" 127 "Fehler" ;
VAL_ 967 MO_EFLEX_Lampe 0 "Lampe_aus" 1 "Lampe_ein" 2 "Lampe_blinkend" 3 "Lampe_blinkend_mit_Akustik" ;
VAL_ 967 MO_KJS_nicht_bereit 0 "kein_Fehler" 1 "Fehler" ;
VAL_ 967 MO_ITM_Warnung_Pumpe 0 "keine_Warnung" 1 "ITM_Warnung" ;
VAL_ 967 WIV_Anzeige_aktiv 0 "Anzeige aus" 1 "WIV Anzeige aktiv" ;
VAL_ 967 WIV_Oelmin_Warn 0 "in_Ordnung" 1 "Warnung" ;
VAL_ 967 WIV_Sensorfehler 0 "in_Ordnung" 1 "Sensor_defekt" ;
VAL_ 967 WIV_Schieflage 0 "Fahrzeug_gerade" 1 "Fahrzeug_in_Schieflage" ;
VAL_ 967 MO_Zustand_HWP 0 "HWP_nicht_schaltbar" 1 "HWP_foerdert_nicht" 2 "HWP_foerdert" 3 "reserviert" ;
VAL_ 967 OLEV_Systemstoerung 0 "Ölsystem i.O." 1 "Systemstörung Ölsystem" ;
VAL_ 967 MO_Oelwarnung_max 0 "keine_Warnung" 1 "Warnfall_aktiv" ;
VAL_ 967 WIV_Oelsystem_aktiv 0 "Anzeige_aus" 1 "Anzeige_aktiv" ;
VAL_ 967 WIV_nicht_betriebswarm 0 "Motor_warm" 1 "Motor_nicht_betriebswarm" ;
VAL_ 967 WIV_Ueberfuell_Warn 0 "in_Ordnung" 1 "Ueberfuellwarnung" ;
VAL_ 967 WIV_laufender_Motor 0 "Messung_moeglich" 1 "Messung_nicht_moeglich" ;
VAL_ 967 MO_E_Warnungen 0 "keine_Anzeige" 1 "Fehler_Elektrosystem_Anhalten" 2 "Fehler_Elektrosystem_Werkstatt" 3 "Elektrosystem_ueberhitzt_Stopp" 4 "Fehler_Hybridsystem_Anhalten" 5 "Fehler_Hybridsystem_Werkstatt" 6 "Fehler_Wasserstoffsystem_Anhalte" 7 "Fehler_Wasserstoffsystem_Werksta" 8 "reserviert_keine_Anzeige" 9 "reserviert_keine_Anzeige" 10 "reserviert_keine_Anzeige" 11 "reserviert_keine_Anzeige" 12 "reserviert_keine_Anzeige" 13 "reserviert_keine_Anzeige" 14 "reserviert_keine_Anzeige" 15 "reserviert_keine_Anzeige" ;
VAL_ 967 MO_Text_Motorstart 0 "keine_Anzeige" 1 "Motor_im_Stoppbetrieb" 2 "StartStopp_sicherheitsbedingt_deaktiviert" 3 "System_fordert_Wiederstart" 4 "Aufforderung_Motorstart" 5 "Motorlauf_noetig" 6 "Motorlaufwarnung" 9 "Unerwuenschter_Motorstillstand" 10 "Motorstart_nicht_moeglich" 11 "Fehler_Kupplungsschalter" 12 "Motor_startet" 13 "Kupplung_betaetigen" 14 "Waehlhebel_in_PN_Position" 15 "Bremse_treten" ;
VAL_ 967 MO_E_Texte 0 "keine_Anzeige" 1 "Batterie_fast_leer" 2 "Ladestecker_nicht_fahrbereit" 3 "VM_Betrieb_erforderlich" 4 "Batterie_laedt_Nicht_ausschalten" 5 "Bitte_Bremse_treten" 6 "manueller_Neustart_erforderlich" 7 "Stopp_Fahrzeug_nicht_abschleppen" 8 "kein_Neustart_Haube_nicht_oeffnen" 9 "Motorstart_im_naechsten_Zyklus" 10 "VM_erforderlich_EVMode_abwaehlen" 11 "laengerer_VMBetrieb_Bordbuch" 12 "Tank_leer_VM_nicht_verfuegbar" 13 "Bitte_warten_Motor_startet" 14 "kein_Start_Batterietemperatur" 15 "Ende_elektrische_Reichweite_erreicht" ;
VAL_ 967 WIV_Oeldyn_avl 0 "Oeldyn_nicht_vorhanden" 1 "Oeldyn_vorhanden" ;
VAL_ 967 OLEV_Oelstand_nicht_vorhanden 0 "Ölstand vorhanden" 1 "Ölstand nicht vorhanden" ;
VAL_ 967 MO_Systemlampe 0 "Lampe aus" 1 "Lampe ein" ;
VAL_ 967 MO_OBD2_Lampe 0 "Lampe aus" 1 "Lampe ein" ;
VAL_ 967 MO_Heissleuchte 0 "Lampe aus" 1 "Lampe ein" ;
VAL_ 967 MO_Partikel_Lampe 0 "Lampe aus" 1 "Lampe ein" ;
VAL_ 967 MO_RedFahrleistung_Lampe 0 "Lampe_aus" 1 "Lampe_ein" ;
VAL_ 967 WIV_Oelstand_nicht_vorhanden 0 "Ölstand vorhanden" 1 "Ölstand nicht vorhanden" ;
VAL_ 967 WIV_nachfuellanzeige_ein 0 "keine_Nachfuellanzeige" 1 "Nachfuellanzeige" ;
VAL_ 967 WIV_Ueberfuell_deaktiv 0 "Ueberfuellwarnung_am_Kombi_aktiv" 1 "Ueberfuellwarnung_am_Kombi_deaktiv" ;
VAL_ 967 WIV_Unterfuell_Warn 0 "in_Ordnung" 1 "Unterfuellwarnung" ;
VAL_ 967 MO_Tankdeckel_Lampe 0 "Lampe aus" 1 "Lampe ein" ;
VAL_ 967 MO_Text_Tankdeckelwarn 0 "kein_Text" 1 "Anzeige_Text_Tankdeckelwarnung_im_Kombi" ;
VAL_ 967 MO_Vorglueh_Lampe 0 "Lampe_aus" 1 "Lampe_ein" ;
VAL_ 967 WIV_Oeldr_Warn_Motor 0 "keine_Warnung" 1 "niedrige_Oeldruckstufe_nicht_erreicht" ;
VAL_ 967 MO_E_Mode 0 "keine_Anzeige" 1 "E_Mode_passiv" 2 "E_Mode_aktiv" 3 "E_Mode_inaktiv_nicht_verfuegbar" 4 "E_Mode_aktiv_nicht_verfuegbar" 5 "reserviert_keine_Anzeige" 6 "reserviert_keine_Anzeige" 7 "reserviert_keine_Anzeige" ;
VAL_ 1366 MO_Fahrzeugabstellzeit_Status 0 "Abstellzeit_nicht_berechnet" 1 "Abstellzeit_berechnet" 2 "Abstellzeit_Minimalwert" 3 "Abstellzeit_ungültig" ;
VAL_ 1366 MO_HV_Auszeit_Status 0 "Abstellzeit_nicht_berechnet" 1 "Abstellzeit_berechnet" 2 "Abstellzeit_Minimalwert" 3 "Abstellzeit_ungültig" ;
VAL_ 1366 MO_Fahrzeugabstellzeit 254 "Init" 255 "Fehler" ;
VAL_ 1366 MO_HV_Auszeit 510 "Init" 511 "Fehler" ;
VAL_ 1366 MO_Verbau_StartSys_Ritzelstarter 0 "nicht_verbaut" 1 "verbaut" ;
VAL_ 1366 MO_Verbau_StartSys_EM_MV 0 "nicht_verbaut" 1 "verbaut" ;
VAL_ 1366 MO_Verbau_StartSys_EM_HV 0 "nicht_verbaut" 1 "verbaut" ;
VAL_ 1366 MO_Verbau_StartSys_RSG_NV 0 "nicht_verbaut" 1 "verbaut" ;
VAL_ 1366 MO_Verbau_StartSys_Q_Diode 0 "nicht_verbaut" 1 "verbaut" ;
VAL_ 1366 MO_Verbau_StartSys_RSG_MV 0 "nicht_verbaut" 1 "verbaut" ;
VAL_ 1366 MO_Ziel_SoC_Fremdladung 254 "Init" ;
VAL_ 2589283475 SCR_Zustand 0 "Initialisierung" 1 "Normale_Funktion" 2 "Hinweis_Fuellstand" 3 "Warnstufe_1" 4 "Warnstufe_2" 5 "Systemfehler_1" 6 "Systemfehler_2" 7 "Schraeglage" 8 "Gefrorenes_Medium" 9 "Keine_RRW_Anzeige" 10 "AdBlue_pruefen_RRW_deaktiv" 11 "AdBlue_pruefen_RRW_aktiv" 12 "reserved" 13 "reserved" 14 "reserved" 15 "reserved" ;
VAL_ 2589283475 SCR_Retriggersignal 0 "Retrigger_nicht_aktiv" 1 "Retrigger_aktiv" ;
VAL_ 2589283475 SCR_Nachfuellmenge_min 127 "Initwert" ;
VAL_ 2589283475 SCR_Nachfuellmenge_max 255 "Initwert" ;
VAL_ 2589283475 SCR_Nachfuellmenge_Einheit 0 "Liter" 1 "Gallone (US)" 2 "Gallone (UK)" 3 "reserved" ;
VAL_ 2589283475 SCR_Einheit 0 "km" 1 "miles" ;
VAL_ 2589283475 SCR_Fuellstand 127 "Initwert" ;
VAL_ 1367 Mo_Empf_Red_Genlast 0 "Keine_Empfehlung_Lastredukt_Gen" 1 "Empfehlung_zur_Lastreduktion_Gen" ;
VAL_ 1367 MO_Bordnetz_Anf 0 "Init" 1 "Max_Last" 2 "Max_Last_Verbraucher_aufschalt" 3 "Streckenprognose_verfuegbar" ;
VAL_ 1367 MO_Strecke_Reg_Anf 63 "Init" ;
VAL_ 1367 MO_FestSpannungsAnf 0 "keine_Anforderung" 1 "Anforderung_Aktiv" ;
VAL_ 1367 MO_El_Grundlast_Anf 0 "keine_Anforderung" 1 "Anforderung_aktiv" ;
VAL_ 1367 MO_Kaltstarttemperatur 254 "Init" 255 "Fehler" ;
VAL_ 1367 MO_Kaltstartleistung_Anf 126 "Init" 127 "Fehler" ;
VAL_ 1367 MO_Lastabwurf 0 "Stufe_0" 1 "Stufe_1" 2 "Stufe_2" 3 "Stufe_3" ;
VAL_ 1367 MO_Freilauf_Charisma_FahrPr 0 "keine_Funktion" 1 "Programm_1" 2 "Programm_2" 3 "Programm_3" 4 "Programm_4" 5 "Programm_5" 6 "Programm_6" 7 "Programm_7" 8 "Programm_8" 9 "Programm_9" 10 "Programm_10" 11 "Programm_11" 12 "Programm_12" 13 "Programm_13" 14 "Programm_14" 15 "Programm_15" ;
VAL_ 1367 MO_Freilauf_Charisma_Status 0 "Init" 1 "verfuegbar" 2 "nicht_verfuegbar" 3 "asynchron_durch_Fahrerwunsch" ;
VAL_ 1367 AGK_Charisma_Status 0 "Init" 1 "verfuegbar" 2 "nicht_verfuegbar" 3 "asynchron_durch_Fahrerwunsch" ;
VAL_ 1367 AGK_Charisma_FahrPr 0 "keine_Funktion" 1 "Programm_1" 2 "Programm_2" 3 "Programm_3" 4 "Programm_4" 5 "Programm_5" 6 "Programm_6" 7 "Programm_7" 8 "Programm_8" 9 "Programm_9" 10 "Programm_10" 11 "Programm_11" 12 "Programm_12" 13 "Programm_13" 14 "Programm_14" 15 "Programm_15" ;
VAL_ 706 MO_Anzeige_StSt_Text 0 "keine_Anzeige" 1 "Systemfehler" 2 "Motor_manuell_starten" 3 "Rueckmeldung_durch_Fahrstufe_einlegen" 4 "Zuendungsabschaltwarnung_Timerstart" 5 "Zum_Motorstart_Bremse_treten" 6 "StSt_Aktivierung_nicht_moeglich_auf_Grund_Fahrprogramm" ;
VAL_ 706 MO_Anzeige_StSt_Symbol 0 "keine_Anzeige" 1 "StSt_aktiv" 2 "Motorlauf_noetig" 3 "Fahrer_temporaer_abwesend" 4 "Fahrer_vielleicht_anwesend" ;
VAL_ 706 MO_ADR_Status 0 "nicht_aktiv" 1 "ADR_angefordert" 2 "ADR_aktiv" 3 "ADR_Fehler" ;
VAL_ 706 MO_AGA_Sound_Texte 0 "keine_Anzeige" 1 "Sound_off" 2 "Sound_on" ;
VAL_ 706 MO_Anzeige_FMAus_Text 0 "keine_Anzeige" 1 "FMAus_Systemfehler" ;
VAL_ 706 MO_KEF_Status 0 "KEF_inaktiv" 1 "KEF_aktiv" ;
VAL_ 706 PEA_Texte 0 "Keine_Anzeige" 1 "PEA_Fahreruebernahme_noetig" 2 "PEA_Reku_nicht_verfuegbar" ;
VAL_ 706 TSK_Ueberstimmt_vMax_FahrerInfo 0 "nicht_ueberstimmbar" 1 "ueberstimmbar" 2 "ueberstimmt" ;
VAL_ 706 MO_VREG_Status 0 "Verzoegerung_nicht_verfuegbar" 1 "Verzoegerung_moeglich" 2 "Verzoegerung_aktiv" 3 "reserved" ;
VAL_ 706 MO_Rekuperationsstufe 0 "keine_Anzeige" 1 "Rekuperationsstufe_1" 2 "Rekuperationsstufe_2" 3 "Rekuperationsstufe_3" 4 "Rekuperationsstufe_4" 5 "Rekuperationsstufe_5" 6 "Rekuperationsstufe_auto" 7 "Init" ;
VAL_ 706 TSK_Einheit_vMax_FahrerInfo 0 "km_h" 1 "mph" ;
VAL_ 706 TSK_Status_vMax_FahrerInfo 0 "keine_Anzeige" 1 "Anzeige_im_Fahrzeugstatus" 2 "PopUp_ohne_Gong__Eintrag_FhzStat" 3 "PopUp_mit_Gong__Eintrag_FhzStat" ;
VAL_ 706 MO_SREG_Status 0 "Standreg_nicht_verfuegbar" 1 "Standreg_moeglich" 2 "Standreg_abbruch" 3 "Standreg_aktiv" 4 "Standreg_aktiv_Konditionierung" 5 "Standreg_beendet" 6 "reserved" 7 "reserved" ;
VAL_ 706 MO_SREG_Beladung 62 "Init" 63 "Fehler" ;
VAL_ 706 MO_Anz_Kuehlerluefter 0 "Kein_KuehlerluefterNachlauf" 1 "Text_Luefternachlauf_aktiv" 2 "Text_Luefternachlauf_DPF_aktiv" 3 "Platzhalter_weitere_Signale" 4 "Platzhalter_weitere_Signale" 5 "Platzhalter_weitere_Signale" 6 "Platzhalter_weitere_Signale" 7 "Platzhalter_weitere_Signale" ;
VAL_ 706 MO_EM_Ueberhitzungswarnung 0 "keine_Anzeige" 1 "EM_heiss_langsam_Fahren" 2 "EM_heiss_Geschw_begrenzt" 3 "EM_heiss_Anhalten" ;
VAL_ 706 MO_ElAntrieb_Abschleppwarnung 0 "keine_Anzeige" 1 "Abschleppen_nur_vorne_angehoben" 2 "Abschleppen_nur_hinten_angehoben" 3 "Fahrzeug_nicht_abschleppen" ;
VAL_ 706 TSK_vMax_FahrerInfo 0 "Init___kein_Wert" ;
VAL_ 269 MO_Mom_Soll_Roh 1022 "Init" ;
VAL_ 269 MO_Mom_Ist_Summe 1022 "Init" ;
VAL_ 269 MO_Mom_Traegheit_Summe 1022 "Init" ;
VAL_ 269 MO_Mom_Soll_gefiltert 1022 "Init" ;
VAL_ 269 MO_Mom_Schub 510 "Init" ;
VAL_ 269 MO_Status_Normalbetrieb_01 0 "kein_Normalbetrieb" 1 "Normalbetrieb_erreicht" ;
VAL_ 269 MO_erste_Ungenauschwelle 0 "genau" 1 "Momente ungenauer >8%" ;
VAL_ 269 MO_QBit_Motormomente 0 "gueltiger_Wert" 1 "Ersatz_Init_oder_Fehlerwert" ;
VAL_ 269 MO_Mom_neg_verfuegbar 510 "Init" 511 "Fehler" ;
VAL_ 269 MO_Mom_Begr_Fahr 510 "Init" 511 "Fehler" ;
VAL_ 269 MO_Mom_Begr_Schalt 1022 "Init" ;
VAL_ 269 MO_QBit_Drehzahl_01 0 "gueltiger_Wert" 1 "Ersatz_Init_oder_Fehlerwert" ;
VAL_ 269 MO_HYB_EMode_Info 0 "Normal_Mode" 1 "Depleting_Mode" 2 "Charge_Mode" 3 "Sonder_Schaltprogramm" ;
VAL_ 269 MO_HYB_max_ind_VM_Mom_02 254 "Init" 255 "Fehler" ;
VAL_ 269 MO_HYB_Zielzustand 0 "Init" 1 "Leerlauf_VM" 2 "hybridisch_Fahren" 3 "Fahren_EM" 4 "Fahrbereitschaft_EM" 5 "Fahrbereitschaft_VM" 7 "Fehler" ;
VAL_ 269 MO_HYB_Modus_Ankopplung_VM 0 "Schlupfankopplung" 1 "Direktankopplung" ;
VAL_ 269 MO_HYB_Freigabe_VM_Eingr 0 "kein_Wunsch" 1 "Eingriff_nicht_freigegeben" 2 "Eingriff_erwuenscht" ;
VAL_ 269 MO_HYB_Sollstatus_K0 0 "geschlossen" 1 "schlupfend" ;
VAL_ 269 MO_HYB_Komfortstufe 0 "normal" 1 "dynamisch" ;
VAL_ 269 MO_HYB_VM_bereit 0 "VM_nicht_bereit" 1 "VM_bereit" ;
VAL_ 269 MO_HYB_Stoppmodus 0 "Softstopp" 1 "Dynamikstopp" ;
VAL_ 269 MO_HYB_LowSpeedModus 0 "LowSpeed_mit_LLDZ" 1 "LowSpeed_ohne_LLDZ" ;
VAL_ 269 MO_HYB_Schaltverhinderung 0 "keine_Schaltverhinderung" 1 "Schaltverhinderung" ;
VAL_ 269 MO_HYB_E_Faktor 0 "null" 1 "plus_1" 2 "plus_2" 3 "plus_3" 4 "plus_4" 5 "plus_5" 6 "plus_6" 7 "plus_7" 8 "minus_8" 9 "minus_7" 10 "minus_6" 11 "minus_5" 12 "minus_4" 13 "minus_3" 14 "minus_2" 15 "minus_1" ;
VAL_ 269 MO_HYB_VM_Mom_oE_02 254 "Init" 255 "Fehler" ;
VAL_ 269 MO_EM1_SollDrehzahl 32767 "Init" ;
VAL_ 269 MO_Luftpfad_Verzugszeit_praed 0 "keine_Praediktion" ;
VAL_ 269 MO_EM2_SollDrehzahl 32767 "Init" ;
VAL_ 269 MO_TNW_Min_Strom_Lim 8190 "Init" ;
VAL_ 269 MO_TNW_Max_Strom_Lim 8190 "Init" ;
